VERSION ""

NS_ :

BS_:
BU_: ME SC01 BMS01 BMS PT

BO_ 1664 SC01_DebugFastMpex: 8 SC01
 SG_ selfTestFaultCntrCtrl_SC01 m11 : 23|8@0+ (1,0) [0|0] ""  PT
 SG_ cmbASICFault_SC01 m11 : 15|8@0+ (1,0) [0|0] ""  PT
 SG_ DIGIO_PYRO_LSD_EN_SC01 m2 : 12|1@0+ (1,0) [0|0] ""  PT
 SG_ mainUcExtIsoResistance_SC01 m10 : 55|16@0+ (1,0) [0|0] "KOhm"  PT
 SG_ BMS_C38_AR2MsgFault_SC01 m10 : 47|2@0+ (1,0) [0|0] ""  PT
 SG_ stateCoolant_SC01 m10 : 45|1@0+ (1,0) [0|0] ""  PT
 SG_ stateThermalEvent_SC01 m10 : 44|1@0+ (1,0) [0|0] ""  PT
 SG_ stateCANTx_SC01 m10 : 43|1@0+ (1,0) [0|0] ""  PT
 SG_ CANTxFaultTriggerFailed_SC01 m10 : 42|1@0+ (1,0) [0|0] ""  PT
 SG_ CANTxBMS1ST3MsgFault_SC01 m10 : 10|1@0+ (1,0) [0|0] ""  PT
 SG_ CANTxBMSDispReqMsgFault_SC01 m10 : 9|1@0+ (1,0) [0|0] ""  PT
 SG_ CANTxHVBatMsgFault_SC01 m10 : 8|1@0+ (1,0) [0|0] ""  PT
 SG_ mainUcCntrCtrlReq_SC01 m10 : 41|2@0+ (1,0) [0|0] ""  PT
 SG_ mainUcCntrWeldState_SC01 m10 : 39|4@0+ (1,0) [0|0] ""  PT
 SG_ safetyUcCntrState_SC01 m10 : 33|2@0+ (1,0) [0|0] ""  PT
 SG_ mainUcCntrState_SC01 m10 : 35|2@0+ (1,0) [0|0] ""  PT
 SG_ safetyCANMsg4Fault_SC01 m10 : 31|4@0+ (1,0) [0|0] ""  PT
 SG_ safetyCANMsg3Fault_SC01 m10 : 27|4@0+ (1,0) [0|0] ""  PT
 SG_ safetyCANMsg2Fault_SC01 m10 : 23|4@0+ (1,0) [0|0] ""  PT
 SG_ safetyCANMsg1Fault_SC01 m10 : 19|4@0+ (1,0) [0|0] ""  PT
 SG_ cmbBalancingDesired_SC01 m10 : 15|1@0+ (1,0) [0|0] ""  PT
 SG_ DIGIO_GPIO1_ON_SC01 m2 : 10|1@0+ (1,0) [0|0] ""  PT
 SG_ DIGIO_ZDW_LSD_EN_SC01 m2 : 11|1@0+ (1,0) [0|0] ""  PT
 SG_ currentShortCircuit_SC01 m2 : 9|1@0+ (1,0) [0|0] ""  PT
 SG_ contactorCntrSelfTest_SC01 m10 : 14|4@0+ (1,0) [0|15] ""  PT
 SG_ maxBrickVoltage_SC01 m11 : 39|16@0+ (0.0001,0) [0|6.5] "V"  PT
 SG_ minBrickVoltage_SC01 m11 : 55|16@0+ (0.0001,0) [0|6.5] "V"  PT
 SG_ cmbLastUpdateTime_SC01 m0 : 55|8@0+ (2,0) [0|500] "ms"  PT
 SG_ weldCheckState_SC01 m2 : 15|3@0+ (1,0) [0|0] ""  PT
 SG_ debugFastMpex_SC01 M : 7|8@0+ (1,0) [0|0] ""  PT
 SG_ SPIRxTxTimeAllPckts_SC01 m0 : 63|8@0+ (2,0) [0|500] "ms"  PT
 SG_ sleepRqASW_SC01 m2 : 8|1@0+ (1,0) [0|0] ""  PT
 SG_ prechgCtr1OnReqASW_SC01 m1 : 27|1@0+ (1,0) [0|0] ""  PT
 SG_ negCtr1OnReqASW_SC01 m1 : 25|1@0+ (1,0) [0|0] ""  PT
 SG_ posCtr1OnReqASW_SC01 m1 : 26|1@0+ (1,0) [0|0] ""  PT
 SG_ key_SC01 m1 : 24|1@0+ (1,0) [0|0] ""  PT
 SG_ stateContactorControl_SC01 m0 : 41|1@0+ (1,0) [0|0] ""  PT
 SG_ DIGIO_MULTIPLEX_m101_S3_SC01 m0 : 40|1@0+ (1,0) [0|0] ""  PT
 SG_ analogCntrPwrPlus_SC01 m1 : 15|8@0+ (0.2,0) [0|50] "V"  PT
 SG_ weldedState_SC01 m11 : 25|2@0+ (1,0) [0|3] ""  PT
 SG_ stateVoltage_SC01 m0 : 43|1@0+ (1,0) [0|0] ""  PT
 SG_ stateTemperature_SC01 m0 : 44|1@0+ (1,0) [0|0] ""  PT
 SG_ stateSelfTest_SC01 m0 : 45|1@0+ (1,0) [0|0] ""  PT
 SG_ stateHVIL_SC01 m0 : 46|1@0+ (1,0) [0|0] ""  PT
 SG_ stateCurrent_SC01 m0 : 47|1@0+ (1,0) [0|0] ""  PT
 SG_ stateCrash2_SC01 m0 : 36|1@0+ (1,0) [0|0] ""  PT
 SG_ stateCrash1_SC01 m0 : 37|1@0+ (1,0) [0|0] ""  PT
 SG_ stateContactors_SC01 m0 : 38|1@0+ (1,0) [0|0] ""  PT
 SG_ stateCANRx_SC01 m0 : 39|1@0+ (1,0) [0|0] ""  PT
 SG_ itemState_SC01 m0 : 35|4@0+ (1,0) [0|0] ""  PT
 SG_ DIGIO_SAFETY_GPIO0_SC01 m0 : 8|1@0+ (1,0) [0|0] ""  PT
 SG_ DIGIO_SC_LED501_CONTROL_SC01 m0 : 9|1@0+ (1,0) [0|0] ""  PT
 SG_ DIGIO_LNK_ISO_TST_SW_SC01 m0 : 10|1@0+ (1,0) [0|0] ""  PT
 SG_ DIGIO_SC_LED500_CONTROL_SC01 m0 : 11|1@0+ (1,0) [0|0] ""  PT
 SG_ DIGIO_POS_CNTR1_ON_SC01 m0 : 12|1@0+ (1,0) [0|0] ""  PT
 SG_ DIGIO_NEG_CNTR3_ON_SC01 m0 : 13|1@0+ (1,0) [0|0] ""  PT
 SG_ DIGIO_PRECHG_REL2_ON_SC01 m0 : 14|1@0+ (1,0) [0|0] ""  PT
 SG_ DIGIO_NEG_ISO_TEST_SW_SC01 m0 : 15|1@0+ (1,0) [0|0] ""  PT
 SG_ DIGIO_PRECHG_REL1_ON_SC01 m0 : 16|1@0+ (1,0) [0|0] ""  PT
 SG_ DIGIO_POS_ISO_TEST_SC01 m0 : 17|1@0+ (1,0) [0|0] ""  PT
 SG_ DIGIO_HVIL_PWM_SC01 m0 : 18|1@0+ (1,0) [0|0] ""  PT
 SG_ DIGIO_CNTR_HISIDE_ON_SC_SC01 m0 : 19|1@0+ (1,0) [0|0] ""  PT
 SG_ DIGIO_CRASH_DETECT_SC01 m0 : 20|1@0+ (1,0) [0|0] ""  PT
 SG_ DIGIO_NEG_CNTR2_ON_SC01 m0 : 21|1@0+ (1,0) [0|0] ""  PT
 SG_ DIGIO_NEG_CNTR1_ON_SC01 m0 : 22|1@0+ (1,0) [0|0] ""  PT
 SG_ DIGIO_POS_CNTR3_ON_SC01 m0 : 23|1@0+ (1,0) [0|0] ""  PT
 SG_ DIGIO_POS_CNTR2_ON_SC01 m0 : 24|1@0+ (1,0) [0|0] ""  PT
 SG_ DIGIO_MULTIPLEX_m101_S2_SC01 m0 : 25|1@0+ (1,0) [0|0] ""  PT
 SG_ DIGIO_MULTIPLEX_8TO1_S1_SC01 m0 : 26|1@0+ (1,0) [0|0] ""  PT
 SG_ DIGIO_CNTR_CLOSE_OK_CHCKD_SC01 m0 : 27|1@0+ (1,0) [0|0] ""  PT
 SG_ DIGIO_MULTIPLEX_8TO1_S2_SC01 m0 : 28|1@0+ (1,0) [0|0] ""  PT
 SG_ DIGIO_CNTR_CLOSE_OK_SC01 m0 : 29|1@0+ (1,0) [0|0] ""  PT
 SG_ DIGIO_MULTIPLEX_m101_S1_SC01 m0 : 30|1@0+ (1,0) [0|0] ""  PT
 SG_ DIGIO_CNTR_HISIDE_ON_CHCKD_SC01 m0 : 31|1@0+ (1,0) [0|0] ""  PT
 SG_ posPack_SC01 m2 : 23|16@0+ (0.04,-1250) [-1250|1250] "V"  PT
 SG_ posLink_SC01 m2 : 55|16@0+ (0.04,-1250) [-1250|1371.4] "V"  PT
 SG_ negPack_SC01 m2 : 39|16@0+ (0.04,-1250) [-1250|1250] "V"  PT
 SG_ negLink_SC01 m1 : 39|16@0+ (0.04,-1250) [-1250|1371.4] "V"  PT
 SG_ hallCurrent_SC01 m1 : 23|12@0+ (0.6,-1200) [-1200|1257] "A"  PT
 SG_ analogCntrPwrPlusISense_SC01 m1 : 63|8@0+ (0.05,0) [0|12.5] "A"  PT
 SG_ analogCntrPwrPlusSwitched_SC01 m1 : 55|8@0+ (0.2,0) [0|50] "V"  PT
 SG_ BIT_ANALOG_REF_FAIL_SC01 m3 : 8|1@0+ (1,0) [0|0] ""  PT
 SG_ BIT_ANALOG_ADCDRIVER_FAIL_SC01 m3 : 9|1@0+ (1,0) [0|0] ""  PT
 SG_ BIT_ANALOG_MUX910_HW_SC01 m3 : 10|1@0+ (1,0) [0|0] ""  PT
 SG_ BIT_ANALOG_MUX960_HW_SC01 m3 : 11|1@0+ (1,0) [0|0] ""  PT
 SG_ BIT_ANALOG_MUX301_HW_SC01 m3 : 12|1@0+ (1,0) [0|0] ""  PT
 SG_ BIT_ANALOG_MUX440_HW_SC01 m3 : 13|1@0+ (1,0) [0|0] ""  PT
 SG_ BIT_ANALOG_5VA_FAIL_SC01 m3 : 14|1@0+ (1,0) [0|0] ""  PT
 SG_ BIT_ANALOG_HV_SIGN_SC01 m3 : 15|1@0+ (1,0) [0|0] ""  PT
 SG_ BIT_CAN_ISENSE01_MIA_SC01 m3 : 24|1@0+ (1,0) [0|0] ""  PT
 SG_ BIT_CAN_ISENSE02_MIA_SC01 m3 : 25|1@0+ (1,0) [0|0] ""  PT
 SG_ BIT_CAN_ISENSE03_MIA_SC01 m3 : 26|1@0+ (1,0) [0|0] ""  PT
 SG_ BIT_CAN_ISENSE04_MIA_SC01 m3 : 27|1@0+ (1,0) [0|0] ""  PT
 SG_ BIT_CAN_ISENSE05_MIA_SC01 m3 : 28|1@0+ (1,0) [0|0] ""  PT
 SG_ BIT_CAN_PT_MIA_SC01 m3 : 29|1@0+ (1,0) [0|0] ""  PT
 SG_ BIT_CAN_PT_CRC_SC01 m3 : 30|1@0+ (1,0) [0|0] ""  PT
 SG_ BIT_CAN_PT_ALIVE_SC01 m3 : 31|1@0+ (1,0) [0|0] ""  PT
 SG_ BIT_CAN_SAFETYLIN_MIA_SC01 m3 : 32|1@0+ (1,0) [0|0] ""  PT
 SG_ BIT_CAN_SAFETYLIN_SHUTDOWN_SC01 m3 : 33|1@0+ (1,0) [0|0] ""  PT
 SG_ BIT_CMB_GPIO_SHORT_SC01 m3 : 40|1@0+ (1,0) [0|0] ""  PT
 SG_ BIT_CMB_C2S_LEAK_SC01 m3 : 41|1@0+ (1,0) [0|0] ""  PT
 SG_ BIT_CMB_SENSE_LINE_SC01 m3 : 42|1@0+ (1,0) [0|0] ""  PT
 SG_ BIT_CMB_SUMOFCELL_CHECK_SC01 m3 : 43|1@0+ (1,0) [0|0] ""  PT
 SG_ BIT_CMB_DRIVER_TIMING_SC01 m3 : 44|1@0+ (1,0) [0|0] ""  PT
 SG_ BIT_CMB_CLEAR_SC01 m3 : 45|1@0+ (1,0) [0|0] ""  PT
 SG_ BIT_CMB_SELFTEST_SC01 m3 : 46|1@0+ (1,0) [0|0] ""  PT
 SG_ BIT_CMB_GPIO_OPEN_SC01 m3 : 47|1@0+ (1,0) [0|0] ""  PT
 SG_ BIT_CMB_CELLV_RANGE_ERR_SC01 m3 : 48|1@0+ (1,0) [0|0] ""  PT
 SG_ BIT_CMB_ADOL_CHECK_SC01 m3 : 49|1@0+ (1,0) [0|0] ""  PT
 SG_ BIT_CMB_BALANCING_STUCK_SC01 m3 : 50|1@0+ (1,0) [0|0] ""  PT
 SG_ BIT_CMB_SUPPLY_SC01 m3 : 51|1@0+ (1,0) [0|0] ""  PT
 SG_ BIT_CMB_DEFECT_SC01 m3 : 52|1@0+ (1,0) [0|0] ""  PT
 SG_ BIT_CMB_PEC_ERROR_SC01 m3 : 53|1@0+ (1,0) [0|0] ""  PT
 SG_ BIT_CMB_GPIO_ERROR_SC01 m3 : 54|1@0+ (1,0) [0|0] ""  PT
 SG_ BIT_CMB_DIGTLREDNCY_LF_SC01 m3 : 55|1@0+ (1,0) [0|0] ""  PT
 SG_ BIT_CCTRL_SELFTEST_SC01 m4 : 8|1@0+ (1,0) [0|0] ""  PT
 SG_ BIT_CCTRL_DRIVER_FAULT_SC01 m4 : 9|1@0+ (1,0) [0|0] ""  PT
 SG_ BIT_CCTRL_HISIDE_STCLSD_SC01 m4 : 10|1@0+ (1,0) [0|0] ""  PT
 SG_ BIT_CCTRL_LOSIDE_STCLSD_SC01 m4 : 11|1@0+ (1,0) [0|0] ""  PT
 SG_ BIT_CCTRL_HISIDE_STUCK_OPEN_SC01 m4 : 12|1@0+ (1,0) [0|0] ""  PT
 SG_ BIT_CCTRL_HVOLTAGE_COND_SC01 m4 : 13|1@0+ (1,0) [0|0] ""  PT
 SG_ BIT_CCTRL_POS1_OPENCIRC_SC01 m4 : 14|1@0+ (1,0) [0|0] ""  PT
 SG_ BIT_CCTRL_NEG1_OPENCIRC_SC01 m4 : 15|1@0+ (1,0) [0|0] ""  PT
 SG_ BIT_CCTRL_PRECHG1_OPENCIRC_SC01 m4 : 16|1@0+ (1,0) [0|0] ""  PT
 SG_ BIT_CCTRL_POS2_OPENCIRC_SC01 m4 : 17|1@0+ (1,0) [0|0] ""  PT
 SG_ BIT_CCTRL_NEG2_OPENCIRC_SC01 m4 : 18|1@0+ (1,0) [0|0] ""  PT
 SG_ BIT_CCTRL_LOSDE_STOPEN_SC01 m4 : 19|1@0+ (1,0) [0|0] ""  PT
 SG_ BIT_CCTRL_POS3_OPENCIRC_SC01 m4 : 20|1@0+ (1,0) [0|0] ""  PT
 SG_ BIT_CCTRL_PRECHG2_OPENCIRC_SC01 m4 : 21|1@0+ (1,0) [0|0] ""  PT
 SG_ BIT_CCTRL_ITEM_OFF_OPEN_SC01 m4 : 22|1@0+ (1,0) [0|0] ""  PT
 SG_ BIT_CCTRL_UNEXPECTED_OPEN_SC01 m4 : 23|1@0+ (1,0) [0|0] ""  PT
 SG_ BIT_CNTR_ISOLATION_SC01 m4 : 24|1@0+ (1,0) [0|0] ""  PT
 SG_ BIT_CNTR_ISO_AND_POT_WELD_SC01 m4 : 25|1@0+ (1,0) [0|0] ""  PT
 SG_ BIT_CNTR_POS1_WELDED_SC01 m4 : 26|1@0+ (1,0) [0|0] ""  PT
 SG_ BIT_CNTR_NEG1_WELDED_SC01 m4 : 27|1@0+ (1,0) [0|0] ""  PT
 SG_ BIT_CNTR_POS2_WELDED_SC01 m4 : 28|1@0+ (1,0) [0|0] ""  PT
 SG_ BIT_CNTR_NEG2_WELDED_SC01 m4 : 29|1@0+ (1,0) [0|0] ""  PT
 SG_ BIT_CNTR_POS3_WELDED_SC01 m4 : 30|1@0+ (1,0) [0|0] ""  PT
 SG_ BIT_CNTR_NEG3_WELDED_SC01 m4 : 31|1@0+ (1,0) [0|0] ""  PT
 SG_ BIT_CNTR_P_ANDOR_N_WELD_SC01 m4 : 32|1@0+ (1,0) [0|0] ""  PT
 SG_ BIT_CNTR_HIGH_CY_SC01 m4 : 33|1@0+ (1,0) [0|0] ""  PT
 SG_ BIT_CNTR_WELDCHECK_TIMEOUT_SC01 m4 : 34|1@0+ (1,0) [0|0] ""  PT
 SG_ BIT_CURRENT_PLAUSIBILITY_SC01 m4 : 40|1@0+ (1,0) [0|0] ""  PT
 SG_ BIT_CURRENT_OVERCHARGE_SC01 m4 : 41|1@0+ (1,0) [0|0] ""  PT
 SG_ BIT_CURRENT_OVERDISCHARGE_SC01 m4 : 42|1@0+ (1,0) [0|0] ""  PT
 SG_ BIT_CURRENT_ISENSE1_INVALID_SC01 m4 : 43|1@0+ (1,0) [0|0] ""  PT
 SG_ BIT_CURRENT_ISENSE2_INVALID_SC01 m4 : 44|1@0+ (1,0) [0|0] ""  PT
 SG_ BIT_CURRENT_ISENSE3_INVALID_SC01 m4 : 45|1@0+ (1,0) [0|0] ""  PT
 SG_ BIT_CURRENT_ISENSE4_INVALID_SC01 m4 : 46|1@0+ (1,0) [0|0] ""  PT
 SG_ BIT_CURRENT_ISENSE5_INVALID_SC01 m4 : 47|1@0+ (1,0) [0|0] ""  PT
 SG_ BIT_CURRENT_HALL_INVALID_SC01 m4 : 48|1@0+ (1,0) [0|0] ""  PT
 SG_ BIT_CURRENT_OFFSET_FAULT_SC01 m4 : 49|1@0+ (1,0) [0|0] ""  PT
 SG_ BIT_FLUXGATE1_CURRENT_FAULT_SC01 m5 : 8|1@0+ (1,0) [0|0] ""  PT
 SG_ BIT_FLUXGATE_12V_LOW_SC01 m5 : 18|1@0+ (1,0) [0|0] ""  PT
 SG_ BIT_HALL_INVALID_SC01 m5 : 24|1@0+ (1,0) [0|0] ""  PT
 SG_ BIT_HALL_PWR_FAIL_LO_SC01 m5 : 25|1@0+ (1,0) [0|0] ""  PT
 SG_ BIT_HALL_SENSELO_SC01 m5 : 26|1@0+ (1,0) [0|0] ""  PT
 SG_ BIT_HALL_SENSEHI_SC01 m5 : 27|1@0+ (1,0) [0|0] ""  PT
 SG_ BIT_HVIL_HW_FAULT_SC01 m5 : 40|1@0+ (1,0) [0|0] ""  PT
 SG_ BIT_HVIL_OPEN_CIRCUIT_SC01 m5 : 41|1@0+ (1,0) [0|0] ""  PT
 SG_ BIT_HVIL_SHORT_SUPPLY_SC01 m5 : 42|1@0+ (1,0) [0|0] ""  PT
 SG_ BIT_HVIL_SHORT_CHASSIS_SC01 m5 : 43|1@0+ (1,0) [0|0] ""  PT
 SG_ BIT_HVIL_RESISTANCE_HIGH_SC01 m5 : 44|1@0+ (1,0) [0|0] ""  PT
 SG_ BIT_HVIL_SHORT_CIRCUIT_SC01 m5 : 45|1@0+ (1,0) [0|0] ""  PT
 SG_ BIT_ISASHUNT1_CURRENT_FAULT_SC01 m7 : 24|1@0+ (1,0) [0|0] ""  PT
 SG_ BIT_ISASHUNT2_CURRENT_FAULT_SC01 m7 : 25|1@0+ (1,0) [0|0] ""  PT
 SG_ BIT_ISASHUNT3_CURRENT_FAULT_SC01 m7 : 26|1@0+ (1,0) [0|0] ""  PT
 SG_ BIT_ISASHUNT4_CURRENT_FAULT_SC01 m7 : 27|1@0+ (1,0) [0|0] ""  PT
 SG_ BIT_ISASHUNT5_CURRENT_FAULT_SC01 m7 : 28|1@0+ (1,0) [0|0] ""  PT
 SG_ BIT_ISASHUNT1_CHARGE_FAULT_SC01 m7 : 29|1@0+ (1,0) [0|0] ""  PT
 SG_ BIT_ISASHUNT2_CHARGE_FAULT_SC01 m7 : 30|1@0+ (1,0) [0|0] ""  PT
 SG_ BIT_ISASHUNT3_CHARGE_FAULT_SC01 m7 : 31|1@0+ (1,0) [0|0] ""  PT
 SG_ BIT_ISASHUNT4_CHARGE_FAULT_SC01 m7 : 32|1@0+ (1,0) [0|0] ""  PT
 SG_ BIT_ISASHUNT5_CHARGE_FAULT_SC01 m7 : 33|1@0+ (1,0) [0|0] ""  PT
 SG_ BIT_ISASHUNT_SUPPLY_LOW_SC01 m7 : 34|1@0+ (1,0) [0|0] ""  PT
 SG_ BIT_LINK_POS_HW_FAIL_SC01 m7 : 40|1@0+ (1,0) [0|0] ""  PT
 SG_ BIT_LINK_NEG_HW_FAIL_SC01 m7 : 41|1@0+ (1,0) [0|0] ""  PT
 SG_ BIT_PUMP_LIN_FAILURE_SC01 m8 : 8|1@0+ (1,0) [0|0] ""  PT
 SG_ BIT_PUMP_OVERTEMPERATURE_SC01 m8 : 9|1@0+ (1,0) [0|0] ""  PT
 SG_ BIT_PUMP_SPEED_HIGH_SC01 m8 : 10|1@0+ (1,0) [0|0] ""  PT
 SG_ BIT_PUMP_SPEED_LOW_SC01 m8 : 11|1@0+ (1,0) [0|0] ""  PT
 SG_ BIT_PUMP_DRY_RUN_SC01 m8 : 12|1@0+ (1,0) [0|0] ""  PT
 SG_ BIT_SBC_VCORE_OOR_SC01 m6 : 8|1@0+ (1,0) [0|0] ""  PT
 SG_ BIT_SBC_SELFTEST_SC01 m6 : 9|1@0+ (1,0) [0|0] ""  PT
 SG_ BIT_SBC_INIT_SC01 m6 : 10|1@0+ (1,0) [0|0] ""  PT
 SG_ BIT_SBC_WATCHDOG_SC01 m6 : 11|1@0+ (1,0) [0|0] ""  PT
 SG_ BIT_SBC_FECBITFLIP_SC01 m6 : 12|1@0+ (1,0) [0|0] ""  PT
 SG_ BIT_SBC_VREUV_SC01 m6 : 13|1@0+ (1,0) [0|0] ""  PT
 SG_ BIT_SBC_FAILSAFE_SC01 m6 : 14|1@0+ (1,0) [0|0] ""  PT
 SG_ BIT_SBC_VAUX_OOR_SC01 m6 : 15|1@0+ (1,0) [0|0] ""  PT
 SG_ BIT_SBC_VCCA_OOR_SC01 m6 : 16|1@0+ (1,0) [0|0] ""  PT
 SG_ BIT_SBC_FCRBM_OOR_SC01 m6 : 17|1@0+ (1,0) [0|0] ""  PT
 SG_ BIT_SBC_FLT_ERR_CNTR_SC01 m6 : 18|1@0+ (1,0) [0|0] ""  PT
 SG_ BIT_SBC_FS0B_FAIL_SC01 m6 : 19|1@0+ (1,0) [0|0] ""  PT
 SG_ BIT_SBC_SPI_ERRORS_SC01 m6 : 20|1@0+ (1,0) [0|0] ""  PT
 SG_ BIT_SBC_SPI_TX_FAIL_SC01 m6 : 21|1@0+ (1,0) [0|0] ""  PT
 SG_ BIT_SBC_NERROR_ACTIVE_SC01 m6 : 22|1@0+ (1,0) [0|0] ""  PT
 SG_ BIT_SELFTEST_RAM_SC01 m6 : 24|1@0+ (1,0) [0|0] ""  PT
 SG_ BIT_SELFTEST_FLASH_SC01 m6 : 25|1@0+ (1,0) [0|0] ""  PT
 SG_ BIT_SELFTEST_CLOCK_SC01 m6 : 26|1@0+ (1,0) [0|0] ""  PT
 SG_ BIT_SELFTEST_WATCHDOG_SC01 m6 : 27|1@0+ (1,0) [0|0] ""  PT
 SG_ BIT_SELFTEST_STACK_SC01 m6 : 28|1@0+ (1,0) [0|0] ""  PT
 SG_ BIT_SELFTEST_L2L3_SC01 m6 : 29|1@0+ (1,0) [0|0] ""  PT
 SG_ BIT_SELFTEST_EFUSE_SC01 m6 : 30|1@0+ (1,0) [0|0] ""  PT
 SG_ BIT_SELFTEST_EXCEPTION_SC01 m6 : 31|1@0+ (1,0) [0|0] ""  PT
 SG_ BIT_SELFTEST_5VD_FAIL_SC01 m6 : 32|1@0+ (1,0) [0|0] ""  PT
 SG_ BIT_SELFTEST_VIM_SC01 m6 : 33|1@0+ (1,0) [0|0] ""  PT
 SG_ BIT_SELFTEST_TASKTIME_SC01 m6 : 34|1@0+ (1,0) [0|0] ""  PT
 SG_ BIT_SELFTEST_RTI_SC01 m6 : 35|1@0+ (1,0) [0|0] ""  PT
 SG_ BIT_SELFTEST_ESM_SC01 m6 : 36|1@0+ (1,0) [0|0] ""  PT
 SG_ BIT_SELFTEST_IOM_SC01 m6 : 37|1@0+ (1,0) [0|0] ""  PT
 SG_ BIT_SELFTEST_SBC_SC01 m6 : 38|1@0+ (1,0) [0|0] ""  PT
 SG_ BIT_SELFTEST_STARTUP_SC01 m6 : 39|1@0+ (1,0) [0|0] ""  PT
 SG_ BIT_TEMP_MODULEOVERTEMP_SC01 m6 : 40|1@0+ (1,0) [0|0] ""  PT
 SG_ BIT_TEMP_MODULETEMP_INVALID_SC01 m6 : 41|1@0+ (1,0) [0|0] ""  PT
 SG_ BIT_TEMP_NTC_OPENWIRE_SC01 m6 : 42|1@0+ (1,0) [0|0] ""  PT
 SG_ BIT_TEMP_NTC_SHORT_SC01 m6 : 43|1@0+ (1,0) [0|0] ""  PT
 SG_ BIT_TEMP_PLAUSIBILITY_SC01 m6 : 44|1@0+ (1,0) [0|0] ""  PT
 SG_ BIT_VOLTAGE_BRICKV_INVALID_SC01 m7 : 8|1@0+ (1,0) [0|0] ""  PT
 SG_ BIT_VOLTAGE_BRICKUV_SC01 m7 : 9|1@0+ (1,0) [0|0] ""  PT
 SG_ BIT_VOLTAGE_BRICKOV_SC01 m7 : 10|1@0+ (1,0) [0|0] ""  PT
 SG_ BIT_VOLTAGE_BRICKDEEPDSCHG_SC01 m7 : 11|1@0+ (1,0) [0|0] ""  PT
 SG_ BIT_VOLTAGE_PACKV_INVALID_SC01 m7 : 12|1@0+ (1,0) [0|0] ""  PT
 SG_ BIT_VOLTAGE_PLAUSIBILITY_SC01 m7 : 13|1@0+ (1,0) [0|0] ""  PT
 SG_ BIT_VOLTAGE_CMB_PLAUSI_SC01 m7 : 14|1@0+ (1,0) [0|0] ""  PT
 SG_ BIT_VOLTAGE_SENSE_OPENWIRE_SC01 m7 : 15|1@0+ (1,0) [0|0] ""  PT
 SG_ BIT_VOLTAGE_BRICKV_FROZEN_SC01 m7 : 16|1@0+ (1,0) [0|0] ""  PT
 SG_ BIT_PUMP_BLOCK_SC01 m8 : 13|1@0+ (1,0) [0|0] ""  PT
 SG_ BIT_PUMP_SUPPLY_SC01 m8 : 14|1@0+ (1,0) [0|0] ""  PT
 SG_ BIT_PUMP_OVERCURRENT_SC01 m8 : 15|1@0+ (1,0) [0|0] ""  PT
 SG_ BIT_PUMP_ELECTRIC_SC01 m8 : 16|1@0+ (1,0) [0|0] ""  PT
 SG_ BIT_PUMP_RS_SC01 m8 : 17|1@0+ (1,0) [0|0] ""  PT
 SG_ BIT_HALL_PWR_FAIL_HI_SC01 m5 : 28|1@0+ (1,0) [0|0] ""  PT
 SG_ BIT_VOLTAGE_OUT_OF_RANGE_SC01 m7 : 17|1@0+ (1,0) [0|0] ""  PT
 SG_ BIT_ISO_OFF_TIME_SHORT_SC01 m8 : 24|1@0+ (1,0) [0|0] ""  PT
 SG_ BIT_ISO_ON_TIME_SHORT_SC01 m8 : 25|1@0+ (1,0) [0|0] ""  PT
 SG_ BIT_ISO_INTERNAL_INACTIVE_SC01 m8 : 26|1@0+ (1,0) [0|0] ""  PT
 SG_ BIT_ISO_SW_STATE_INVALID_SC01 m8 : 27|1@0+ (1,0) [0|0] ""  PT
 SG_ BIT_ISO_PACKV_SNA_SWOFF_SC01 m8 : 28|1@0+ (1,0) [0|0] ""  PT
 SG_ BIT_ISO_PACKV_SNA_SWON_SC01 m8 : 29|1@0+ (1,0) [0|0] ""  PT
 SG_ BIT_ISO_EXTERNAL_INACTIVE_SC01 m8 : 30|1@0+ (1,0) [0|0] ""  PT
 SG_ BIT_CANTX_CNTR_STAT_FAULT_SC01 m8 : 40|1@0+ (1,0) [0|0] ""  PT
 SG_ BIT_CANTX_CNTR_WELD_FAULT_SC01 m8 : 41|1@0+ (1,0) [0|0] ""  PT
 SG_ BIT_CANTX_THERMAL_FAULT_SC01 m8 : 42|1@0+ (1,0) [0|0] ""  PT
 SG_ BIT_CANTX_ISOLATION_FAULT_SC01 m8 : 43|1@0+ (1,0) [0|0] ""  PT
 SG_ BIT_CANTX_HVIL_FAULT_SC01 m8 : 44|1@0+ (1,0) [0|0] ""  PT
 SG_ BIT_VOLTAGE_STATELATCHED_SC01 m7 : 18|1@0+ (1,0) [0|0] ""  PT
 SG_ BIT_CANTX_ISOLATION_PREFLT_SC01 m8 : 45|1@0+ (1,0) [0|0] ""  PT
 SG_ BIT_CANTX_FLTRIGGER_FAILED_SC01 m8 : 46|1@0+ (1,0) [0|0] ""  PT
 SG_ BIT_ISO_TEST_SWITCH_FAULT_SC01 m8 : 31|1@0+ (1,0) [0|0] ""  PT
 SG_ BIT_THERMAL_ADC_FAULT_SC01 m9 : 8|1@0+ (1,0) [0|0] ""  PT
 SG_ BIT_THERMAL_PRESSURE_VHI_SC01 m9 : 9|1@0+ (1,0) [0|0] ""  PT
 SG_ BIT_THERMAL_PRESSURE_VLO_SC01 m9 : 10|1@0+ (1,0) [0|0] ""  PT
 SG_ BIT_THERMAL_PRIMARY_EVT_SC01 m9 : 11|1@0+ (1,0) [0|0] ""  PT
 SG_ BIT_THERMAL_SECONRY_EVT_SC01 m9 : 12|1@0+ (1,0) [0|0] ""  PT
 SG_ BIT_THERMAL_PRESSURE_INV_SC01 m9 : 13|1@0+ (1,0) [0|0] ""  PT
 SG_ BIT_THERMAL_EVTLATCHED_SC01 m9 : 14|1@0+ (1,0) [0|0] ""  PT
 SG_ BIT_COOLANT_CANMIA_SC01 m9 : 24|1@0+ (1,0) [0|0] ""  PT
 SG_ BIT_COOLANT_SENSRFAIL_SC01 m9 : 25|1@0+ (1,0) [0|0] ""  PT
 SG_ BIT_COOLANT_WATERDETCD_SC01 m9 : 26|1@0+ (1,0) [0|0] ""  PT
 SG_ BIT_COOLANT_LATCHED_SC01 m9 : 27|1@0+ (1,0) [0|0] ""  PT
 SG_ BIT_ANALOG_PULLUP_DSBLD_SC01 m3 : 17|1@0+ (1,0) [0|0] ""  PT
 SG_ BIT_ANALOG_PULLUP_DSBLRQ_SC01 m3 : 16|1@0+ (1,0) [0|0] ""  PT
 SG_ BIT_SBC_REG_ERROR_SC01 m6 : 23|1@0+ (1,0) [0|0] ""  PT
 SG_ BIT_CURRENT_LATCHED_SC01 m4 : 50|1@0+ (1,0) [0|0] ""  PT
 SG_ BIT_TEMP_LATCHED_SC01 m6 : 45|1@0+ (1,0) [0|0] ""  PT
 SG_ BIT_ISO_PLAUSI_SWOFF_SC01 m8 : 32|1@0+ (1,0) [0|0] ""  PT
 SG_ BIT_ISO_PLAUSI_SWON_SC01 m8 : 33|1@0+ (1,0) [0|0] ""  PT
 SG_ BIT_ISO_RELAXED_INACTIVE_SC01 m8 : 34|1@0+ (1,0) [0|0] ""  PT
 SG_ BIT_THERMAL_PRESSURE_MIA_SC01 m9 : 15|1@0+ (1,0) [0|0] ""  PT
 SG_ BIT_LINK_PACK_MISMATCH_SC01 m7 : 42|1@0+ (1,0) [0|0] ""  PT
 SG_ BIT_CAN_PT_EMERGENCY_SC01 m3 : 34|1@0+ (1,0) [0|0] ""  PT
 SG_ BIT_THERMAL_PRES_SUPPLY_OOR_SC01 m9 : 16|1@0+ (1,0) [0|0] ""  PT
 SG_ BIT_CAN_SM_DISABLE_SC01 m3 : 35|1@0+ (1,0) [0|0] ""  PT
 SG_ BIT_THERMAL_PRESSURE_FLT_SC01 m9 : 17|1@0+ (1,0) [0|0] ""  PT
 SG_ BIT_CURRENT_SENSOR_FAULT_SC01 m9 : 40|1@0+ (1,0) [0|0] ""  PT
 SG_ BIT_CURRENT_SENSOR_CHARGE_FAULT_SC01 m9 : 45|1@0+ (1,0) [0|0] ""  PT
 SG_ BIT_CURRENT_SENSOR_SUP_LOW_SC01 m9 : 50|1@0+ (1,0) [0|0] ""  PT
 SG_ BIT_THERMAL_H2SENSE_FAULT_SC01 m9 : 18|1@0+ (1,0) [0|0] ""  PT
 SG_ BIT_VOLTAGE_BRICKCOUNT_INVALID_SC01 m7 : 19|1@0+ (1,0) [0|0] ""  PT

BO_ 1920 BMS01_DebugOnboard: 7 BMS01
 SG_ cmbCoolantTemp08_BMS01 m8 : 55|8@0+ (1,-40) [-40|200] "C"  PT
 SG_ cmbCoolantTemp07_BMS01 m7 : 55|8@0+ (1,-40) [-40|200] "C"  PT
 SG_ cmbCoolantTemp06_BMS01 m6 : 55|8@0+ (1,-40) [-40|200] "C"  PT
 SG_ cmbCoolantTemp05_BMS01 m5 : 55|8@0+ (1,-40) [-40|200] "C"  PT
 SG_ cmbCoolantTemp04_BMS01 m4 : 55|8@0+ (1,-40) [-40|200] "C"  PT
 SG_ cmbCoolantTemp03_BMS01 m3 : 55|8@0+ (1,-40) [-40|200] "C"  PT
 SG_ cmbCoolantTemp02_BMS01 m2 : 55|8@0+ (1,-40) [-40|200] "C"  PT
 SG_ cmbCoolantTemp01_BMS01 m1 : 55|8@0+ (1,-40) [-40|200] "C"  PT
 SG_ cmbOnboardPressure32_BMS01 m32 : 39|16@0+ (1,0) [0|600] "kPa"  PT
 SG_ cmbOnboardPressure31_BMS01 m31 : 39|16@0+ (1,0) [0|600] "kPa"  PT
 SG_ cmbOnboardPressure30_BMS01 m30 : 39|16@0+ (1,0) [0|600] "kPa"  PT
 SG_ cmbOnboardPressure29_BMS01 m29 : 39|16@0+ (1,0) [0|600] "kPa"  PT
 SG_ cmbOnboardPressure28_BMS01 m28 : 39|16@0+ (1,0) [0|600] "kPa"  PT
 SG_ cmbOnboardPressure27_BMS01 m27 : 39|16@0+ (1,0) [0|600] "kPa"  PT
 SG_ cmbOnboardPressure26_BMS01 m26 : 39|16@0+ (1,0) [0|600] "kPa"  PT
 SG_ cmbOnboardPressure25_BMS01 m25 : 39|16@0+ (1,0) [0|600] "kPa"  PT
 SG_ cmbOnboardPressure24_BMS01 m24 : 39|16@0+ (1,0) [0|600] "kPa"  PT
 SG_ cmbOnboardPressure23_BMS01 m23 : 39|16@0+ (1,0) [0|600] "kPa"  PT
 SG_ cmbOnboardPressure22_BMS01 m22 : 39|16@0+ (1,0) [0|600] "kPa"  PT
 SG_ cmbOnboardPressure21_BMS01 m21 : 39|16@0+ (1,0) [0|600] "kPa"  PT
 SG_ cmbOnboardPressure20_BMS01 m20 : 39|16@0+ (1,0) [0|600] "kPa"  PT
 SG_ cmbOnboardPressure19_BMS01 m19 : 39|16@0+ (1,0) [0|600] "kPa"  PT
 SG_ cmbOnboardPressure18_BMS01 m18 : 39|16@0+ (1,0) [0|600] "kPa"  PT
 SG_ cmbOnboardPressure17_BMS01 m17 : 39|16@0+ (1,0) [0|600] "kPa"  PT
 SG_ cmbOnboardPressure16_BMS01 m16 : 39|16@0+ (1,0) [0|600] "kPa"  PT
 SG_ cmbOnboardPressure15_BMS01 m15 : 39|16@0+ (1,0) [0|600] "kPa"  PT
 SG_ cmbOnboardPressure14_BMS01 m14 : 39|16@0+ (1,0) [0|600] "kPa"  PT
 SG_ cmbOnboardPressure13_BMS01 m13 : 39|16@0+ (1,0) [0|600] "kPa"  PT
 SG_ cmbOnboardPressure12_BMS01 m12 : 39|16@0+ (1,0) [0|600] "kPa"  PT
 SG_ cmbOnboardPressure11_BMS01 m11 : 39|16@0+ (1,0) [0|600] "kPa"  PT
 SG_ cmbOnboardPressure10_BMS01 m10 : 39|16@0+ (1,0) [0|600] "kPa"  PT
 SG_ cmbOnboardPressure09_BMS01 m9 : 39|16@0+ (1,0) [0|600] "kPa"  PT
 SG_ cmbOnboardPressure08_BMS01 m8 : 39|16@0+ (1,0) [0|600] "kPa"  PT
 SG_ cmbOnboardPressure07_BMS01 m7 : 39|16@0+ (1,0) [0|600] "kPa"  PT
 SG_ cmbOnboardPressure06_BMS01 m6 : 39|16@0+ (1,0) [0|600] "kPa"  PT
 SG_ cmbOnboardPressure05_BMS01 m5 : 39|16@0+ (1,0) [0|600] "kPa"  PT
 SG_ cmbOnboardPressure04_BMS01 m4 : 39|16@0+ (1,0) [0|600] "kPa"  PT
 SG_ cmbOnboardPressure03_BMS01 m3 : 39|16@0+ (1,0) [0|600] "kPa"  PT
 SG_ cmbOnboardPressure02_BMS01 m2 : 39|16@0+ (1,0) [0|600] "kPa"  PT
 SG_ cmbOnboardPressure01_BMS01 m1 : 39|16@0+ (1,0) [0|600] "kPa"  PT
 SG_ onboardMultiplexor_BMS01 M : 7|8@0+ (1,0) [0|0] ""  PT
 SG_ minCmbOnboardTemperature_BMS01 m0 : 31|8@0+ (1,-40) [-40|200] "C"  PT
 SG_ minCmbOnboardHumidity_BMS01 m0 : 47|8@0+ (0.5,0) [0|120] "PCT"  PT
 SG_ maxCmbOnboardTemperature_BMS01 m0 : 39|8@0+ (1,-40) [-40|200] "C"  PT
 SG_ maxCmbOnboardHumidity_BMS01 m0 : 55|8@0+ (0.5,0) [0|120] "PCT"  PT
 SG_ bmsOnboardTemperature_BMS01 m0 : 15|8@0+ (1,-40) [-40|200] "C"  PT
 SG_ bmsOnboardHumidity_BMS01 m0 : 23|8@0+ (0.5,0) [0|120] "PCT"  PT
 SG_ cmbOnboardTemperature01_BMS01 m1 : 15|8@0+ (1,-40) [-40|200] "C"  PT
 SG_ cmbOnboardHumidity01_BMS01 m1 : 23|8@0+ (0.5,0) [0|120] "PCT"  PT
 SG_ moduleHeaterCurrent01_BMS01 m1 : 31|8@0+ (0.05,0) [0|10] "A"  PT
 SG_ cmbOnboardTemperature02_BMS01 m2 : 15|8@0+ (1,-40) [-40|200] "C"  PT
 SG_ cmbOnboardHumidity02_BMS01 m2 : 23|8@0+ (0.5,0) [0|120] "PCT"  PT
 SG_ moduleHeaterCurrent02_BMS01 m2 : 31|8@0+ (0.05,0) [0|10] "A"  PT
 SG_ cmbOnboardTemperature03_BMS01 m3 : 15|8@0+ (1,-40) [-40|200] "C"  PT
 SG_ cmbOnboardHumidity03_BMS01 m3 : 23|8@0+ (0.5,0) [0|120] "PCT"  PT
 SG_ moduleHeaterCurrent03_BMS01 m3 : 31|8@0+ (0.05,0) [0|10] "A"  PT
 SG_ cmbOnboardTemperature04_BMS01 m4 : 15|8@0+ (1,-40) [-40|200] "C"  PT
 SG_ cmbOnboardHumidity04_BMS01 m4 : 23|8@0+ (0.5,0) [0|120] "PCT"  PT
 SG_ moduleHeaterCurrent04_BMS01 m4 : 31|8@0+ (0.05,0) [0|10] "A"  PT
 SG_ cmbOnboardTemperature05_BMS01 m5 : 15|8@0+ (1,-40) [-40|200] "C"  PT
 SG_ cmbOnboardHumidity05_BMS01 m5 : 23|8@0+ (0.5,0) [0|120] "PCT"  PT
 SG_ moduleHeaterCurrent05_BMS01 m5 : 31|8@0+ (0.05,0) [0|10] "A"  PT
 SG_ cmbOnboardTemperature06_BMS01 m6 : 15|8@0+ (1,-40) [-40|200] "C"  PT
 SG_ cmbOnboardHumidity06_BMS01 m6 : 23|8@0+ (0.5,0) [0|120] "PCT"  PT
 SG_ moduleHeaterCurrent06_BMS01 m6 : 31|8@0+ (0.05,0) [0|10] "A"  PT
 SG_ cmbOnboardTemperature07_BMS01 m7 : 15|8@0+ (1,-40) [-40|200] "C"  PT
 SG_ cmbOnboardHumidity07_BMS01 m7 : 23|8@0+ (0.5,0) [0|120] "PCT"  PT
 SG_ moduleHeaterCurrent07_BMS01 m7 : 31|8@0+ (0.05,0) [0|10] "A"  PT
 SG_ cmbOnboardTemperature08_BMS01 m8 : 15|8@0+ (1,-40) [-40|200] "C"  PT
 SG_ cmbOnboardHumidity08_BMS01 m8 : 23|8@0+ (0.5,0) [0|120] "PCT"  PT
 SG_ moduleHeaterCurrent08_BMS01 m8 : 31|8@0+ (0.05,0) [0|10] "A"  PT
 SG_ cmbOnboardTemperature09_BMS01 m9 : 15|8@0+ (1,-40) [-40|200] "C"  PT
 SG_ cmbOnboardHumidity09_BMS01 m9 : 23|8@0+ (0.5,0) [0|120] "PCT"  PT
 SG_ moduleHeaterCurrent09_BMS01 m9 : 31|8@0+ (0.05,0) [0|10] "A"  PT
 SG_ cmbOnboardTemperature10_BMS01 m10 : 15|8@0+ (1,-40) [-40|200] "C"  PT
 SG_ cmbOnboardHumidity10_BMS01 m10 : 23|8@0+ (0.5,0) [0|120] "PCT"  PT
 SG_ moduleHeaterCurrent10_BMS01 m10 : 31|8@0+ (0.05,0) [0|10] "A"  PT
 SG_ cmbOnboardTemperature11_BMS01 m11 : 15|8@0+ (1,-40) [-40|200] "C"  PT
 SG_ cmbOnboardHumidity11_BMS01 m11 : 23|8@0+ (0.5,0) [0|120] "PCT"  PT
 SG_ moduleHeaterCurrent11_BMS01 m11 : 31|8@0+ (0.05,0) [0|10] "A"  PT
 SG_ cmbOnboardTemperature12_BMS01 m12 : 15|8@0+ (1,-40) [-40|200] "C"  PT
 SG_ cmbOnboardHumidity12_BMS01 m12 : 23|8@0+ (0.5,0) [0|120] "PCT"  PT
 SG_ moduleHeaterCurrent12_BMS01 m12 : 31|8@0+ (0.05,0) [0|10] "A"  PT
 SG_ cmbOnboardTemperature13_BMS01 m13 : 15|8@0+ (1,-40) [-40|200] "C"  PT
 SG_ cmbOnboardHumidity13_BMS01 m13 : 23|8@0+ (0.5,0) [0|120] "PCT"  PT
 SG_ moduleHeaterCurrent13_BMS01 m13 : 31|8@0+ (0.05,0) [0|10] "A"  PT
 SG_ cmbOnboardTemperature14_BMS01 m14 : 15|8@0+ (1,-40) [-40|200] "C"  PT
 SG_ cmbOnboardHumidity14_BMS01 m14 : 23|8@0+ (0.5,0) [0|120] "PCT"  PT
 SG_ moduleHeaterCurrent14_BMS01 m14 : 31|8@0+ (0.05,0) [0|10] "A"  PT
 SG_ cmbOnboardTemperature15_BMS01 m15 : 15|8@0+ (1,-40) [-40|200] "C"  PT
 SG_ cmbOnboardHumidity15_BMS01 m15 : 23|8@0+ (0.5,0) [0|120] "PCT"  PT
 SG_ moduleHeaterCurrent15_BMS01 m15 : 31|8@0+ (0.05,0) [0|10] "A"  PT
 SG_ cmbOnboardTemperature16_BMS01 m16 : 15|8@0+ (1,-40) [-40|200] "C"  PT
 SG_ cmbOnboardHumidity16_BMS01 m16 : 23|8@0+ (0.5,0) [0|120] "PCT"  PT
 SG_ moduleHeaterCurrent16_BMS01 m16 : 31|8@0+ (0.05,0) [0|10] "A"  PT
 SG_ cmbOnboardTemperature17_BMS01 m17 : 15|8@0+ (1,-40) [-40|200] "C"  PT
 SG_ cmbOnboardHumidity17_BMS01 m17 : 23|8@0+ (0.5,0) [0|120] "PCT"  PT
 SG_ moduleHeaterCurrent17_BMS01 m17 : 31|8@0+ (0.05,0) [0|10] "A"  PT
 SG_ cmbOnboardTemperature18_BMS01 m18 : 15|8@0+ (1,-40) [-40|200] "C"  PT
 SG_ cmbOnboardHumidity18_BMS01 m18 : 23|8@0+ (0.5,0) [0|120] "PCT"  PT
 SG_ moduleHeaterCurrent18_BMS01 m18 : 31|8@0+ (0.05,0) [0|10] "A"  PT
 SG_ cmbOnboardTemperature19_BMS01 m19 : 15|8@0+ (1,-40) [-40|200] "C"  PT
 SG_ cmbOnboardHumidity19_BMS01 m19 : 23|8@0+ (0.5,0) [0|120] "PCT"  PT
 SG_ moduleHeaterCurrent19_BMS01 m19 : 31|8@0+ (0.05,0) [0|10] "A"  PT
 SG_ cmbOnboardTemperature20_BMS01 m20 : 15|8@0+ (1,-40) [-40|200] "C"  PT
 SG_ cmbOnboardHumidity20_BMS01 m20 : 23|8@0+ (0.5,0) [0|120] "PCT"  PT
 SG_ moduleHeaterCurrent20_BMS01 m20 : 31|8@0+ (0.05,0) [0|10] "A"  PT
 SG_ cmbOnboardTemperature21_BMS01 m21 : 15|8@0+ (1,-40) [-40|200] "C"  PT
 SG_ cmbOnboardHumidity21_BMS01 m21 : 23|8@0+ (0.5,0) [0|120] "PCT"  PT
 SG_ moduleHeaterCurrent21_BMS01 m21 : 31|8@0+ (0.05,0) [0|10] "A"  PT
 SG_ cmbOnboardTemperature22_BMS01 m22 : 15|8@0+ (1,-40) [-40|200] "C"  PT
 SG_ cmbOnboardHumidity22_BMS01 m22 : 23|8@0+ (0.5,0) [0|120] "PCT"  PT
 SG_ moduleHeaterCurrent22_BMS01 m22 : 31|8@0+ (0.05,0) [0|10] "A"  PT
 SG_ cmbOnboardTemperature23_BMS01 m23 : 15|8@0+ (1,-40) [-40|200] "C"  PT
 SG_ cmbOnboardHumidity23_BMS01 m23 : 23|8@0+ (0.5,0) [0|120] "PCT"  PT
 SG_ moduleHeaterCurrent23_BMS01 m23 : 31|8@0+ (0.05,0) [0|10] "A"  PT
 SG_ cmbOnboardTemperature24_BMS01 m24 : 15|8@0+ (1,-40) [-40|200] "C"  PT
 SG_ cmbOnboardHumidity24_BMS01 m24 : 23|8@0+ (0.5,0) [0|120] "PCT"  PT
 SG_ moduleHeaterCurrent24_BMS01 m24 : 31|8@0+ (0.05,0) [0|10] "A"  PT
 SG_ cmbOnboardTemperature25_BMS01 m25 : 15|8@0+ (1,-40) [-40|200] "C"  PT
 SG_ cmbOnboardHumidity25_BMS01 m25 : 23|8@0+ (0.5,0) [0|120] "PCT"  PT
 SG_ moduleHeaterCurrent25_BMS01 m25 : 31|8@0+ (0.05,0) [0|10] "A"  PT
 SG_ cmbOnboardTemperature26_BMS01 m26 : 15|8@0+ (1,-40) [-40|200] "C"  PT
 SG_ cmbOnboardHumidity26_BMS01 m26 : 23|8@0+ (0.5,0) [0|120] "PCT"  PT
 SG_ moduleHeaterCurrent26_BMS01 m26 : 31|8@0+ (0.05,0) [0|10] "A"  PT
 SG_ cmbOnboardTemperature27_BMS01 m27 : 15|8@0+ (1,-40) [-40|200] "C"  PT
 SG_ cmbOnboardHumidity27_BMS01 m27 : 23|8@0+ (0.5,0) [0|120] "PCT"  PT
 SG_ moduleHeaterCurrent27_BMS01 m27 : 31|8@0+ (0.05,0) [0|10] "A"  PT
 SG_ cmbOnboardTemperature28_BMS01 m28 : 15|8@0+ (1,-40) [-40|200] "C"  PT
 SG_ cmbOnboardHumidity28_BMS01 m28 : 23|8@0+ (0.5,0) [0|120] "PCT"  PT
 SG_ moduleHeaterCurrent28_BMS01 m28 : 31|8@0+ (0.05,0) [0|10] "A"  PT
 SG_ cmbOnboardTemperature29_BMS01 m29 : 15|8@0+ (1,-40) [-40|200] "C"  PT
 SG_ cmbOnboardHumidity29_BMS01 m29 : 23|8@0+ (0.5,0) [0|120] "PCT"  PT
 SG_ moduleHeaterCurrent29_BMS01 m29 : 31|8@0+ (0.05,0) [0|10] "A"  PT
 SG_ cmbOnboardTemperature30_BMS01 m30 : 15|8@0+ (1,-40) [-40|200] "C"  PT
 SG_ cmbOnboardHumidity30_BMS01 m30 : 23|8@0+ (0.5,0) [0|120] "PCT"  PT
 SG_ moduleHeaterCurrent30_BMS01 m30 : 31|8@0+ (0.05,0) [0|10] "A"  PT
 SG_ cmbOnboardTemperature31_BMS01 m31 : 15|8@0+ (1,-40) [-40|200] "C"  PT
 SG_ cmbOnboardHumidity31_BMS01 m31 : 23|8@0+ (0.5,0) [0|120] "PCT"  PT
 SG_ moduleHeaterCurrent31_BMS01 m31 : 31|8@0+ (0.05,0) [0|10] "A"  PT
 SG_ cmbOnboardTemperature32_BMS01 m32 : 15|8@0+ (1,-40) [-40|200] "C"  PT
 SG_ cmbOnboardHumidity32_BMS01 m32 : 23|8@0+ (0.5,0) [0|120] "PCT"  PT
 SG_ moduleHeaterCurrent32_BMS01 m32 : 31|8@0+ (0.05,0) [0|10] "A"  PT

BO_ 1984 BMS01_DebugCMB: 8 BMS01
 SG_ cmbMultiplexor_BMS01 M : 7|8@0+ (1,0) [0|0] ""  PT
 SG_ moduleTemperature01_BMS01 m1 : 15|8@0+ (1,-40) [-40|200] "C"  PT
 SG_ brickVoltage001_BMS01 m1 : 23|16@0+ (0.0001,0) [0|6.5] "V"  PT
 SG_ brickVoltage002_BMS01 m1 : 39|16@0+ (0.0001,0) [0|6.5] "V"  PT
 SG_ brickVoltage003_BMS01 m1 : 55|16@0+ (0.0001,0) [0|6.5] "V"  PT
 SG_ moduleTemperature02_BMS01 m2 : 15|8@0+ (1,-40) [-40|200] "C"  PT
 SG_ brickVoltage004_BMS01 m2 : 23|16@0+ (0.0001,0) [0|6.5] "V"  PT
 SG_ brickVoltage005_BMS01 m2 : 39|16@0+ (0.0001,0) [0|6.5] "V"  PT
 SG_ brickVoltage006_BMS01 m2 : 55|16@0+ (0.0001,0) [0|6.5] "V"  PT
 SG_ moduleTemperature03_BMS01 m3 : 15|8@0+ (1,-40) [-40|200] "C"  PT
 SG_ brickVoltage007_BMS01 m3 : 23|16@0+ (0.0001,0) [0|6.5] "V"  PT
 SG_ brickVoltage008_BMS01 m3 : 39|16@0+ (0.0001,0) [0|6.5] "V"  PT
 SG_ brickVoltage009_BMS01 m3 : 55|16@0+ (0.0001,0) [0|6.5] "V"  PT
 SG_ moduleTemperature04_BMS01 m4 : 15|8@0+ (1,-40) [-40|200] "C"  PT
 SG_ brickVoltage010_BMS01 m4 : 23|16@0+ (0.0001,0) [0|6.5] "V"  PT
 SG_ brickVoltage011_BMS01 m4 : 39|16@0+ (0.0001,0) [0|6.5] "V"  PT
 SG_ brickVoltage012_BMS01 m4 : 55|16@0+ (0.0001,0) [0|6.5] "V"  PT
 SG_ moduleTemperature05_BMS01 m5 : 15|8@0+ (1,-40) [-40|200] "C"  PT
 SG_ brickVoltage013_BMS01 m5 : 23|16@0+ (0.0001,0) [0|6.5] "V"  PT
 SG_ brickVoltage014_BMS01 m5 : 39|16@0+ (0.0001,0) [0|6.5] "V"  PT
 SG_ brickVoltage015_BMS01 m5 : 55|16@0+ (0.0001,0) [0|6.5] "V"  PT
 SG_ moduleTemperature06_BMS01 m6 : 15|8@0+ (1,-40) [-40|200] "C"  PT
 SG_ brickVoltage016_BMS01 m6 : 23|16@0+ (0.0001,0) [0|6.5] "V"  PT
 SG_ brickVoltage017_BMS01 m6 : 39|16@0+ (0.0001,0) [0|6.5] "V"  PT
 SG_ brickVoltage018_BMS01 m6 : 55|16@0+ (0.0001,0) [0|6.5] "V"  PT
 SG_ moduleTemperature07_BMS01 m7 : 15|8@0+ (1,-40) [-40|200] "C"  PT
 SG_ brickVoltage019_BMS01 m7 : 23|16@0+ (0.0001,0) [0|6.5] "V"  PT
 SG_ brickVoltage020_BMS01 m7 : 39|16@0+ (0.0001,0) [0|6.5] "V"  PT
 SG_ brickVoltage021_BMS01 m7 : 55|16@0+ (0.0001,0) [0|6.5] "V"  PT
 SG_ moduleTemperature08_BMS01 m8 : 15|8@0+ (1,-40) [-40|200] "C"  PT
 SG_ brickVoltage022_BMS01 m8 : 23|16@0+ (0.0001,0) [0|6.5] "V"  PT
 SG_ brickVoltage023_BMS01 m8 : 39|16@0+ (0.0001,0) [0|6.5] "V"  PT
 SG_ brickVoltage024_BMS01 m8 : 55|16@0+ (0.0001,0) [0|6.5] "V"  PT
 SG_ moduleTemperature09_BMS01 m9 : 15|8@0+ (1,-40) [-40|200] "C"  PT
 SG_ brickVoltage025_BMS01 m9 : 23|16@0+ (0.0001,0) [0|6.5] "V"  PT
 SG_ brickVoltage026_BMS01 m9 : 39|16@0+ (0.0001,0) [0|6.5] "V"  PT
 SG_ brickVoltage027_BMS01 m9 : 55|16@0+ (0.0001,0) [0|6.5] "V"  PT
 SG_ moduleTemperature10_BMS01 m10 : 15|8@0+ (1,-40) [-40|200] "C"  PT
 SG_ brickVoltage028_BMS01 m10 : 23|16@0+ (0.0001,0) [0|6.5] "V"  PT
 SG_ brickVoltage029_BMS01 m10 : 39|16@0+ (0.0001,0) [0|6.5] "V"  PT
 SG_ brickVoltage030_BMS01 m10 : 55|16@0+ (0.0001,0) [0|6.5] "V"  PT
 SG_ moduleTemperature11_BMS01 m11 : 15|8@0+ (1,-40) [-40|200] "C"  PT
 SG_ brickVoltage031_BMS01 m11 : 23|16@0+ (0.0001,0) [0|6.5] "V"  PT
 SG_ brickVoltage032_BMS01 m11 : 39|16@0+ (0.0001,0) [0|6.5] "V"  PT
 SG_ brickVoltage033_BMS01 m11 : 55|16@0+ (0.0001,0) [0|6.5] "V"  PT
 SG_ moduleTemperature12_BMS01 m12 : 15|8@0+ (1,-40) [-40|200] "C"  PT
 SG_ brickVoltage034_BMS01 m12 : 23|16@0+ (0.0001,0) [0|6.5] "V"  PT
 SG_ brickVoltage035_BMS01 m12 : 39|16@0+ (0.0001,0) [0|6.5] "V"  PT
 SG_ brickVoltage036_BMS01 m12 : 55|16@0+ (0.0001,0) [0|6.5] "V"  PT
 SG_ moduleTemperature13_BMS01 m13 : 15|8@0+ (1,-40) [-40|200] "C"  PT
 SG_ brickVoltage037_BMS01 m13 : 23|16@0+ (0.0001,0) [0|6.5] "V"  PT
 SG_ brickVoltage038_BMS01 m13 : 39|16@0+ (0.0001,0) [0|6.5] "V"  PT
 SG_ brickVoltage039_BMS01 m13 : 55|16@0+ (0.0001,0) [0|6.5] "V"  PT
 SG_ moduleTemperature14_BMS01 m14 : 15|8@0+ (1,-40) [-40|200] "C"  PT
 SG_ brickVoltage040_BMS01 m14 : 23|16@0+ (0.0001,0) [0|6.5] "V"  PT
 SG_ brickVoltage041_BMS01 m14 : 39|16@0+ (0.0001,0) [0|6.5] "V"  PT
 SG_ brickVoltage042_BMS01 m14 : 55|16@0+ (0.0001,0) [0|6.5] "V"  PT
 SG_ moduleTemperature15_BMS01 m15 : 15|8@0+ (1,-40) [-40|200] "C"  PT
 SG_ brickVoltage043_BMS01 m15 : 23|16@0+ (0.0001,0) [0|6.5] "V"  PT
 SG_ brickVoltage044_BMS01 m15 : 39|16@0+ (0.0001,0) [0|6.5] "V"  PT
 SG_ brickVoltage045_BMS01 m15 : 55|16@0+ (0.0001,0) [0|6.5] "V"  PT
 SG_ moduleTemperature16_BMS01 m16 : 15|8@0+ (1,-40) [-40|200] "C"  PT
 SG_ brickVoltage046_BMS01 m16 : 23|16@0+ (0.0001,0) [0|6.5] "V"  PT
 SG_ brickVoltage047_BMS01 m16 : 39|16@0+ (0.0001,0) [0|6.5] "V"  PT
 SG_ brickVoltage048_BMS01 m16 : 55|16@0+ (0.0001,0) [0|6.5] "V"  PT
 SG_ moduleTemperature17_BMS01 m17 : 15|8@0+ (1,-40) [-40|200] "C"  PT
 SG_ brickVoltage049_BMS01 m17 : 23|16@0+ (0.0001,0) [0|6.5] "V"  PT
 SG_ brickVoltage050_BMS01 m17 : 39|16@0+ (0.0001,0) [0|6.5] "V"  PT
 SG_ brickVoltage051_BMS01 m17 : 55|16@0+ (0.0001,0) [0|6.5] "V"  PT
 SG_ moduleTemperature18_BMS01 m18 : 15|8@0+ (1,-40) [-40|200] "C"  PT
 SG_ brickVoltage052_BMS01 m18 : 23|16@0+ (0.0001,0) [0|6.5] "V"  PT
 SG_ brickVoltage053_BMS01 m18 : 39|16@0+ (0.0001,0) [0|6.5] "V"  PT
 SG_ brickVoltage054_BMS01 m18 : 55|16@0+ (0.0001,0) [0|6.5] "V"  PT
 SG_ moduleTemperature19_BMS01 m19 : 15|8@0+ (1,-40) [-40|200] "C"  PT
 SG_ brickVoltage055_BMS01 m19 : 23|16@0+ (0.0001,0) [0|6.5] "V"  PT
 SG_ brickVoltage056_BMS01 m19 : 39|16@0+ (0.0001,0) [0|6.5] "V"  PT
 SG_ brickVoltage057_BMS01 m19 : 55|16@0+ (0.0001,0) [0|6.5] "V"  PT
 SG_ moduleTemperature20_BMS01 m20 : 15|8@0+ (1,-40) [-40|200] "C"  PT
 SG_ brickVoltage058_BMS01 m20 : 23|16@0+ (0.0001,0) [0|6.5] "V"  PT
 SG_ brickVoltage059_BMS01 m20 : 39|16@0+ (0.0001,0) [0|6.5] "V"  PT
 SG_ brickVoltage060_BMS01 m20 : 55|16@0+ (0.0001,0) [0|6.5] "V"  PT
 SG_ moduleTemperature21_BMS01 m21 : 15|8@0+ (1,-40) [-40|200] "C"  PT
 SG_ brickVoltage061_BMS01 m21 : 23|16@0+ (0.0001,0) [0|6.5] "V"  PT
 SG_ brickVoltage062_BMS01 m21 : 39|16@0+ (0.0001,0) [0|6.5] "V"  PT
 SG_ brickVoltage063_BMS01 m21 : 55|16@0+ (0.0001,0) [0|6.5] "V"  PT
 SG_ moduleTemperature22_BMS01 m22 : 15|8@0+ (1,-40) [-40|200] "C"  PT
 SG_ brickVoltage064_BMS01 m22 : 23|16@0+ (0.0001,0) [0|6.5] "V"  PT
 SG_ brickVoltage065_BMS01 m22 : 39|16@0+ (0.0001,0) [0|6.5] "V"  PT
 SG_ brickVoltage066_BMS01 m22 : 55|16@0+ (0.0001,0) [0|6.5] "V"  PT
 SG_ moduleTemperature23_BMS01 m23 : 15|8@0+ (1,-40) [-40|200] "C"  PT
 SG_ brickVoltage067_BMS01 m23 : 23|16@0+ (0.0001,0) [0|6.5] "V"  PT
 SG_ brickVoltage068_BMS01 m23 : 39|16@0+ (0.0001,0) [0|6.5] "V"  PT
 SG_ brickVoltage069_BMS01 m23 : 55|16@0+ (0.0001,0) [0|6.5] "V"  PT
 SG_ moduleTemperature24_BMS01 m24 : 15|8@0+ (1,-40) [-40|200] "C"  PT
 SG_ brickVoltage070_BMS01 m24 : 23|16@0+ (0.0001,0) [0|6.5] "V"  PT
 SG_ brickVoltage071_BMS01 m24 : 39|16@0+ (0.0001,0) [0|6.5] "V"  PT
 SG_ brickVoltage072_BMS01 m24 : 55|16@0+ (0.0001,0) [0|6.5] "V"  PT
 SG_ moduleTemperature25_BMS01 m25 : 15|8@0+ (1,-40) [-40|200] "C"  PT
 SG_ brickVoltage073_BMS01 m25 : 23|16@0+ (0.0001,0) [0|6.5] "V"  PT
 SG_ brickVoltage074_BMS01 m25 : 39|16@0+ (0.0001,0) [0|6.5] "V"  PT
 SG_ brickVoltage075_BMS01 m25 : 55|16@0+ (0.0001,0) [0|6.5] "V"  PT
 SG_ moduleTemperature26_BMS01 m26 : 15|8@0+ (1,-40) [-40|200] "C"  PT
 SG_ brickVoltage076_BMS01 m26 : 23|16@0+ (0.0001,0) [0|6.5] "V"  PT
 SG_ brickVoltage077_BMS01 m26 : 39|16@0+ (0.0001,0) [0|6.5] "V"  PT
 SG_ brickVoltage078_BMS01 m26 : 55|16@0+ (0.0001,0) [0|6.5] "V"  PT
 SG_ moduleTemperature27_BMS01 m27 : 15|8@0+ (1,-40) [-40|200] "C"  PT
 SG_ brickVoltage079_BMS01 m27 : 23|16@0+ (0.0001,0) [0|6.5] "V"  PT
 SG_ brickVoltage080_BMS01 m27 : 39|16@0+ (0.0001,0) [0|6.5] "V"  PT
 SG_ brickVoltage081_BMS01 m27 : 55|16@0+ (0.0001,0) [0|6.5] "V"  PT
 SG_ moduleTemperature28_BMS01 m28 : 15|8@0+ (1,-40) [-40|200] "C"  PT
 SG_ brickVoltage082_BMS01 m28 : 23|16@0+ (0.0001,0) [0|6.5] "V"  PT
 SG_ brickVoltage083_BMS01 m28 : 39|16@0+ (0.0001,0) [0|6.5] "V"  PT
 SG_ brickVoltage084_BMS01 m28 : 55|16@0+ (0.0001,0) [0|6.5] "V"  PT
 SG_ moduleTemperature29_BMS01 m29 : 15|8@0+ (1,-40) [-40|200] "C"  PT
 SG_ brickVoltage085_BMS01 m29 : 23|16@0+ (0.0001,0) [0|6.5] "V"  PT
 SG_ brickVoltage086_BMS01 m29 : 39|16@0+ (0.0001,0) [0|6.5] "V"  PT
 SG_ brickVoltage087_BMS01 m29 : 55|16@0+ (0.0001,0) [0|6.5] "V"  PT
 SG_ moduleTemperature30_BMS01 m30 : 15|8@0+ (1,-40) [-40|200] "C"  PT
 SG_ brickVoltage088_BMS01 m30 : 23|16@0+ (0.0001,0) [0|6.5] "V"  PT
 SG_ brickVoltage089_BMS01 m30 : 39|16@0+ (0.0001,0) [0|6.5] "V"  PT
 SG_ brickVoltage090_BMS01 m30 : 55|16@0+ (0.0001,0) [0|6.5] "V"  PT
 SG_ moduleTemperature31_BMS01 m31 : 15|8@0+ (1,-40) [-40|200] "C"  PT
 SG_ brickVoltage091_BMS01 m31 : 23|16@0+ (0.0001,0) [0|6.5] "V"  PT
 SG_ brickVoltage092_BMS01 m31 : 39|16@0+ (0.0001,0) [0|6.5] "V"  PT
 SG_ brickVoltage093_BMS01 m31 : 55|16@0+ (0.0001,0) [0|6.5] "V"  PT
 SG_ moduleTemperature32_BMS01 m32 : 15|8@0+ (1,-40) [-40|200] "C"  PT
 SG_ brickVoltage094_BMS01 m32 : 23|16@0+ (0.0001,0) [0|6.5] "V"  PT
 SG_ brickVoltage095_BMS01 m32 : 39|16@0+ (0.0001,0) [0|6.5] "V"  PT
 SG_ brickVoltage096_BMS01 m32 : 55|16@0+ (0.0001,0) [0|6.5] "V"  PT
 SG_ brickVoltage097_BMS01 m33 : 23|16@0+ (0.0001,0) [0|6.5] "V"  PT
 SG_ brickVoltage098_BMS01 m33 : 39|16@0+ (0.0001,0) [0|6.5] "V"  PT
 SG_ brickVoltage099_BMS01 m33 : 55|16@0+ (0.0001,0) [0|6.5] "V"  PT
 SG_ brickVoltage100_BMS01 m34 : 23|16@0+ (0.0001,0) [0|6.5] "V"  PT
 SG_ brickVoltage101_BMS01 m34 : 39|16@0+ (0.0001,0) [0|6.5] "V"  PT
 SG_ brickVoltage102_BMS01 m34 : 55|16@0+ (0.0001,0) [0|6.5] "V"  PT
 SG_ brickVoltage103_BMS01 m35 : 23|16@0+ (0.0001,0) [0|6.5] "V"  PT
 SG_ brickVoltage104_BMS01 m35 : 39|16@0+ (0.0001,0) [0|6.5] "V"  PT
 SG_ brickVoltage105_BMS01 m35 : 55|16@0+ (0.0001,0) [0|6.5] "V"  PT
 SG_ brickVoltage106_BMS01 m36 : 23|16@0+ (0.0001,0) [0|6.5] "V"  PT
 SG_ brickVoltage107_BMS01 m36 : 39|16@0+ (0.0001,0) [0|6.5] "V"  PT
 SG_ brickVoltage108_BMS01 m36 : 55|16@0+ (0.0001,0) [0|6.5] "V"  PT
 SG_ brickVoltage109_BMS01 m37 : 23|16@0+ (0.0001,0) [0|6.5] "V"  PT
 SG_ brickVoltage110_BMS01 m37 : 39|16@0+ (0.0001,0) [0|6.5] "V"  PT
 SG_ brickVoltage111_BMS01 m37 : 55|16@0+ (0.0001,0) [0|6.5] "V"  PT
 SG_ brickVoltage112_BMS01 m38 : 23|16@0+ (0.0001,0) [0|6.5] "V"  PT
 SG_ brickVoltage113_BMS01 m38 : 39|16@0+ (0.0001,0) [0|6.5] "V"  PT
 SG_ brickVoltage114_BMS01 m38 : 55|16@0+ (0.0001,0) [0|6.5] "V"  PT
 SG_ brickVoltage115_BMS01 m39 : 23|16@0+ (0.0001,0) [0|6.5] "V"  PT
 SG_ brickVoltage116_BMS01 m39 : 39|16@0+ (0.0001,0) [0|6.5] "V"  PT
 SG_ brickVoltage117_BMS01 m39 : 55|16@0+ (0.0001,0) [0|6.5] "V"  PT
 SG_ brickVoltage118_BMS01 m40 : 23|16@0+ (0.0001,0) [0|6.5] "V"  PT
 SG_ brickVoltage119_BMS01 m40 : 39|16@0+ (0.0001,0) [0|6.5] "V"  PT
 SG_ brickVoltage120_BMS01 m40 : 55|16@0+ (0.0001,0) [0|6.5] "V"  PT
 SG_ brickVoltage121_BMS01 m41 : 23|16@0+ (0.0001,0) [0|6.5] "V"  PT
 SG_ brickVoltage122_BMS01 m41 : 39|16@0+ (0.0001,0) [0|6.5] "V"  PT
 SG_ brickVoltage123_BMS01 m41 : 55|16@0+ (0.0001,0) [0|6.5] "V"  PT
 SG_ brickVoltage124_BMS01 m42 : 23|16@0+ (0.0001,0) [0|6.5] "V"  PT
 SG_ brickVoltage125_BMS01 m42 : 39|16@0+ (0.0001,0) [0|6.5] "V"  PT
 SG_ brickVoltage126_BMS01 m42 : 55|16@0+ (0.0001,0) [0|6.5] "V"  PT
 SG_ brickVoltage127_BMS01 m43 : 23|16@0+ (0.0001,0) [0|6.5] "V"  PT
 SG_ brickVoltage128_BMS01 m43 : 39|16@0+ (0.0001,0) [0|6.5] "V"  PT
 SG_ brickVoltage129_BMS01 m43 : 55|16@0+ (0.0001,0) [0|6.5] "V"  PT
 SG_ brickVoltage130_BMS01 m44 : 23|16@0+ (0.0001,0) [0|6.5] "V"  PT
 SG_ brickVoltage131_BMS01 m44 : 39|16@0+ (0.0001,0) [0|6.5] "V"  PT
 SG_ brickVoltage132_BMS01 m44 : 55|16@0+ (0.0001,0) [0|6.5] "V"  PT
 SG_ brickVoltage133_BMS01 m45 : 23|16@0+ (0.0001,0) [0|6.5] "V"  PT
 SG_ brickVoltage134_BMS01 m45 : 39|16@0+ (0.0001,0) [0|6.5] "V"  PT
 SG_ brickVoltage135_BMS01 m45 : 55|16@0+ (0.0001,0) [0|6.5] "V"  PT
 SG_ brickVoltage136_BMS01 m46 : 23|16@0+ (0.0001,0) [0|6.5] "V"  PT
 SG_ brickVoltage137_BMS01 m46 : 39|16@0+ (0.0001,0) [0|6.5] "V"  PT
 SG_ brickVoltage138_BMS01 m46 : 55|16@0+ (0.0001,0) [0|6.5] "V"  PT
 SG_ brickVoltage139_BMS01 m47 : 23|16@0+ (0.0001,0) [0|6.5] "V"  PT
 SG_ brickVoltage140_BMS01 m47 : 39|16@0+ (0.0001,0) [0|6.5] "V"  PT
 SG_ brickVoltage141_BMS01 m47 : 55|16@0+ (0.0001,0) [0|6.5] "V"  PT
 SG_ brickVoltage142_BMS01 m48 : 23|16@0+ (0.0001,0) [0|6.5] "V"  PT
 SG_ brickVoltage143_BMS01 m48 : 39|16@0+ (0.0001,0) [0|6.5] "V"  PT
 SG_ brickVoltage144_BMS01 m48 : 55|16@0+ (0.0001,0) [0|6.5] "V"  PT
 SG_ brickVoltage145_BMS01 m49 : 23|16@0+ (0.0001,0) [0|6.5] "V"  PT
 SG_ brickVoltage146_BMS01 m49 : 39|16@0+ (0.0001,0) [0|6.5] "V"  PT
 SG_ brickVoltage147_BMS01 m49 : 55|16@0+ (0.0001,0) [0|6.5] "V"  PT
 SG_ brickVoltage148_BMS01 m50 : 23|16@0+ (0.0001,0) [0|6.5] "V"  PT
 SG_ brickVoltage149_BMS01 m50 : 39|16@0+ (0.0001,0) [0|6.5] "V"  PT
 SG_ brickVoltage150_BMS01 m50 : 55|16@0+ (0.0001,0) [0|6.5] "V"  PT
 SG_ brickVoltage151_BMS01 m51 : 23|16@0+ (0.0001,0) [0|6.5] "V"  PT
 SG_ brickVoltage152_BMS01 m51 : 39|16@0+ (0.0001,0) [0|6.5] "V"  PT
 SG_ brickVoltage153_BMS01 m51 : 55|16@0+ (0.0001,0) [0|6.5] "V"  PT
 SG_ brickVoltage154_BMS01 m52 : 23|16@0+ (0.0001,0) [0|6.5] "V"  PT
 SG_ brickVoltage155_BMS01 m52 : 39|16@0+ (0.0001,0) [0|6.5] "V"  PT
 SG_ brickVoltage156_BMS01 m52 : 55|16@0+ (0.0001,0) [0|6.5] "V"  PT
 SG_ brickVoltage157_BMS01 m53 : 23|16@0+ (0.0001,0) [0|6.5] "V"  PT
 SG_ brickVoltage158_BMS01 m53 : 39|16@0+ (0.0001,0) [0|6.5] "V"  PT
 SG_ brickVoltage159_BMS01 m53 : 55|16@0+ (0.0001,0) [0|6.5] "V"  PT
 SG_ brickVoltage160_BMS01 m54 : 23|16@0+ (0.0001,0) [0|6.5] "V"  PT
 SG_ brickVoltage161_BMS01 m54 : 39|16@0+ (0.0001,0) [0|6.5] "V"  PT
 SG_ brickVoltage162_BMS01 m54 : 55|16@0+ (0.0001,0) [0|6.5] "V"  PT
 SG_ brickVoltage163_BMS01 m55 : 23|16@0+ (0.0001,0) [0|6.5] "V"  PT
 SG_ brickVoltage164_BMS01 m55 : 39|16@0+ (0.0001,0) [0|6.5] "V"  PT
 SG_ brickVoltage165_BMS01 m55 : 55|16@0+ (0.0001,0) [0|6.5] "V"  PT
 SG_ brickVoltage166_BMS01 m56 : 23|16@0+ (0.0001,0) [0|6.5] "V"  PT
 SG_ brickVoltage167_BMS01 m56 : 39|16@0+ (0.0001,0) [0|6.5] "V"  PT
 SG_ brickVoltage168_BMS01 m56 : 55|16@0+ (0.0001,0) [0|6.5] "V"  PT
 SG_ brickVoltage169_BMS01 m57 : 23|16@0+ (0.0001,0) [0|6.5] "V"  PT
 SG_ brickVoltage170_BMS01 m57 : 39|16@0+ (0.0001,0) [0|6.5] "V"  PT
 SG_ brickVoltage171_BMS01 m57 : 55|16@0+ (0.0001,0) [0|6.5] "V"  PT
 SG_ brickVoltage172_BMS01 m58 : 23|16@0+ (0.0001,0) [0|6.5] "V"  PT
 SG_ brickVoltage173_BMS01 m58 : 39|16@0+ (0.0001,0) [0|6.5] "V"  PT
 SG_ brickVoltage174_BMS01 m58 : 55|16@0+ (0.0001,0) [0|6.5] "V"  PT
 SG_ brickVoltage175_BMS01 m59 : 23|16@0+ (0.0001,0) [0|6.5] "V"  PT
 SG_ brickVoltage176_BMS01 m59 : 39|16@0+ (0.0001,0) [0|6.5] "V"  PT
 SG_ brickVoltage177_BMS01 m59 : 55|16@0+ (0.0001,0) [0|6.5] "V"  PT
 SG_ brickVoltage178_BMS01 m60 : 23|16@0+ (0.0001,0) [0|6.5] "V"  PT
 SG_ brickVoltage179_BMS01 m60 : 39|16@0+ (0.0001,0) [0|6.5] "V"  PT
 SG_ brickVoltage180_BMS01 m60 : 55|16@0+ (0.0001,0) [0|6.5] "V"  PT
 SG_ brickVoltage181_BMS01 m61 : 23|16@0+ (0.0001,0) [0|6.5] "V"  PT
 SG_ brickVoltage182_BMS01 m61 : 39|16@0+ (0.0001,0) [0|6.5] "V"  PT
 SG_ brickVoltage183_BMS01 m61 : 55|16@0+ (0.0001,0) [0|6.5] "V"  PT
 SG_ brickVoltage184_BMS01 m62 : 23|16@0+ (0.0001,0) [0|6.5] "V"  PT
 SG_ brickVoltage185_BMS01 m62 : 39|16@0+ (0.0001,0) [0|6.5] "V"  PT
 SG_ brickVoltage186_BMS01 m62 : 55|16@0+ (0.0001,0) [0|6.5] "V"  PT
 SG_ brickVoltage187_BMS01 m63 : 23|16@0+ (0.0001,0) [0|6.5] "V"  PT
 SG_ brickVoltage188_BMS01 m63 : 39|16@0+ (0.0001,0) [0|6.5] "V"  PT
 SG_ brickVoltage189_BMS01 m63 : 55|16@0+ (0.0001,0) [0|6.5] "V"  PT
 SG_ brickVoltage190_BMS01 m64 : 23|16@0+ (0.0001,0) [0|6.5] "V"  PT
 SG_ brickVoltage191_BMS01 m64 : 39|16@0+ (0.0001,0) [0|6.5] "V"  PT
 SG_ brickVoltage192_BMS01 m64 : 55|16@0+ (0.0001,0) [0|6.5] "V"  PT
 SG_ brickVoltage193_BMS01 m65 : 23|16@0+ (0.0001,0) [0|6.5] "V"  PT
 SG_ brickVoltage194_BMS01 m65 : 39|16@0+ (0.0001,0) [0|6.5] "V"  PT
 SG_ brickVoltage195_BMS01 m65 : 55|16@0+ (0.0001,0) [0|6.5] "V"  PT
 SG_ brickVoltage196_BMS01 m66 : 23|16@0+ (0.0001,0) [0|6.5] "V"  PT
 SG_ brickVoltage197_BMS01 m66 : 39|16@0+ (0.0001,0) [0|6.5] "V"  PT
 SG_ brickVoltage198_BMS01 m66 : 55|16@0+ (0.0001,0) [0|6.5] "V"  PT
 SG_ brickVoltage199_BMS01 m67 : 23|16@0+ (0.0001,0) [0|6.5] "V"  PT
 SG_ brickVoltage200_BMS01 m67 : 39|16@0+ (0.0001,0) [0|6.5] "V"  PT
 SG_ brickVoltage201_BMS01 m67 : 55|16@0+ (0.0001,0) [0|6.5] "V"  PT
 SG_ brickVoltage202_BMS01 m68 : 23|16@0+ (0.0001,0) [0|6.5] "V"  PT
 SG_ brickVoltage203_BMS01 m68 : 39|16@0+ (0.0001,0) [0|6.5] "V"  PT
 SG_ brickVoltage204_BMS01 m68 : 55|16@0+ (0.0001,0) [0|6.5] "V"  PT
 SG_ brickVoltage205_BMS01 m69 : 23|16@0+ (0.0001,0) [0|6.5] "V"  PT
 SG_ brickVoltage206_BMS01 m69 : 39|16@0+ (0.0001,0) [0|6.5] "V"  PT
 SG_ brickVoltage207_BMS01 m69 : 55|16@0+ (0.0001,0) [0|6.5] "V"  PT
 SG_ brickVoltage208_BMS01 m70 : 23|16@0+ (0.0001,0) [0|6.5] "V"  PT
 SG_ brickVoltage209_BMS01 m70 : 39|16@0+ (0.0001,0) [0|6.5] "V"  PT
 SG_ brickVoltage210_BMS01 m70 : 55|16@0+ (0.0001,0) [0|6.5] "V"  PT
 SG_ brickVoltage211_BMS01 m71 : 23|16@0+ (0.0001,0) [0|6.5] "V"  PT
 SG_ brickVoltage212_BMS01 m71 : 39|16@0+ (0.0001,0) [0|6.5] "V"  PT
 SG_ brickVoltage213_BMS01 m71 : 55|16@0+ (0.0001,0) [0|6.5] "V"  PT
 SG_ brickVoltage214_BMS01 m72 : 23|16@0+ (0.0001,0) [0|6.5] "V"  PT
 SG_ brickVoltage215_BMS01 m72 : 39|16@0+ (0.0001,0) [0|6.5] "V"  PT
 SG_ brickVoltage216_BMS01 m72 : 55|16@0+ (0.0001,0) [0|6.5] "V"  PT
 SG_ brickVoltage217_BMS01 m73 : 23|16@0+ (0.0001,0) [0|6.5] "V"  PT
 SG_ brickVoltage218_BMS01 m73 : 39|16@0+ (0.0001,0) [0|6.5] "V"  PT
 SG_ brickVoltage219_BMS01 m73 : 55|16@0+ (0.0001,0) [0|6.5] "V"  PT
 SG_ brickVoltage220_BMS01 m74 : 23|16@0+ (0.0001,0) [0|6.5] "V"  PT
 SG_ brickVoltage221_BMS01 m74 : 39|16@0+ (0.0001,0) [0|6.5] "V"  PT
 SG_ brickVoltage222_BMS01 m74 : 55|16@0+ (0.0001,0) [0|6.5] "V"  PT
 SG_ brickVoltage223_BMS01 m75 : 23|16@0+ (0.0001,0) [0|6.5] "V"  PT
 SG_ brickVoltage224_BMS01 m75 : 39|16@0+ (0.0001,0) [0|6.5] "V"  PT
 SG_ brickVoltage225_BMS01 m75 : 55|16@0+ (0.0001,0) [0|6.5] "V"  PT
 SG_ brickVoltage226_BMS01 m76 : 23|16@0+ (0.0001,0) [0|6.5] "V"  PT
 SG_ brickVoltage227_BMS01 m76 : 39|16@0+ (0.0001,0) [0|6.5] "V"  PT
 SG_ brickVoltage228_BMS01 m76 : 55|16@0+ (0.0001,0) [0|6.5] "V"  PT
 SG_ brickVoltage229_BMS01 m77 : 23|16@0+ (0.0001,0) [0|6.5] "V"  PT
 SG_ brickVoltage230_BMS01 m77 : 39|16@0+ (0.0001,0) [0|6.5] "V"  PT
 SG_ brickVoltage231_BMS01 m77 : 55|16@0+ (0.0001,0) [0|6.5] "V"  PT
 SG_ brickVoltage232_BMS01 m78 : 23|16@0+ (0.0001,0) [0|6.5] "V"  PT
 SG_ brickVoltage233_BMS01 m78 : 39|16@0+ (0.0001,0) [0|6.5] "V"  PT
 SG_ brickVoltage234_BMS01 m78 : 55|16@0+ (0.0001,0) [0|6.5] "V"  PT
 SG_ brickVoltage235_BMS01 m79 : 23|16@0+ (0.0001,0) [0|6.5] "V"  PT
 SG_ brickVoltage236_BMS01 m79 : 39|16@0+ (0.0001,0) [0|6.5] "V"  PT
 SG_ brickVoltage237_BMS01 m79 : 55|16@0+ (0.0001,0) [0|6.5] "V"  PT
 SG_ brickVoltage238_BMS01 m80 : 23|16@0+ (0.0001,0) [0|6.5] "V"  PT
 SG_ brickVoltage239_BMS01 m80 : 39|16@0+ (0.0001,0) [0|6.5] "V"  PT
 SG_ brickVoltage240_BMS01 m80 : 55|16@0+ (0.0001,0) [0|6.5] "V"  PT
 SG_ brickVoltage241_BMS01 m81 : 23|16@0+ (0.0001,0) [0|6.5] "V"  PT
 SG_ brickVoltage242_BMS01 m81 : 39|16@0+ (0.0001,0) [0|6.5] "V"  PT
 SG_ brickVoltage243_BMS01 m81 : 55|16@0+ (0.0001,0) [0|6.5] "V"  PT
 SG_ brickVoltage244_BMS01 m82 : 23|16@0+ (0.0001,0) [0|6.5] "V"  PT
 SG_ brickVoltage245_BMS01 m82 : 39|16@0+ (0.0001,0) [0|6.5] "V"  PT
 SG_ brickVoltage246_BMS01 m82 : 55|16@0+ (0.0001,0) [0|6.5] "V"  PT
 SG_ brickVoltage247_BMS01 m83 : 23|16@0+ (0.0001,0) [0|6.5] "V"  PT
 SG_ brickVoltage248_BMS01 m83 : 39|16@0+ (0.0001,0) [0|6.5] "V"  PT
 SG_ brickVoltage249_BMS01 m83 : 55|16@0+ (0.0001,0) [0|6.5] "V"  PT
 SG_ brickVoltage250_BMS01 m84 : 23|16@0+ (0.0001,0) [0|6.5] "V"  PT
 SG_ brickVoltage251_BMS01 m84 : 39|16@0+ (0.0001,0) [0|6.5] "V"  PT
 SG_ brickVoltage252_BMS01 m84 : 55|16@0+ (0.0001,0) [0|6.5] "V"  PT
 SG_ brickVoltage253_BMS01 m85 : 23|16@0+ (0.0001,0) [0|6.5] "V"  PT
 SG_ brickVoltage254_BMS01 m85 : 39|16@0+ (0.0001,0) [0|6.5] "V"  PT
 SG_ brickVoltage255_BMS01 m85 : 55|16@0+ (0.0001,0) [0|6.5] "V"  PT
 SG_ brickVoltage256_BMS01 m86 : 23|16@0+ (0.0001,0) [0|6.5] "V"  PT
 SG_ brickVoltage257_BMS01 m86 : 39|16@0+ (0.0001,0) [0|6.5] "V"  PT
 SG_ brickVoltage258_BMS01 m86 : 55|16@0+ (0.0001,0) [0|6.5] "V"  PT
 SG_ brickVoltage259_BMS01 m87 : 23|16@0+ (0.0001,0) [0|6.5] "V"  PT
 SG_ brickVoltage260_BMS01 m87 : 39|16@0+ (0.0001,0) [0|6.5] "V"  PT
 SG_ brickVoltage261_BMS01 m87 : 55|16@0+ (0.0001,0) [0|6.5] "V"  PT
 SG_ brickVoltage262_BMS01 m88 : 23|16@0+ (0.0001,0) [0|6.5] "V"  PT
 SG_ brickVoltage263_BMS01 m88 : 39|16@0+ (0.0001,0) [0|6.5] "V"  PT
 SG_ brickVoltage264_BMS01 m88 : 55|16@0+ (0.0001,0) [0|6.5] "V"  PT
 SG_ brickVoltage265_BMS01 m89 : 23|16@0+ (0.0001,0) [0|6.5] "V"  PT
 SG_ brickVoltage266_BMS01 m89 : 39|16@0+ (0.0001,0) [0|6.5] "V"  PT
 SG_ brickVoltage267_BMS01 m89 : 55|16@0+ (0.0001,0) [0|6.5] "V"  PT
 SG_ brickVoltage268_BMS01 m90 : 23|16@0+ (0.0001,0) [0|6.5] "V"  PT
 SG_ brickVoltage269_BMS01 m90 : 39|16@0+ (0.0001,0) [0|6.5] "V"  PT
 SG_ brickVoltage270_BMS01 m90 : 55|16@0+ (0.0001,0) [0|6.5] "V"  PT
 SG_ brickVoltage271_BMS01 m91 : 23|16@0+ (0.0001,0) [0|6.5] "V"  PT
 SG_ brickVoltage272_BMS01 m91 : 39|16@0+ (0.0001,0) [0|6.5] "V"  PT
 SG_ brickVoltage273_BMS01 m91 : 55|16@0+ (0.0001,0) [0|6.5] "V"  PT
 SG_ brickVoltage274_BMS01 m92 : 23|16@0+ (0.0001,0) [0|6.5] "V"  PT
 SG_ brickVoltage275_BMS01 m92 : 39|16@0+ (0.0001,0) [0|6.5] "V"  PT
 SG_ brickVoltage276_BMS01 m92 : 55|16@0+ (0.0001,0) [0|6.5] "V"  PT
 SG_ brickVoltage277_BMS01 m93 : 23|16@0+ (0.0001,0) [0|6.5] "V"  PT
 SG_ brickVoltage278_BMS01 m93 : 39|16@0+ (0.0001,0) [0|6.5] "V"  PT
 SG_ brickVoltage279_BMS01 m93 : 55|16@0+ (0.0001,0) [0|6.5] "V"  PT
 SG_ brickVoltage280_BMS01 m94 : 23|16@0+ (0.0001,0) [0|6.5] "V"  PT
 SG_ brickVoltage281_BMS01 m94 : 39|16@0+ (0.0001,0) [0|6.5] "V"  PT
 SG_ brickVoltage282_BMS01 m94 : 55|16@0+ (0.0001,0) [0|6.5] "V"  PT
 SG_ brickVoltage283_BMS01 m95 : 23|16@0+ (0.0001,0) [0|6.5] "V"  PT
 SG_ brickVoltage284_BMS01 m95 : 39|16@0+ (0.0001,0) [0|6.5] "V"  PT
 SG_ brickVoltage285_BMS01 m95 : 55|16@0+ (0.0001,0) [0|6.5] "V"  PT
 SG_ brickVoltage286_BMS01 m96 : 23|16@0+ (0.0001,0) [0|6.5] "V"  PT
 SG_ brickVoltage287_BMS01 m96 : 39|16@0+ (0.0001,0) [0|6.5] "V"  PT
 SG_ brickVoltage288_BMS01 m96 : 55|16@0+ (0.0001,0) [0|6.5] "V"  PT
 SG_ brickVoltage289_BMS01 m97 : 23|16@0+ (0.0001,0) [0|6.5] "V"  PT
 SG_ brickVoltage290_BMS01 m97 : 39|16@0+ (0.0001,0) [0|6.5] "V"  PT
 SG_ brickVoltage291_BMS01 m97 : 55|16@0+ (0.0001,0) [0|6.5] "V"  PT
 SG_ brickVoltage292_BMS01 m98 : 23|16@0+ (0.0001,0) [0|6.5] "V"  PT
 SG_ brickVoltage293_BMS01 m98 : 39|16@0+ (0.0001,0) [0|6.5] "V"  PT
 SG_ brickVoltage294_BMS01 m98 : 55|16@0+ (0.0001,0) [0|6.5] "V"  PT
 SG_ brickVoltage295_BMS01 m99 : 23|16@0+ (0.0001,0) [0|6.5] "V"  PT
 SG_ brickVoltage296_BMS01 m99 : 39|16@0+ (0.0001,0) [0|6.5] "V"  PT
 SG_ brickVoltage297_BMS01 m99 : 55|16@0+ (0.0001,0) [0|6.5] "V"  PT
 SG_ brickVoltage298_BMS01 m100 : 23|16@0+ (0.0001,0) [0|6.5] "V"  PT
 SG_ brickVoltage299_BMS01 m100 : 39|16@0+ (0.0001,0) [0|6.5] "V"  PT
 SG_ brickVoltage300_BMS01 m100 : 55|16@0+ (0.0001,0) [0|6.5] "V"  PT
 SG_ moduleTemperature33_BMS01 m33 : 15|8@0+ (1,-40) [-40|200] "C"  PT
 SG_ moduleTemperature34_BMS01 m34 : 15|8@0+ (1,-40) [-40|200] "C"  PT
 SG_ moduleTemperature35_BMS01 m35 : 15|8@0+ (1,-40) [-40|200] "C"  PT
 SG_ moduleTemperature36_BMS01 m36 : 15|8@0+ (1,-40) [-40|200] "C"  PT
 SG_ moduleTemperature37_BMS01 m37 : 15|8@0+ (1,-40) [-40|200] "C"  PT
 SG_ moduleTemperature38_BMS01 m38 : 15|8@0+ (1,-40) [-40|200] "C"  PT
 SG_ moduleTemperature39_BMS01 m39 : 15|8@0+ (1,-40) [-40|200] "C"  PT
 SG_ moduleTemperature40_BMS01 m40 : 15|8@0+ (1,-40) [-40|200] "C"  PT
 SG_ moduleTemperature41_BMS01 m41 : 15|8@0+ (1,-40) [-40|200] "C"  PT
 SG_ moduleTemperature42_BMS01 m42 : 15|8@0+ (1,-40) [-40|200] "C"  PT
 SG_ moduleTemperature43_BMS01 m43 : 15|8@0+ (1,-40) [-40|200] "C"  PT
 SG_ moduleTemperature44_BMS01 m44 : 15|8@0+ (1,-40) [-40|200] "C"  PT
 SG_ moduleTemperature45_BMS01 m45 : 15|8@0+ (1,-40) [-40|200] "C"  PT
 SG_ moduleTemperature46_BMS01 m46 : 15|8@0+ (1,-40) [-40|200] "C"  PT
 SG_ moduleTemperature47_BMS01 m47 : 15|8@0+ (1,-40) [-40|200] "C"  PT
 SG_ moduleTemperature48_BMS01 m48 : 15|8@0+ (1,-40) [-40|200] "C"  PT
 SG_ moduleTemperature49_BMS01 m49 : 15|8@0+ (1,-40) [-40|200] "C"  PT
 SG_ moduleTemperature50_BMS01 m50 : 15|8@0+ (1,-40) [-40|200] "C"  PT
 SG_ moduleTemperature51_BMS01 m51 : 15|8@0+ (1,-40) [-40|200] "C"  PT
 SG_ moduleTemperature52_BMS01 m52 : 15|8@0+ (1,-40) [-40|200] "C"  PT
 SG_ moduleTemperature53_BMS01 m53 : 15|8@0+ (1,-40) [-40|200] "C"  PT
 SG_ moduleTemperature54_BMS01 m54 : 15|8@0+ (1,-40) [-40|200] "C"  PT
 SG_ moduleTemperature55_BMS01 m55 : 15|8@0+ (1,-40) [-40|200] "C"  PT
 SG_ moduleTemperature56_BMS01 m56 : 15|8@0+ (1,-40) [-40|200] "C"  PT
 SG_ moduleTemperature57_BMS01 m57 : 15|8@0+ (1,-40) [-40|200] "C"  PT
 SG_ moduleTemperature58_BMS01 m58 : 15|8@0+ (1,-40) [-40|200] "C"  PT
 SG_ moduleTemperature59_BMS01 m59 : 15|8@0+ (1,-40) [-40|200] "C"  PT
 SG_ moduleTemperature60_BMS01 m60 : 15|8@0+ (1,-40) [-40|200] "C"  PT
 SG_ moduleTemperature61_BMS01 m61 : 15|8@0+ (1,-40) [-40|200] "C"  PT
 SG_ moduleTemperature62_BMS01 m62 : 15|8@0+ (1,-40) [-40|200] "C"  PT
 SG_ moduleTemperature63_BMS01 m63 : 15|8@0+ (1,-40) [-40|200] "C"  PT
 SG_ moduleTemperature64_BMS01 m64 : 15|8@0+ (1,-40) [-40|200] "C"  PT
 SG_ moduleTemperature65_BMS01 m65 : 15|8@0+ (1,-40) [-40|200] "C"  PT
 SG_ moduleTemperature66_BMS01 m66 : 15|8@0+ (1,-40) [-40|200] "C"  PT
 SG_ moduleTemperature67_BMS01 m67 : 15|8@0+ (1,-40) [-40|200] "C"  PT
 SG_ moduleTemperature68_BMS01 m68 : 15|8@0+ (1,-40) [-40|200] "C"  PT
 SG_ moduleTemperature69_BMS01 m69 : 15|8@0+ (1,-40) [-40|200] "C"  PT
 SG_ moduleTemperature70_BMS01 m70 : 15|8@0+ (1,-40) [-40|200] "C"  PT
 SG_ moduleTemperature71_BMS01 m71 : 15|8@0+ (1,-40) [-40|200] "C"  PT
 SG_ moduleTemperature72_BMS01 m72 : 15|8@0+ (1,-40) [-40|200] "C"  PT
 SG_ moduleTemperature73_BMS01 m73 : 15|8@0+ (1,-40) [-40|200] "C"  PT
 SG_ moduleTemperature74_BMS01 m74 : 15|8@0+ (1,-40) [-40|200] "C"  PT
 SG_ moduleTemperature75_BMS01 m75 : 15|8@0+ (1,-40) [-40|200] "C"  PT
 SG_ moduleTemperature76_BMS01 m76 : 15|8@0+ (1,-40) [-40|200] "C"  PT
 SG_ moduleTemperature77_BMS01 m77 : 15|8@0+ (1,-40) [-40|200] "C"  PT
 SG_ moduleTemperature78_BMS01 m78 : 15|8@0+ (1,-40) [-40|200] "C"  PT
 SG_ moduleTemperature79_BMS01 m79 : 15|8@0+ (1,-40) [-40|200] "C"  PT
 SG_ moduleTemperature80_BMS01 m80 : 15|8@0+ (1,-40) [-40|200] "C"  PT
 SG_ moduleTemperature81_BMS01 m81 : 15|8@0+ (1,-40) [-40|200] "C"  PT
 SG_ moduleTemperature82_BMS01 m82 : 15|8@0+ (1,-40) [-40|200] "C"  PT
 SG_ moduleTemperature83_BMS01 m83 : 15|8@0+ (1,-40) [-40|200] "C"  PT
 SG_ moduleTemperature84_BMS01 m84 : 15|8@0+ (1,-40) [-40|200] "C"  PT
 SG_ moduleTemperature85_BMS01 m85 : 15|8@0+ (1,-40) [-40|200] "C"  PT
 SG_ moduleTemperature86_BMS01 m86 : 15|8@0+ (1,-40) [-40|200] "C"  PT
 SG_ moduleTemperature87_BMS01 m87 : 15|8@0+ (1,-40) [-40|200] "C"  PT
 SG_ moduleTemperature88_BMS01 m88 : 15|8@0+ (1,-40) [-40|200] "C"  PT
 SG_ moduleTemperature89_BMS01 m89 : 15|8@0+ (1,-40) [-40|200] "C"  PT
 SG_ moduleTemperature90_BMS01 m90 : 15|8@0+ (1,-40) [-40|200] "C"  PT
 SG_ moduleTemperature91_BMS01 m91 : 15|8@0+ (1,-40) [-40|200] "C"  PT
 SG_ moduleTemperature92_BMS01 m92 : 15|8@0+ (1,-40) [-40|200] "C"  PT
 SG_ moduleTemperature93_BMS01 m93 : 15|8@0+ (1,-40) [-40|200] "C"  PT
 SG_ moduleTemperature94_BMS01 m94 : 15|8@0+ (1,-40) [-40|200] "C"  PT
 SG_ moduleTemperature95_BMS01 m95 : 15|8@0+ (1,-40) [-40|200] "C"  PT
 SG_ moduleTemperature96_BMS01 m96 : 15|8@0+ (1,-40) [-40|200] "C"  PT
 SG_ moduleTemperature97_BMS01 m97 : 15|8@0+ (1,-40) [-40|200] "C"  PT
 SG_ moduleTemperature98_BMS01 m98 : 15|8@0+ (1,-40) [-40|200] "C"  PT
 SG_ moduleTemperature99_BMS01 m99 : 15|8@0+ (1,-40) [-40|200] "C"  PT
 SG_ moduleTemperature100_BMS01 m100 : 15|8@0+ (1,-40) [-40|200] "C"  PT
 SG_ moduleTemperature101_BMS01 m101 : 15|8@0+ (1,-40) [-40|200] "C"  PT
 SG_ moduleTemperature102_BMS01 m102 : 15|8@0+ (1,-40) [-40|200] "C"  PT
 SG_ moduleTemperature103_BMS01 m103 : 15|8@0+ (1,-40) [-40|200] "C"  PT
 SG_ moduleTemperature104_BMS01 m104 : 15|8@0+ (1,-40) [-40|200] "C"  PT
 SG_ moduleTemperature105_BMS01 m105 : 15|8@0+ (1,-40) [-40|200] "C"  PT
 SG_ moduleTemperature106_BMS01 m106 : 15|8@0+ (1,-40) [-40|200] "C"  PT
 SG_ moduleTemperature107_BMS01 m107 : 15|8@0+ (1,-40) [-40|200] "C"  PT
 SG_ moduleTemperature108_BMS01 m108 : 15|8@0+ (1,-40) [-40|200] "C"  PT
 SG_ moduleTemperature109_BMS01 m109 : 15|8@0+ (1,-40) [-40|200] "C"  PT
 SG_ moduleTemperature110_BMS01 m110 : 15|8@0+ (1,-40) [-40|200] "C"  PT
 SG_ moduleTemperature111_BMS01 m111 : 15|8@0+ (1,-40) [-40|200] "C"  PT
 SG_ moduleTemperature112_BMS01 m112 : 15|8@0+ (1,-40) [-40|200] "C"  PT
 SG_ moduleTemperature113_BMS01 m113 : 15|8@0+ (1,-40) [-40|200] "C"  PT
 SG_ moduleTemperature114_BMS01 m114 : 15|8@0+ (1,-40) [-40|200] "C"  PT
 SG_ moduleTemperature115_BMS01 m115 : 15|8@0+ (1,-40) [-40|200] "C"  PT
 SG_ moduleTemperature116_BMS01 m116 : 15|8@0+ (1,-40) [-40|200] "C"  PT
 SG_ moduleTemperature117_BMS01 m117 : 15|8@0+ (1,-40) [-40|200] "C"  PT
 SG_ moduleTemperature118_BMS01 m118 : 15|8@0+ (1,-40) [-40|200] "C"  PT
 SG_ moduleTemperature119_BMS01 m119 : 15|8@0+ (1,-40) [-40|200] "C"  PT
 SG_ moduleTemperature120_BMS01 m120 : 15|8@0+ (1,-40) [-40|200] "C"  PT
 SG_ moduleTemperature121_BMS01 m121 : 15|8@0+ (1,-40) [-40|200] "C"  PT
 SG_ moduleTemperature122_BMS01 m122 : 15|8@0+ (1,-40) [-40|200] "C"  PT
 SG_ moduleTemperature123_BMS01 m123 : 15|8@0+ (1,-40) [-40|200] "C"  PT
 SG_ moduleTemperature124_BMS01 m124 : 15|8@0+ (1,-40) [-40|200] "C"  PT
 SG_ moduleTemperature125_BMS01 m125 : 15|8@0+ (1,-40) [-40|200] "C"  PT
 SG_ moduleTemperature126_BMS01 m126 : 15|8@0+ (1,-40) [-40|200] "C"  PT
 SG_ moduleTemperature127_BMS01 m127 : 15|8@0+ (1,-40) [-40|200] "C"  PT
 SG_ moduleTemperature128_BMS01 m128 : 15|8@0+ (1,-40) [-40|200] "C"  PT
 SG_ moduleTemperature129_BMS01 m129 : 15|8@0+ (1,-40) [-40|200] "C"  PT
 SG_ moduleTemperature130_BMS01 m130 : 15|8@0+ (1,-40) [-40|200] "C"  PT
 SG_ moduleTemperature131_BMS01 m131 : 15|8@0+ (1,-40) [-40|200] "C"  PT
 SG_ moduleTemperature132_BMS01 m132 : 15|8@0+ (1,-40) [-40|200] "C"  PT
 SG_ moduleTemperature133_BMS01 m133 : 15|8@0+ (1,-40) [-40|200] "C"  PT
 SG_ moduleTemperature134_BMS01 m134 : 15|8@0+ (1,-40) [-40|200] "C"  PT
 SG_ moduleTemperature135_BMS01 m135 : 15|8@0+ (1,-40) [-40|200] "C"  PT
 SG_ moduleTemperature136_BMS01 m136 : 15|8@0+ (1,-40) [-40|200] "C"  PT
 SG_ moduleTemperature137_BMS01 m137 : 15|8@0+ (1,-40) [-40|200] "C"  PT
 SG_ moduleTemperature138_BMS01 m138 : 15|8@0+ (1,-40) [-40|200] "C"  PT
 SG_ moduleTemperature139_BMS01 m139 : 15|8@0+ (1,-40) [-40|200] "C"  PT
 SG_ moduleTemperature140_BMS01 m140 : 15|8@0+ (1,-40) [-40|200] "C"  PT
 SG_ moduleTemperature141_BMS01 m141 : 15|8@0+ (1,-40) [-40|200] "C"  PT
 SG_ moduleTemperature142_BMS01 m142 : 15|8@0+ (1,-40) [-40|200] "C"  PT
 SG_ moduleTemperature143_BMS01 m143 : 15|8@0+ (1,-40) [-40|200] "C"  PT
 SG_ moduleTemperature144_BMS01 m144 : 15|8@0+ (1,-40) [-40|200] "C"  PT
 SG_ moduleTemperature145_BMS01 m145 : 15|8@0+ (1,-40) [-40|200] "C"  PT
 SG_ moduleTemperature146_BMS01 m146 : 15|8@0+ (1,-40) [-40|200] "C"  PT
 SG_ moduleTemperature147_BMS01 m147 : 15|8@0+ (1,-40) [-40|200] "C"  PT
 SG_ moduleTemperature148_BMS01 m148 : 15|8@0+ (1,-40) [-40|200] "C"  PT
 SG_ moduleTemperature149_BMS01 m149 : 15|8@0+ (1,-40) [-40|200] "C"  PT
 SG_ moduleTemperature150_BMS01 m150 : 15|8@0+ (1,-40) [-40|200] "C"  PT
 SG_ moduleTemperature151_BMS01 m151 : 15|8@0+ (1,-40) [-40|200] "C"  PT
 SG_ moduleTemperature152_BMS01 m152 : 15|8@0+ (1,-40) [-40|200] "C"  PT
 SG_ moduleTemperature153_BMS01 m153 : 15|8@0+ (1,-40) [-40|200] "C"  PT
 SG_ moduleTemperature154_BMS01 m154 : 15|8@0+ (1,-40) [-40|200] "C"  PT
 SG_ moduleTemperature155_BMS01 m155 : 15|8@0+ (1,-40) [-40|200] "C"  PT
 SG_ moduleTemperature156_BMS01 m156 : 15|8@0+ (1,-40) [-40|200] "C"  PT
 SG_ moduleTemperature157_BMS01 m157 : 15|8@0+ (1,-40) [-40|200] "C"  PT
 SG_ moduleTemperature158_BMS01 m158 : 15|8@0+ (1,-40) [-40|200] "C"  PT
 SG_ moduleTemperature159_BMS01 m159 : 15|8@0+ (1,-40) [-40|200] "C"  PT
 SG_ moduleTemperature160_BMS01 m160 : 15|8@0+ (1,-40) [-40|200] "C"  PT
 SG_ moduleTemperature161_BMS01 m161 : 15|8@0+ (1,-40) [-40|200] "C"  PT
 SG_ moduleTemperature162_BMS01 m162 : 15|8@0+ (1,-40) [-40|200] "C"  PT
 SG_ moduleTemperature163_BMS01 m163 : 15|8@0+ (1,-40) [-40|200] "C"  PT
 SG_ moduleTemperature164_BMS01 m164 : 15|8@0+ (1,-40) [-40|200] "C"  PT
 SG_ moduleTemperature165_BMS01 m165 : 15|8@0+ (1,-40) [-40|200] "C"  PT
 SG_ moduleTemperature166_BMS01 m166 : 15|8@0+ (1,-40) [-40|200] "C"  PT
 SG_ moduleTemperature167_BMS01 m167 : 15|8@0+ (1,-40) [-40|200] "C"  PT
 SG_ moduleTemperature168_BMS01 m168 : 15|8@0+ (1,-40) [-40|200] "C"  PT
 SG_ moduleTemperature169_BMS01 m169 : 15|8@0+ (1,-40) [-40|200] "C"  PT
 SG_ moduleTemperature170_BMS01 m170 : 15|8@0+ (1,-40) [-40|200] "C"  PT
 SG_ moduleTemperature171_BMS01 m171 : 15|8@0+ (1,-40) [-40|200] "C"  PT
 SG_ moduleTemperature172_BMS01 m172 : 15|8@0+ (1,-40) [-40|200] "C"  PT
 SG_ moduleTemperature173_BMS01 m173 : 15|8@0+ (1,-40) [-40|200] "C"  PT
 SG_ moduleTemperature174_BMS01 m174 : 15|8@0+ (1,-40) [-40|200] "C"  PT
 SG_ moduleTemperature175_BMS01 m175 : 15|8@0+ (1,-40) [-40|200] "C"  PT
 SG_ moduleTemperature176_BMS01 m176 : 15|8@0+ (1,-40) [-40|200] "C"  PT
 SG_ moduleTemperature177_BMS01 m177 : 15|8@0+ (1,-40) [-40|200] "C"  PT
 SG_ moduleTemperature178_BMS01 m178 : 15|8@0+ (1,-40) [-40|200] "C"  PT
 SG_ moduleTemperature179_BMS01 m179 : 15|8@0+ (1,-40) [-40|200] "C"  PT
 SG_ moduleTemperature180_BMS01 m180 : 15|8@0+ (1,-40) [-40|200] "C"  PT
 SG_ moduleTemperature181_BMS01 m181 : 15|8@0+ (1,-40) [-40|200] "C"  PT
 SG_ moduleTemperature182_BMS01 m182 : 15|8@0+ (1,-40) [-40|200] "C"  PT
 SG_ moduleTemperature183_BMS01 m183 : 15|8@0+ (1,-40) [-40|200] "C"  PT
 SG_ moduleTemperature184_BMS01 m184 : 15|8@0+ (1,-40) [-40|200] "C"  PT
 SG_ moduleTemperature185_BMS01 m185 : 15|8@0+ (1,-40) [-40|200] "C"  PT
 SG_ moduleTemperature186_BMS01 m186 : 15|8@0+ (1,-40) [-40|200] "C"  PT
 SG_ moduleTemperature187_BMS01 m187 : 15|8@0+ (1,-40) [-40|200] "C"  PT
 SG_ moduleTemperature188_BMS01 m188 : 15|8@0+ (1,-40) [-40|200] "C"  PT
 SG_ moduleTemperature189_BMS01 m189 : 15|8@0+ (1,-40) [-40|200] "C"  PT
 SG_ moduleTemperature190_BMS01 m190 : 15|8@0+ (1,-40) [-40|200] "C"  PT
 SG_ moduleTemperature191_BMS01 m191 : 15|8@0+ (1,-40) [-40|200] "C"  PT
 SG_ moduleTemperature192_BMS01 m192 : 15|8@0+ (1,-40) [-40|200] "C"  PT

BO_ 897 BMS02_DebugEventMap10: 8 BMS02
 SG_ DEM319_HV_DISABLE_DURING_S_BMS02 : 55|2@0+ (1,0) [0|3] ""  PT
 SG_ DEM318_HV_ENABLE_IMPLAUSIB_BMS02 : 53|2@0+ (1,0) [0|3] ""  PT
 SG_ DEM317_STRING_SUSPECT_OPEN_BMS02 : 51|2@0+ (1,0) [0|3] ""  PT
 SG_ DEM316_UNEXPCTD_BMS_ON_CAN_BMS02 : 49|2@0+ (1,0) [0|3] ""  PT
 SG_ DEM315_HV_WITHSTAND_TESTS__BMS02 : 63|2@0+ (1,0) [0|3] ""  PT
 SG_ DEM314_OBC_PILOT_ERROR_BMS02 : 61|2@0+ (1,0) [0|3] ""  PT
 SG_ DEM313_OBC_PILOT_HIGH_BMS02 : 59|2@0+ (1,0) [0|3] ""  PT
 SG_ DEM312_OBC_PROXIMITY_ERROR_BMS02 : 57|2@0+ (1,0) [0|3] ""  PT
 SG_ DEM311_CTRS_END_OF_LIFE_WA_BMS02 : 39|2@0+ (1,0) [0|3] ""  PT
 SG_ DEM310_BMSMIA_STRNGMSTR_AL_BMS02 : 37|2@0+ (1,0) [0|3] ""  PT
 SG_ DEM309_VOLTAGE_BRICKOV_WAR_BMS02 : 35|2@0+ (1,0) [0|3] ""  PT
 SG_ DEM308_PRESSURE_FLT_BMS02 : 33|2@0+ (1,0) [0|3] ""  PT
 SG_ DEM307_PRESSURE_MIA_BMS02 : 47|2@0+ (1,0) [0|3] ""  PT
 SG_ DEM306_SW_VERSION_MISMATCH_BMS02 : 45|2@0+ (1,0) [0|3] ""  PT
 SG_ DEM305_MODULET_OVERTEMP_WA_BMS02 : 43|2@0+ (1,0) [0|3] ""  PT
 SG_ DEM304_PCHG_OPENCIRCUIT_IN_BMS02 : 41|2@0+ (1,0) [0|3] ""  PT
 SG_ DEM303_MODULET_UNDERTEMP_W_BMS02 : 23|2@0+ (1,0) [0|3] ""  PT
 SG_ DEM302_MODULET_UT_BMS02 : 21|2@0+ (1,0) [0|3] ""  PT
 SG_ DEM301_FUSI_LOCK_BMS02 : 19|2@0+ (1,0) [0|3] ""  PT
 SG_ DEM300_DEBUG_SM_DISABLED_BMS02 : 17|2@0+ (1,0) [0|3] ""  PT
 SG_ DEM299_5V_SENSOR_SUPPLY_OU_BMS02 : 31|2@0+ (1,0) [0|3] ""  PT
 SG_ DEM298_IMPL_DRIVE_REQUEST_BMS02 : 29|2@0+ (1,0) [0|0] ""  PT
 SG_ DEM297_PCHG2_OPENCIRCUIT_BMS02 : 27|2@0+ (1,0) [0|0] ""  PT
 SG_ DEM296_CTRSAUX_IMPLAUSIBLE_BMS02 : 25|2@0+ (1,0) [0|0] ""  PT
 SG_ DEM295_CTRSAUX_LINKV_UNSAF_BMS02 : 7|2@0+ (1,0) [0|0] ""  PT
 SG_ DEM294_CANRX_PT_EMERGENCY_BMS02 : 5|2@0+ (1,0) [0|0] ""  PT
 SG_ DEM293_SBC_LDT_IMPLAUSIBLE_BMS02 : 3|2@0+ (1,0) [0|0] ""  PT
 SG_ DEM292_NUM_EXPECTED_STRING_BMS02 : 1|2@0+ (1,0) [0|0] ""  PT
 SG_ DEM291_NUM_EXPECTED_STRING_BMS02 : 15|2@0+ (1,0) [0|0] ""  PT
 SG_ DEM290_CMB_ONBOARD_DEFECT_BMS02 : 13|2@0+ (1,0) [0|0] ""  PT
 SG_ DEM289_TEMP_STATE_LATCHED_BMS02 : 11|2@0+ (1,0) [0|0] ""  PT
 SG_ DEM288_CURR_STATE_LATCHED_BMS02 : 9|2@0+ (1,0) [0|0] ""  PT

BO_ 961 BMS02_DebugSlowMpex2: 8 BMS02
 SG_ balancingInDriveTimer_BMS02 m18 : 15|16@0+ (1,0) [0|65535] "s"  PT
 SG_ SOCRestPolarization_BMS02 m11 : 63|8@0+ (0.002,0) [0|0.51] "V"  PT
 SG_ CoolantSensorState_BMS02 m1 : 51|2@0+ (1,0) [0|1] ""  PT
 SG_ temperatureModelOffset_BMS02 m7 : 15|8@0+ (0.1,0) [0|25.5] "C"  PT
 SG_ SOHCMinBrickHighEst_BMS02 m4 : 15|8@0+ (0.3,50) [50|126.5] "PCT"  PT
 SG_ SOHCMaxBrickHighEst_BMS02 m6 : 15|8@0+ (0.3,50) [50|126.5] "PCT"  PT
 SG_ regenCurrOpLkyBktThrs1_BMS02 m17 : 63|8@0+ (0.5,0) [0|127.5] "PCT"  PT
 SG_ dischargeCurrOpLkyBktThrs1_BMS02 m10 : 15|8@0+ (0.5,0) [0|127.5] "PCT"  PT
 SG_ regenCurrentOpLoadValue_BMS02 m16 : 15|8@0+ (0.5,0) [0|127.5] "PCT"  PT
 SG_ dischargeCurrOpLoadValue_BMS02 m15 : 15|8@0+ (0.5,0) [0|127.5] "PCT"  PT
 SG_ minBrickVoltageLimit_BMS02 m16 : 55|16@0+ (0.0001,0) [0|6.5535] "V"  PT
 SG_ SOHSuitableOCVRecal_BMS02 m1 : 49|1@0+ (1,0) [0|1] ""  PT
 SG_ currentModule3Integral_BMS02 m17 : 47|16@0+ (100,-3200000) [-3200000|3353500] "As"  PT
 SG_ currentModule2Integral_BMS02 m17 : 31|16@0+ (100,-3200000) [-3200000|3353500] "As"  PT
 SG_ currentModule1Integral_BMS02 m17 : 15|16@0+ (100,-3200000) [-3200000|3353500] "As"  PT
 SG_ currentModuleMin_BMS02 m16 : 23|16@0+ (0.1,-3200) [-3200|3200] "A"  PT
 SG_ currentModuleMax_BMS02 m16 : 39|16@0+ (0.1,-3200) [-3200|3200] "A"  PT
 SG_ maxBrickVoltageSync_BMS02 m9 : 39|16@0+ (0.0001,0) [0|6.5] "V"  PT
 SG_ minBrickVoltageSync_BMS02 m9 : 55|16@0+ (0.0001,0) [0|6.5] "V"  PT
 SG_ SOHCMinBrickLowEst_BMS02 m8 : 15|8@0+ (0.3,50) [50|126.5] "PCT"  PT
 SG_ SOHCMaxBrickLowEst_BMS02 m9 : 15|8@0+ (0.3,50) [50|126.5] "PCT"  PT
 SG_ gradLimSOC_BMS02 m10 : 39|16@0+ (0.002,0) [0|131.07] "PCT"  PT
 SG_ SOCRecalSlowOp_BMS02 m14 : 55|16@0+ (0.0001,-2) [-2|4.5535] "V"  PT
 SG_ SOHCMinIndex_BMS02 m12 : 39|16@0+ (1,0) [0|65535] ""  PT
 SG_ SOHCMaxIndex_BMS02 m12 : 55|16@0+ (1,0) [0|65535] ""  PT
 SG_ SOHRMinRegen_BMS02 m11 : 39|8@0+ (1,50) [50|305] "PCT"  PT
 SG_ SOHRMinDchg_BMS02 m11 : 15|8@0+ (1,50) [50|305] "PCT"  PT
 SG_ SOHRMeanRegen_BMS02 m11 : 47|8@0+ (1,50) [50|305] "PCT"  PT
 SG_ SOHRMeanDchg_BMS02 m11 : 23|8@0+ (1,50) [50|305] "PCT"  PT
 SG_ SOHRMaxRegen_BMS02 m11 : 55|8@0+ (1,50) [50|305] "PCT"  PT
 SG_ SOHRMaxDchg_BMS02 m11 : 31|8@0+ (1,50) [50|305] "PCT"  PT
 SG_ SOHCMin_BMS02 m12 : 15|8@0+ (0.3,50) [50|126.5] "PCT"  PT
 SG_ SOHCMean_BMS02 m12 : 23|8@0+ (0.3,50) [50|126.5] "PCT"  PT
 SG_ SOHCMax_BMS02 m12 : 31|8@0+ (0.3,50) [50|126.5] "PCT"  PT
 SG_ ppRegenCurrLimitPredShort_BMS02 m6 : 23|8@0+ (2,0) [0|510] "A"  PT
 SG_ ppRegenCurrLimitPredLong_BMS02 m6 : 31|8@0+ (2,0) [0|510] "A"  PT
 SG_ ppDchgCurrLimitPredShort_BMS02 m13 : 55|8@0+ (2,-510) [-510|0] "A"  PT
 SG_ ppDchgCurrLimitPredLong_BMS02 m13 : 63|8@0+ (2,-510) [-510|0] "A"  PT
 SG_ ppInconsistentPol_BMS02 m1 : 48|1@0+ (1,0) [0|0] ""  PT
 SG_ ppPolarizationV_BMS02 m3 : 55|16@0+ (0.0001,-3) [-3|3.5535] "V"  PT
 SG_ SOCRecalMinOCVEst_BMS02 m13 : 39|16@0+ (0.0001,0) [0|6.5535] "V"  PT
 SG_ SOCRecalMaxOCVEst_BMS02 m14 : 39|16@0+ (0.0001,0) [0|6.5535] "V"  PT
 SG_ SOCRecalMinSOCUpp_BMS02 m13 : 31|8@0+ (0.5,0) [0|127.5] "PCT"  PT
 SG_ SOCRecalMinSOCLow_BMS02 m13 : 15|8@0+ (0.5,0) [0|127.5] "PCT"  PT
 SG_ SOCRecalMinSOC_BMS02 m13 : 23|8@0+ (0.5,0) [0|127.5] "PCT"  PT
 SG_ SOCRecalMaxSOCUpp_BMS02 m14 : 31|8@0+ (0.5,0) [0|127.5] "PCT"  PT
 SG_ SOCRecalMaxSOCLow_BMS02 m14 : 15|8@0+ (0.5,0) [0|127.5] "PCT"  PT
 SG_ SOCRecalMaxSOC_BMS02 m14 : 23|8@0+ (0.5,0) [0|127.5] "PCT"  PT
 SG_ ppNewtonRootInRangeRegen_BMS02 m5 : 12|1@0+ (1,0) [0|0] ""  PT
 SG_ ppNewtonRootInRangeDchg_BMS02 m5 : 8|1@0+ (1,0) [0|0] ""  PT
 SG_ ppNewtonStepsRegen_BMS02 m5 : 15|3@0+ (1,0) [0|1] ""  PT
 SG_ ppNewtonStepsDchg_BMS02 m5 : 11|3@0+ (1,0) [0|1] ""  PT
 SG_ ppNewtonRegenVRes_BMS02 m5 : 31|8@0+ (0.001,-0.1) [-0.1|0.155] "V"  PT
 SG_ ppNewtonDchgVRes_BMS02 m5 : 23|8@0+ (0.001,-0.1) [-0.1|0.155] "V"  PT
 SG_ ppMinModelAlphaTarget_BMS02 m3 : 15|8@0+ (0.02,0) [0|5.1] ""  PT
 SG_ ppMaxModelAlphaTarget_BMS02 m1 : 63|8@0+ (0.02,0) [0|5.1] ""  PT
 SG_ ppLearningTauRegen_BMS02 m2 : 55|16@0+ (0.2,0) [0|0] "s"  PT
 SG_ ppLearningCriterionDyn_BMS02 m2 : 15|8@0+ (0.005,0) [0|0] ""  PT
 SG_ ppLearningCriterionAbs_BMS02 m1 : 15|8@0+ (0.005,0) [0|0] ""  PT
 SG_ ppLearningCriterionJoin_BMS02 m0 : 15|8@0+ (0.005,0) [0|0] ""  PT
 SG_ ppMaxModelMeasV_BMS02 m7 : 23|16@0+ (0.0001,0) [0|6.5535] "V"  PT
 SG_ currentRedundant_BMS02 m15 : 23|16@0+ (0.1,-3200) [-3200|3200] "A"  PT
 SG_ currentModule3_BMS02 m10 : 55|16@0+ (0.1,-3200) [-3200|3200] "A"  PT
 SG_ currentModule2_BMS02 m10 : 23|16@0+ (0.1,-3200) [-3200|3200] "A"  PT
 SG_ currentModule1_BMS02 m9 : 23|16@0+ (0.1,-3200) [-3200|3200] "A"  PT
 SG_ ppMeanRegenIntRes_BMS02 m6 : 55|16@0+ (0.01,0) [0|655.35] "mOhm"  PT
 SG_ ppMeanDchgIntRes_BMS02 m6 : 39|16@0+ (0.01,0) [0|655.35] "mOhm"  PT
 SG_ ppMinModelVoltageIndex_BMS02 m5 : 39|16@0+ (1,0) [0|65535] ""  PT
 SG_ ppMinModelLowpassV_BMS02 m4 : 55|16@0+ (0.0001,0) [0|0] "V"  PT
 SG_ ppMaxModelVoltageIndex_BMS02 m5 : 55|16@0+ (1,0) [0|65535] ""  PT
 SG_ ppMaxModelLowpassV_BMS02 m7 : 55|16@0+ (0.0001,0) [0|0] "V"  PT
 SG_ ppLearningTauDischarge_BMS02 m0 : 55|16@0+ (0.2,0) [0|0] "s"  PT
 SG_ ppMaxRegenAlpha_BMS02 m15 : 39|16@0+ (0.0001,0) [0|6.5535] ""  PT
 SG_ ppMaxModelledV_BMS02 m7 : 39|16@0+ (0.0001,0) [0|6.5535] "V"  PT
 SG_ ppMinDchgAlpha_BMS02 m15 : 55|16@0+ (0.0001,0) [0|6.5535] ""  PT
 SG_ ppMinModelledV_BMS02 m4 : 39|16@0+ (0.0001,0) [0|6.5535] "V"  PT
 SG_ ppMinModelMeasV_BMS02 m4 : 23|16@0+ (0.0001,0) [0|6.5535] "V"  PT
 SG_ debugSlowMpex2_BMS02 M : 7|8@0+ (1,0) [0|0] ""  PT
 SG_ ppRegenCurrPredShort_BMS02 m2 : 23|16@0+ (0.02,0) [0|1310.7] "A"  PT
 SG_ ppDischgCurrPredLong_BMS02 m0 : 39|16@0+ (0.05,-3200) [-3200|0] "A"  PT
 SG_ ppDischgCurrPredShort_BMS02 m0 : 23|16@0+ (0.05,-3200) [-3200|0] "A"  PT
 SG_ ppRegenCurrPredLong_BMS02 m2 : 39|16@0+ (0.02,0) [0|1310.7] "A"  PT
 SG_ ppRegenVPredShort_BMS02 m3 : 23|16@0+ (0.02,0) [0|1310.7] "V"  PT
 SG_ ppDischgVPredShort_BMS02 m1 : 23|16@0+ (0.02,0) [0|1310.7] "V"  PT
 SG_ ppRegenVPredLong_BMS02 m3 : 39|16@0+ (0.02,0) [0|1310.7] "V"  PT
 SG_ ppDischgVPredLong_BMS02 m1 : 39|16@0+ (0.02,0) [0|1310.7] "V"  PT
 SG_ SOHDeltaSOCCoulomb_BMS02 m8 : 23|16@0+ (0.005,-150) [-150|177.675] "PCT"  PT
 SG_ SOHAbsDeltaSOCCoulomb_BMS02 m8 : 39|16@0+ (0.05,0) [0|3276.75] "PCT"  PT
 SG_ SOHLastOCVRecalMinSOC_BMS02 m8 : 55|8@0+ (0.393,0) [0|100.215] "PCT"  PT
 SG_ SOHbalancingTimeMinSOH_BMS02 m8 : 63|8@0+ (1,0) [0|255] "Min"  PT

BO_ 1793 BMS02_DebugFastMpex2: 8 BMS02
 SG_ chargerDCOutV_BMS02 m1 : 55|16@0+ (0.04,-1250) [-1250|1250] "V"  PT
 SG_ DIGIO_CHARGERCC_BMS02 m1 : 10|1@0+ (1,0) [0|0] ""  PT
 SG_ chargerProximity_BMS02 m1 : 23|8@0+ (0.02,0) [0|12] "V"  PT
 SG_ chargerPilot_BMS02 m1 : 31|8@0+ (0.05,0) [0|12.75] "V"  PT
 SG_ chargerCurrAvail_BMS02 m1 : 39|8@0+ (0.5,0) [0|127.5] "A"  PT
 SG_ chargerCtrOn_BMS02 m1 : 8|1@0+ (1,0) [0|0] ""  PT
 SG_ chargerOn_BMS02 m1 : 9|1@0+ (1,0) [0|0] ""  PT
 SG_ debugFastMpex2_BMS02 M : 7|8@0+ (1,0) [0|0] ""  PT
 SG_ posPackDbg_BMS02 m0 : 39|16@0+ (0.04,-1250) [-1250|1250] "V"  PT
 SG_ negPackDbg_BMS02 m0 : 55|16@0+ (0.04,-1250) [-1250|1250] "V"  PT
 SG_ packVoltageHVMeas_BMS02 m0 : 23|16@0+ (0.04,-1250) [-1250|1250] "V"  PT

BO_ 1857 BMS02_DebugSlowMpex1: 8 BMS02
 SG_ SOHRecentChange_BMS02 m43 : 15|8@0+ (0.1,-15) [-15|10.5] ""  PT
 SG_ SOHConvergenceIndicator_BMS02 m43 : 31|8@0+ (1,0) [0|255] ""  PT
 SG_ SOHConvergenceCounter_BMS02 m43 : 39|8@0+ (0.024,3) [0|6] ""  PT
 SG_ SOHMinFiltered_BMS02 m43 : 23|8@0+ (0.3,50) [50|126.5] "PCT"  PT
 SG_ prechargeCyMatchWaitTime_BMS02 m43 : 47|16@0+ (1,0) [0|65535] "ms"  PT
 SG_ medianModuleTempGrp2_BMS02 m13 : 63|8@0+ (1,-40) [-40|200] "C"  PT
 SG_ medianModuleTempGrp1_BMS02 m13 : 55|8@0+ (1,-40) [-40|200] "C"  PT
 SG_ coolantWarningtAlert_BMS02 m12 : 49|2@0+ (1,0) [0|3] ""  PT
 SG_ coolantFaultAlert_BMS02 m12 : 51|2@0+ (1,0) [0|3] ""  PT
 SG_ hvilShutdownStrategy_BMS02 m42 : 63|8@0+ (1,0) [0|255] ""  PT
 SG_ J1939_nmState m12 : 55|4@0+ (1,0) [0|0] ""  PT
 SG_ PrechargeXCapMin_BMS02 m42 : 47|16@0+ (0.01,0) [0|1] "mF"  PT
 SG_ LimpHomeTimeOut_BMS02 m42 : 15|32@0+ (1,0) [0|4294967295] "ms"  PT
 SG_ hvWithstandTests_BMS02 m40 : 15|8@0+ (1,0) [0|255] ""  PT
 SG_ aux3prechargeState_BMS02 m41 : 19|4@0+ (1,0) [0|0] ""  PT
 SG_ aux2prechargeState_BMS02 m41 : 31|4@0+ (1,0) [0|0] ""  PT
 SG_ aux1prechargeState_BMS02 m41 : 27|4@0+ (1,0) [0|0] ""  PT
 SG_ auxLinkVoltage_BMS02 m40 : 23|16@0+ (0.02,0) [0|1310.7] "V"  PT
 SG_ invalidModuleVoltageFlags_BMS02 m41 : 39|32@0+ (1,0) [0|0] ""  PT
 SG_ invalidModuleTempFlags_BMS02 m40 : 39|32@0+ (1,0) [0|0] ""  PT
 SG_ pumpSpeedExpected_BMS02 m30 : 15|8@0+ (0.4,0) [0|102] "%"  PT
 SG_ rangeRequestIgnoreVehicle m28 : 55|4@0+ (1,0) [0|65535] ""  PT
 SG_ rangeRequestEepromValue m28 : 63|4@0+ (1,0) [0|65535] ""  PT
 SG_ pressure2_BMS02 m35 : 31|8@0+ (0.4,0) [0|19] "psi"  PT
 SG_ calibration_version_BMS02 m37 : 63|8@0+ (1,0) [0|0] ""  PT
 SG_ currentLowTimer_BMS02 m39 : 55|16@0+ (1,0) [0|65535] "s"  PT
 SG_ auxCntrrOpenUnderLoadCntr_BMS02 m39 : 39|16@0+ (1,0) [0|0] ""  PT
 SG_ rabbitContactorState_BMS02 m34 : 31|8@0+ (1,0) [0|255] ""  PT
 SG_ analogIsenseSupplyCurr_BMS02 m37 : 55|8@0+ (0.04,0) [0|10] "A"  PT
 SG_ pumpSpeedReqCoolPrfmc_BMS02 m29 : 15|8@0+ (1,0) [0|0] "PCT"  PT
 SG_ microsarOs_IdleTask_OsCr0_BMS02 m39 : 23|8@0+ (1,0) [0|100] "PCT"  PT
 SG_ microsarOs_BswTask_BMS02 m39 : 15|8@0+ (1,0) [0|100] "PCT"  PT
 SG_ microsarOs_InitTask_BMS02 m39 : 31|8@0+ (1,0) [0|100] "PCT"  PT
 SG_ microsarOs_ApplTask_1Hz_BMS02 m38 : 63|8@0+ (1,0) [0|100] "PCT"  PT
 SG_ microsarOs_ApplTask_10Hz_BMS02 m38 : 55|8@0+ (1,0) [0|100] "PCT"  PT
 SG_ microsarOs_ApplTask_100Hz_BMS02 m38 : 47|8@0+ (1,0) [0|100] "PCT"  PT
 SG_ microsarOs_ApplLowTask_BMS02 m38 : 39|8@0+ (1,0) [0|100] "PCT"  PT
 SG_ microsarOs_ApplLateInit_BMS02 m38 : 31|8@0+ (1,0) [0|100] "PCT"  PT
 SG_ microsarOs_ApplHighTask_BMS02 m38 : 23|8@0+ (1,0) [0|100] "PCT"  PT
 SG_ microsarOs_ApplEarlyInit_BMS02 m38 : 15|8@0+ (1,0) [0|100] "PCT"  PT
 SG_ pumpRecoveryAttempts_BMS02 m31 : 15|8@0+ (1,0) [0|0] ""  PT
 SG_ appTaskBSWMaxDuration_BMS02 m37 : 47|8@0+ (0.5,0) [0|100] "PCT"  PT
 SG_ appTaskApplHighMaxDuration_BMS02 m37 : 15|16@0+ (0.5,0) [0|100] "PCT"  PT
 SG_ appTask1HzMaxDuration_BMS02 m36 : 63|8@0+ (0.5,0) [0|100] "PCT"  PT
 SG_ appTask100HzMaxDuration_BMS02 m36 : 47|8@0+ (0.5,0) [0|100] "PCT"  PT
 SG_ appTask10HzMaxDuration_BMS02 m36 : 55|8@0+ (0.5,0) [0|100] "PCT"  PT
 SG_ appTask100HzDuration_BMS02 m36 : 15|8@0+ (0.5,0) [0|100] "PCT"  PT
 SG_ appTask10HzDuration_BMS02 m36 : 23|8@0+ (0.5,0) [0|100] "PCT"  PT
 SG_ appTask1HzDuration_BMS02 m36 : 31|8@0+ (0.5,0) [0|100] "PCT"  PT
 SG_ appTaskBSWDuration_BMS02 m36 : 39|8@0+ (0.5,0) [0|100] "PCT"  PT
 SG_ appTaskApplHighDuration_BMS02 m37 : 31|16@0+ (0.5,0) [0|100] "PCT"  PT
 SG_ iumprMaxRatioDTCId_BMS02 m35 : 15|8@0+ (1,0) [0|0] ""  PT
 SG_ iumprMaxRatio_BMS02 m35 : 23|8@0+ (1,0) [0|0] ""  PT
 SG_ iumprMinRatioDTCId_BMS02 m33 : 63|8@0+ (1,0) [0|0] ""  PT
 SG_ iumprMinRatio_BMS02 m33 : 55|8@0+ (1,0) [0|0] ""  PT
 SG_ eepromWriteCyclesMax_BMS02 m11 : 55|16@0+ (64,0) [0|0] ""  PT
 SG_ eepromWriteCyclesUds_BMS02 m10 : 55|8@0+ (1,0) [0|0] ""  PT
 SG_ eepromWriteCyclesStat_BMS02 m10 : 63|8@0+ (1,0) [0|0] ""  PT
 SG_ eepromWriteCyclesSoh_BMS02 m11 : 47|8@0+ (1,0) [0|0] ""  PT
 SG_ fluidLvlCount_BMS02 m34 : 15|8@0+ (1,0) [0|255] ""  PT
 SG_ fluidLvlSensr2_BMS02 m34 : 19|2@0+ (1,0) [0|0] ""  PT
 SG_ fluidLvlSensr1_BMS02 m34 : 17|2@0+ (1,0) [0|0] ""  PT
 SG_ pumpSpeedReqVhcleSpeed_BMS02 m2 : 15|8@0+ (1,0) [0|0] "PCT"  PT
 SG_ appTaskBSWCpuUsage_BMS02 m18 : 15|8@0+ (0.5,0) [0|100] "PCT"  PT
 SG_ appTask200HzCpuUsage_BMS02 m17 : 15|8@0+ (0.5,0) [0|100] "PCT"  PT
 SG_ SWVersionBL_BMS02 m34 : 39|32@0+ (1,0) [0|4294967295] ""  PT
 SG_ SWVersionApp_BMS02 m35 : 39|32@0+ (1,0) [0|4294967295] ""  PT
 SG_ hvSNACounter_BMS02 m31 : 23|16@0+ (1,0) [0|0] ""  PT
 SG_ pyroState_BMS02 m28 : 59|4@0+ (1,0) [0|0] ""  PT
 SG_ ecuSerialNrChar15_BMS02 m33 : 47|8@0+ (1,0) [0|0] ""  PT
 SG_ ecuSerialNrChar14_BMS02 m33 : 39|8@0+ (1,0) [0|0] ""  PT
 SG_ ecuSerialNrChar13_BMS02 m33 : 31|8@0+ (1,0) [0|0] ""  PT
 SG_ ecuSerialNrChar12_BMS02 m33 : 23|8@0+ (1,0) [0|0] ""  PT
 SG_ ecuSerialNrChar11_BMS02 m32 : 63|8@0+ (1,0) [0|0] ""  PT
 SG_ ecuSerialNrChar10_BMS02 m32 : 55|8@0+ (1,0) [0|0] ""  PT
 SG_ ecuSerialNrChar09_BMS02 m32 : 47|8@0+ (1,0) [0|0] ""  PT
 SG_ ecuSerialNrChar08_BMS02 m32 : 39|8@0+ (1,0) [0|0] ""  PT
 SG_ ecuSerialNrChar07_BMS02 m32 : 31|8@0+ (1,0) [0|0] ""  PT
 SG_ ecuSerialNrChar06_BMS02 m32 : 23|8@0+ (1,0) [0|0] ""  PT
 SG_ ecuSerialNrChar05_BMS02 m32 : 15|8@0+ (1,0) [0|0] ""  PT
 SG_ analogGPIO1Current_BMS02 m22 : 39|8@0+ (0.015,0) [0|3.825] "A"  PT
 SG_ analogGPIO1Volt_BMS02 m22 : 55|8@0+ (0.1,0) [0|25] "V"  PT
 SG_ analogGPIO2Current_BMS02 m22 : 47|8@0+ (0.015,0) [0|3.825] "A"  PT
 SG_ analogGPIO2Volt_BMS02 m22 : 63|8@0+ (0.1,0) [0|25] "V"  PT
 SG_ pumpSpeedReqLoadValue_BMS02 m22 : 15|8@0+ (1,0) [0|0] "PCT"  PT
 SG_ ssaRTYear_BMS02 m31 : 55|16@0+ (1,0) [0|0] "yyyy"  PT
 SG_ ssaRTMonth_BMS02 m31 : 47|8@0+ (1,0) [0|0] "mm"  PT
 SG_ ssaRTDay_BMS02 m31 : 39|8@0+ (1,0) [0|0] "dd"  PT
 SG_ ssaTimeMRealTimeOffset_BMS02 m30 : 23|48@0+ (1,0) [0|0] ""  PT
 SG_ ssaTimeMTickCount_BMS02 m29 : 23|48@0+ (1,0) [0|0] ""  PT
 SG_ appTask50HzStackUsage_BMS02 m24 : 15|8@0+ (0.5,0) [0|100] "PCT"  PT
 SG_ OBDMILRequested_BMS02 m28 : 49|2@0+ (1,0) [0|3] ""  PT
 SG_ OBDConfirmedDTCsCount_BMS02 m28 : 15|8@0+ (1,0) [0|255] ""  PT
 SG_ OBDFirstConfirmedDTC_BMS02 m28 : 31|8@0+ (1,0) [0|255] ""  PT
 SG_ OBDFirstConfDTCWarmCyc_BMS02 m28 : 47|6@0+ (1,0) [0|63] ""  PT
 SG_ OBDPermanentDTCCount_BMS02 m28 : 23|8@0+ (1,0) [0|255] ""  PT
 SG_ OBDFirstPermanentDTC_BMS02 m28 : 39|8@0+ (1,0) [0|255] ""  PT
 SG_ OBDFirstPermDTCDriveCyc_BMS02 m28 : 41|2@0+ (1,0) [0|3] ""  PT
 SG_ nmStartupReason_BMS02 m16 : 15|4@0+ (1,0) [0|0] ""  PT
 SG_ SOCdynamicRecal_BMS02 m10 : 19|1@0+ (1,0) [0|1] ""  PT
 SG_ SOCuserSOCInit_BMS02 m10 : 18|1@0+ (1,0) [0|1] ""  PT
 SG_ contactorType_BMS02 m25 : 11|4@0+ (1,0) [0|0] ""  PT
 SG_ activeIsoTestDuration_BMS02 m13 : 15|8@0+ (200,0) [0|51000] "ms"  PT
 SG_ balancingState_BMS02 m16 : 11|4@0+ (1,0) [0|0] ""  PT
 SG_ storCondSysNwOk_BMS02 m27 : 25|1@0+ (1,0) [0|0] ""  PT
 SG_ storCondSysPwrOk_BMS02 m27 : 26|1@0+ (1,0) [0|0] ""  PT
 SG_ storCondECUOk_BMS02 m27 : 24|1@0+ (1,0) [0|0] ""  PT
 SG_ chronoStackWrCnt_BMS02 m27 : 39|32@0+ (1,0) [0|0] ""  PT
 SG_ wakeReason_BMS02 m10 : 15|4@0+ (1,0) [0|0] ""  PT
 SG_ cntrUnderLoadOpenCntr7_BMS02 m26 : 63|8@0+ (1,0) [0|0] ""  PT
 SG_ cntrUnderLoadOpenCntr6_BMS02 m26 : 55|8@0+ (1,0) [0|0] ""  PT
 SG_ cntrUnderLoadOpenCntr5_BMS02 m26 : 47|8@0+ (1,0) [0|0] ""  PT
 SG_ cntrUnderLoadOpenCntr4_BMS02 m26 : 39|8@0+ (1,0) [0|0] ""  PT
 SG_ cntrUnderLoadOpenCntr3_BMS02 m26 : 31|8@0+ (1,0) [0|0] ""  PT
 SG_ cntrUnderLoadOpenCntr2_BMS02 m26 : 23|8@0+ (1,0) [0|0] ""  PT
 SG_ cntrUnderLoadOpenCntr1_BMS02 m26 : 15|8@0+ (1,0) [0|0] ""  PT
 SG_ coolantOutletTemperature_BMS02 m27 : 23|8@0+ (1,-40) [-40|215] "C"  PT
 SG_ coolantInletTemperature_BMS02 m27 : 15|8@0+ (1,-40) [-40|215] "C"  PT
 SG_ prchgResHeatModel_BMS02 m3 : 55|16@0+ (0.1,0) [0|0] "Ws"  PT
 SG_ variantCodingCount_BMS02 m7 : 15|8@0+ (1,0) [0|0] ""  PT
 SG_ SWVersionCusApp_BMS02 m7 : 39|32@0+ (1,0) [0|0] ""  PT
 SG_ contactorOpenRequest_BMS02 m25 : 15|4@0+ (1,0) [0|0] ""  PT
 SG_ maxBrickVoltageChargeLimit_BMS02 m25 : 23|16@0+ (0.0001,0) [0|6.5] "V"  PT
 SG_ desiccantTimer_BMS02 m25 : 39|32@0+ (1,0) [0|0] "s"  PT
 SG_ batSwitchOpenReason_BMS02 m4 : 55|16@0+ (1,0) [0|0] ""  PT
 SG_ balancingTime_BMS02 m24 : 55|16@0+ (1,0) [0|65535] ""  PT
 SG_ bmsIsESSMaster_BMS02 m6 : 14|1@0+ (1,0) [0|0] ""  PT
 SG_ ecuSerialNrChar01_BMS02 m12 : 23|8@0+ (1,0) [0|0] ""  PT
 SG_ ecuSerialNrChar02_BMS02 m12 : 31|8@0+ (1,0) [0|0] ""  PT
 SG_ ecuSerialNrChar03_BMS02 m12 : 39|8@0+ (1,0) [0|0] ""  PT
 SG_ ecuSerialNrChar04_BMS02 m12 : 47|8@0+ (1,0) [0|0] ""  PT
 SG_ ecuSerialNrChar16_BMS02 m13 : 23|8@0+ (1,0) [0|0] ""  PT
 SG_ ecuSerialNrChar17_BMS02 m13 : 31|8@0+ (1,0) [0|0] ""  PT
 SG_ ecuSerialNrChar18_BMS02 m13 : 39|8@0+ (1,0) [0|0] ""  PT
 SG_ ecuSerialNrChar19_BMS02 m13 : 47|8@0+ (1,0) [0|0] ""  PT
 SG_ maxModuleTemperature_BMS02 m5 : 63|8@0+ (1,-40) [-40|200] "C"  PT
 SG_ meanModuleTemperature_BMS02 m8 : 15|8@0+ (1,-40) [-40|200] "C"  PT
 SG_ minModuleTemperature_BMS02 m5 : 55|8@0+ (1,-40) [-40|200] "C"  PT
 SG_ currentEventsShrt_BMS02 m6 : 15|1@0+ (1,0) [0|0] ""  PT
 SG_ nmOperationalMode_BMS02 m1 : 13|2@0+ (1,0) [0|0] ""  PT
 SG_ nmNetworkMode_BMS02 m1 : 15|2@0+ (1,0) [0|0] ""  PT
 SG_ nmNetworkState_BMS02 m1 : 11|1@0+ (1,0) [0|0] ""  PT
 SG_ ecuState_BMS02 m1 : 10|3@0+ (1,0) [0|7] ""  PT
 SG_ SPIRxTxDiag_BMS02 m10 : 11|4@0+ (2,0) [0|30] ""  PT
 SG_ minSOC_BMS02 m24 : 23|16@0+ (0.01,0) [0|100] "PCT"  PT
 SG_ maxSOC_BMS02 m24 : 39|16@0+ (0.01,0) [0|100] "PCT"  PT
 SG_ appTaskMaxCpuUsage_BMS02 m23 : 63|8@0+ (0.5,0) [0|100] "PCT"  PT
 SG_ appTaskCpuUsage_BMS02 m23 : 55|8@0+ (0.5,0) [0|100] "PCT"  PT
 SG_ appTask50HzCpuUsage_BMS02 m23 : 47|8@0+ (0.5,0) [0|100] "PCT"  PT
 SG_ appTask10HzStackUsage_BMS02 m23 : 39|8@0+ (0.5,0) [0|100] "PCT"  PT
 SG_ appTask100HzCpuUsage_BMS02 m23 : 31|8@0+ (0.5,0) [0|100] "PCT"  PT
 SG_ appTask10HzCpuUsage_BMS02 m23 : 23|8@0+ (0.5,0) [0|100] "PCT"  PT
 SG_ appTask1HzCpuUsage_BMS02 m23 : 15|8@0+ (0.5,0) [0|100] "PCT"  PT
 SG_ pumpSpeedReq_BMS02 m12 : 15|8@0+ (1,0) [0|0] "PCT"  PT
 SG_ numberOfStrings_BMS02 m4 : 15|5@0+ (1,0) [0|0] ""  PT
 SG_ hvComponentOpLimit_BMS02 m22 : 23|16@0+ (0.05,0) [0|3276.75] "A"  PT
 SG_ regenCurrPredBrickVOffset_BMS02 m5 : 15|8@0+ (0.5,0) [0|127.5] "A"  PT
 SG_ dischgCurrPredBrickVOffset_BMS02 m3 : 15|8@0+ (0.5,0) [0|127.5] "A"  PT
 SG_ PCANBusOffState_BMS02 m6 : 11|2@0+ (1,0) [0|0] ""  PT
 SG_ SCANBusOffState_BMS02 m6 : 13|2@0+ (1,0) [0|0] ""  PT
 SG_ PTCANBusOffState_BMS02 m6 : 9|2@0+ (1,0) [0|0] ""  PT
 SG_ eepromWriteCyclesSoc_BMS02 m11 : 39|8@0+ (1,0) [0|0] ""  PT
 SG_ eepromWriteCyclesDiag_BMS02 m11 : 31|8@0+ (1,0) [0|0] ""  PT
 SG_ eepromWriteCyclesChrono_BMS02 m10 : 39|8@0+ (1,0) [0|0] ""  PT
 SG_ eepromWriteCyclesCust_BMS02 m10 : 47|8@0+ (1,0) [0|0] ""  PT
 SG_ customerModelVsYear_BMS02 m14 : 23|8@0+ (1,0) [0|0] ""  PT
 SG_ customerModelVsWeek_BMS02 m14 : 31|8@0+ (1,0) [0|0] ""  PT
 SG_ customerModelVsCellType_BMS02 m14 : 15|1@0+ (1,0) [0|0] ""  PT
 SG_ customerModelVsCellGen_BMS02 m14 : 14|7@0+ (1,0) [0|0] ""  PT
 SG_ SWVersion_BMS02 m14 : 39|32@0+ (1,0) [0|4294967295] ""  PT
 SG_ balancingRequest288_to_295_BMS02 m21 : 63|8@0+ (1,0) [0|0] ""  PT
 SG_ balancingRequest296_to_303_BMS02 m21 : 55|8@0+ (1,0) [0|0] ""  PT
 SG_ balancingRequest304_to_311_BMS02 m21 : 47|8@0+ (1,0) [0|0] ""  PT
 SG_ balancingRequest312_to_319_BMS02 m21 : 39|8@0+ (1,0) [0|0] ""  PT
 SG_ balancingRequest320_to_327_BMS02 m21 : 31|8@0+ (1,0) [0|0] ""  PT
 SG_ balancingRequest328_to_335_BMS02 m21 : 23|8@0+ (1,0) [0|0] ""  PT
 SG_ balancingRequest240_to_247_BMS02 m20 : 63|8@0+ (1,0) [0|0] ""  PT
 SG_ balancingRequest248_to_255_BMS02 m20 : 55|8@0+ (1,0) [0|0] ""  PT
 SG_ balancingRequest256_to_263_BMS02 m20 : 47|8@0+ (1,0) [0|0] ""  PT
 SG_ balancingRequest264_to_271_BMS02 m20 : 39|8@0+ (1,0) [0|0] ""  PT
 SG_ balancingRequest272_to_279_BMS02 m20 : 31|8@0+ (1,0) [0|0] ""  PT
 SG_ balancingRequest280_to_287_BMS02 m20 : 23|8@0+ (1,0) [0|0] ""  PT
 SG_ balancingRequest192_to_199_BMS02 m19 : 63|8@0+ (1,0) [0|0] ""  PT
 SG_ balancingRequest200_to_207_BMS02 m19 : 55|8@0+ (1,0) [0|0] ""  PT
 SG_ balancingRequest208_to_215_BMS02 m19 : 47|8@0+ (1,0) [0|0] ""  PT
 SG_ balancingRequest216_to_223_BMS02 m19 : 39|8@0+ (1,0) [0|0] ""  PT
 SG_ balancingRequest224_to_231_BMS02 m19 : 31|8@0+ (1,0) [0|0] ""  PT
 SG_ balancingRequest232_to_239_BMS02 m19 : 23|8@0+ (1,0) [0|0] ""  PT
 SG_ balancingRequest144_to_151_BMS02 m18 : 63|8@0+ (1,0) [0|0] ""  PT
 SG_ balancingRequest152_to_159_BMS02 m18 : 55|8@0+ (1,0) [0|0] ""  PT
 SG_ balancingRequest160_to_167_BMS02 m18 : 47|8@0+ (1,0) [0|0] ""  PT
 SG_ balancingRequest168_to_175_BMS02 m18 : 39|8@0+ (1,0) [0|0] ""  PT
 SG_ balancingRequest176_to_183_BMS02 m18 : 31|8@0+ (1,0) [0|0] ""  PT
 SG_ balancingRequest184_to_191_BMS02 m18 : 23|8@0+ (1,0) [0|0] ""  PT
 SG_ balancingRequest096_to_103_BMS02 m17 : 63|8@0+ (1,0) [0|0] ""  PT
 SG_ balancingRequest104_to_111_BMS02 m17 : 55|8@0+ (1,0) [0|0] ""  PT
 SG_ balancingRequest112_to_119_BMS02 m17 : 47|8@0+ (1,0) [0|0] ""  PT
 SG_ balancingRequest120_to_127_BMS02 m17 : 39|8@0+ (1,0) [0|0] ""  PT
 SG_ balancingRequest128_to_135_BMS02 m17 : 31|8@0+ (1,0) [0|0] ""  PT
 SG_ balancingRequest136_to_143_BMS02 m17 : 23|8@0+ (1,0) [0|0] ""  PT
 SG_ balancingRequest048_to_055_BMS02 m16 : 63|8@0+ (1,0) [0|0] ""  PT
 SG_ balancingRequest056_to_063_BMS02 m16 : 55|8@0+ (1,0) [0|0] ""  PT
 SG_ balancingRequest064_to_071_BMS02 m16 : 47|8@0+ (1,0) [0|0] ""  PT
 SG_ balancingRequest072_to_079_BMS02 m16 : 39|8@0+ (1,0) [0|0] ""  PT
 SG_ balancingRequest080_to_087_BMS02 m16 : 31|8@0+ (1,0) [0|0] ""  PT
 SG_ balancingRequest088_to_095_BMS02 m16 : 23|8@0+ (1,0) [0|0] ""  PT
 SG_ balancingRequest000_to_007_BMS02 m15 : 63|8@0+ (1,0) [0|0] ""  PT
 SG_ balancingRequest008_to_015_BMS02 m15 : 55|8@0+ (1,0) [0|0] ""  PT
 SG_ balancingRequest016_to_023_BMS02 m15 : 47|8@0+ (1,0) [0|0] ""  PT
 SG_ balancingRequest024_to_031_BMS02 m15 : 39|8@0+ (1,0) [0|0] ""  PT
 SG_ balancingRequest032_to_039_BMS02 m15 : 31|8@0+ (1,0) [0|0] ""  PT
 SG_ balancingRequest040_to_047_BMS02 m15 : 23|8@0+ (1,0) [0|0] ""  PT
 SG_ balancingVoltageTarget_BMS02 m15 : 15|8@0+ (0.02,0) [0|5.1] ""  PT
 SG_ numberOfPacksPerString_BMS02 m4 : 10|3@0+ (1,0) [0|0] ""  PT
 SG_ analogAddr5_BMS02 m1 : 23|8@0+ (0.05,0) [0|12] "V"  PT
 SG_ analogAddr0_BMS02 m1 : 63|8@0+ (0.05,0) [0|12] "V"  PT
 SG_ analogAddr4_BMS02 m1 : 31|8@0+ (0.05,0) [0|12] "V"  PT
 SG_ analogAddr3_BMS02 m1 : 39|8@0+ (0.05,0) [0|12] "V"  PT
 SG_ analogAddr2_BMS02 m1 : 47|8@0+ (0.05,0) [0|12] "V"  PT
 SG_ analogAddr1_BMS02 m1 : 55|8@0+ (0.05,0) [0|12] "V"  PT
 SG_ debugSlowMpex1_BMS02 M : 7|8@0+ (1,0) [0|0] ""  PT
 SG_ analog3V3DSupply_BMS02 m9 : 15|8@0+ (0.015,0) [0|0] "V"  PT
 SG_ pressure_BMS02 m9 : 63|8@0+ (0.4,0) [0|19] "psi"  PT
 SG_ analog3P3VA_BMS02 m9 : 55|8@0+ (0.015,0) [0|3.825] "V"  PT
 SG_ analog5VA_BMS02 m9 : 31|8@0+ (0.025,0) [0|6] "V"  PT
 SG_ analog5VD_BMS02 m9 : 23|8@0+ (0.025,0) [0|6] "V"  PT
 SG_ analog5VSensorSupply_BMS02 m9 : 47|8@0+ (0.025,0) [0|6.375] "V"  PT
 SG_ analog6V5_BMS02 m9 : 39|8@0+ (0.0075,5) [5|6.9125] "V"  PT
 SG_ isolationResistanceIntern_BMS02 m8 : 55|16@0+ (2,0) [0|130000] "kOhm"  PT
 SG_ isolationResistanceExtern_BMS02 m8 : 39|16@0+ (2,0) [0|130000] "kOhm"  PT
 SG_ linkVoltage_BMS02 m8 : 23|16@0+ (0.02,0) [0|1310.7] "V"  PT
 SG_ eepromWriteCyclesBasics_BMS02 m11 : 23|8@0+ (1,0) [0|0] ""  PT
 SG_ eepromBlockIndex_BMS02 m11 : 15|8@0+ (1,0) [0|0] ""  PT
 SG_ CAN1MIATimerISR_BMS02 m7 : 23|8@0+ (1,0) [0|255] ""  PT
 SG_ CAN2MIATimerISR_BMS02 m7 : 31|8@0+ (1,0) [0|255] ""  PT
 SG_ regenCurrentOpLimit_BMS02 m5 : 39|16@0+ (0.05,0) [0|3200] "A"  PT
 SG_ regenCurrentErrorLimit_BMS02 m5 : 23|16@0+ (0.05,0) [0|3200] "A"  PT
 SG_ lifetime_BMS02 m6 : 39|32@0+ (1,0) [0|0] "s"  PT
 SG_ eepromReadTime_BMS02 m0 : 15|8@0+ (10,0) [0|2550] "ms"  PT
 SG_ chargerCurrentOpLimit_BMS02 m4 : 39|16@0+ (0.05,0) [0|3200] "A"  PT
 SG_ dischargeCurrentOpLimit_BMS02 m3 : 39|16@0+ (0.05,-3200) [-3200|0] "A"  PT
 SG_ chargerCurrentErrorLimit_BMS02 m4 : 23|16@0+ (0.05,0) [0|3200] "A"  PT
 SG_ dischargeCurrentErrorLimit_BMS02 m3 : 23|16@0+ (0.05,-3200) [-3200|0] "A"  PT
 SG_ pumpSpeedReqMaxT_BMS02 m2 : 23|8@0+ (1,0) [0|0] "PCT"  PT
 SG_ pumpSpeedReqDeltaT_BMS02 m2 : 31|8@0+ (1,0) [0|0] "PCT"  PT
 SG_ energyThroughput_BMS02 m2 : 39|32@0+ (0.001,0) [0|4294967.295] "kWh"  PT
 SG_ packVoltageCMB_BMS02 m6 : 23|16@0+ (0.02,0) [0|1200] "V"  PT
 SG_ ctrOffTimeLast_BMS02 m0 : 23|16@0+ (1,0) [0|0] "s"  PT
 SG_ ctrOffTime_BMS02 m0 : 39|16@0+ (1,0) [0|0] "s"  PT
 SG_ sleepTime_BMS02 m0 : 55|16@0+ (1,0) [0|0] "s"  PT
 SG_ SPIRxTxTimeAllPckts_BMS02 m10 : 31|8@0+ (2,0) [0|500] "ms"  PT
 SG_ isolationTestState_BMS02 m10 : 17|2@0+ (1,0) [0|0] ""  PT
 SG_ SOCvoltageInit_BMS02 m10 : 21|1@0+ (1,0) [0|1] ""  PT
 SG_ SOCocvInit_BMS02 m10 : 23|1@0+ (1,0) [0|1] ""  PT
 SG_ SOCeepromInit_BMS02 m10 : 22|1@0+ (1,0) [0|1] ""  PT
 SG_ SOCdefaultInit_BMS02 m10 : 20|1@0+ (1,0) [0|1] ""  PT

BO_ 1729 BMS02_DebugFastMpex1: 8 BMS02
 SG_ SPIRxTxHeaderMux3Status_BMS02 m1 : 23|1@0+ (1,0) [0|1] ""  PT
 SG_ SPIRxTxHeaderMux2Status_BMS02 m1 : 22|1@0+ (1,0) [0|1] ""  PT
 SG_ SPIRxTxHeaderMux1Status_BMS02 m1 : 21|1@0+ (1,0) [0|1] ""  PT
 SG_ SPIRxTxHeaderMux0Status_BMS02 m1 : 20|1@0+ (1,0) [0|1] ""  PT
 SG_ activeIsoTestPsbl_BMS02 m0 : 27|1@0+ (1,0) [0|0] ""  PT
 SG_ activeIsoState_BMS02 m3 : 15|8@0+ (1,0) [0|0] ""  PT
 SG_ activeIsoNegLink_BMS02 m3 : 39|16@0+ (0.04,-1250) [-1250|1371.4] "V"  PT
 SG_ activeIsoPosLink_BMS02 m3 : 23|16@0+ (0.04,-1250) [-1250|1371.4] "V"  PT
 SG_ activeIsoTestStateTimer_BMS02 m2 : 15|8@0+ (200,0) [0|51000] "ms"  PT
 SG_ activeIsoPosBuffer_BMS02 m2 : 23|16@0+ (0.04,-1250) [-1250|1371.4] "V"  PT
 SG_ activeIsoNegBuffer_BMS02 m2 : 39|16@0+ (0.04,-1250) [-1250|1371.4] "V"  PT
 SG_ activeIsoResRaw_BMS02 m2 : 55|16@0+ (2,0) [0|130000] "kOhm"  PT
 SG_ activeIsoResFilter_BMS02 m3 : 55|16@0+ (2,0) [0|130000] "kOhm"  PT
 SG_ contactorStateAux_BMS02 m1 : 34|3@0+ (1,0) [0|0] ""  PT
 SG_ batSwitchOpenReqEssMstr_BMS02 m0 : 35|2@0+ (1,0) [0|0] ""  PT
 SG_ packShutdownTarget_BMS02 m1 : 12|2@0+ (1,0) [0|0] ""  PT
 SG_ weldedState_BMS02 m1 : 39|2@0+ (1,0) [0|0] ""  PT
 SG_ DIGIO_GPIO2_ON_BMS02 m1 : 19|1@0+ (1,0) [0|0] ""  PT
 SG_ DIGIO_GPIO1_ON_BMS02 m1 : 18|1@0+ (1,0) [0|0] ""  PT
 SG_ DIGIO_12VCURR_SENSE_ON_BMS02 m1 : 37|1@0+ (1,0) [0|0] ""  PT
 SG_ DIGIO_PSUP_SAFETY_OK_BMS02 m1 : 17|1@0+ (1,0) [0|0] ""  PT
 SG_ contactorStateRq_BMS02 m1 : 36|2@0+ (1,0) [0|0] ""  PT
 SG_ contactorPwrOkToPrechg_BMS02 m1 : 16|1@0+ (1,0) [0|0] ""  PT
 SG_ strMstrStrPrechgState_BMS02 m1 : 58|3@0+ (1,0) [0|0] ""  PT
 SG_ packShutdwnTmrQual_BMS02 m1 : 27|1@0+ (1,0) [0|0] ""  PT
 SG_ packStateRequest_BMS02 m1 : 15|3@0+ (1,0) [0|0] ""  PT
 SG_ packState_BMS02 m1 : 31|4@0+ (1,0) [0|0] ""  PT
 SG_ SPIRxTxTimer_BMS02 m1 : 47|8@0+ (2,0) [0|500] "ms"  PT
 SG_ moduleTMinMaxMeanQual_BMS02 m1 : 26|1@0+ (1,0) [0|0] ""  PT
 SG_ currentQual_BMS02 m1 : 25|1@0+ (1,0) [0|0] ""  PT
 SG_ brickVMinMaxMeanQual_BMS02 m1 : 24|1@0+ (1,0) [0|0] ""  PT
 SG_ negCtr1OnReqASW_BMS02 m1 : 8|1@0+ (1,0) [0|0] ""  PT
 SG_ prechgCtr1OnReqASW_BMS02 m1 : 9|1@0+ (1,0) [0|0] ""  PT
 SG_ posCtr1OnReqASW_BMS02 m1 : 10|1@0+ (1,0) [0|0] ""  PT
 SG_ DIGIO_CNTR_HISIDE_ON_MC_BMS02 m0 : 38|1@0+ (1,0) [0|0] ""  PT
 SG_ DIGIO_CNTR_HISIDE_ON_CHCKD_BMS02 m0 : 37|1@0+ (1,0) [0|0] ""  PT
 SG_ DIGIO_CNTR_CLOSE_OK_CHCKD_BMS02 m0 : 36|1@0+ (1,0) [0|0] ""  PT
 SG_ debugFastMpex1_BMS02 M : 7|8@0+ (1,0) [0|0] ""  PT
 SG_ stateContactorControl_BMS02 m0 : 41|1@0+ (1,0) [0|0] ""  PT
 SG_ stateVoltage_BMS02 m0 : 43|1@0+ (1,0) [0|0] ""  PT
 SG_ stateTemperature_BMS02 m0 : 44|1@0+ (1,0) [0|0] ""  PT
 SG_ stateSelfTest_BMS02 m0 : 45|1@0+ (1,0) [0|0] ""  PT
 SG_ stateHVIL_BMS02 m0 : 46|1@0+ (1,0) [0|0] ""  PT
 SG_ stateCurrent_BMS02 m0 : 47|1@0+ (1,0) [0|0] ""  PT
 SG_ stateCrash_BMS02 m0 : 42|1@0+ (1,0) [0|0] ""  PT
 SG_ stateContactors_BMS02 m0 : 40|1@0+ (1,0) [0|0] ""  PT
 SG_ stateCANRx_BMS02 m0 : 39|1@0+ (1,0) [0|0] ""  PT
 SG_ itemState_BMS02 m0 : 33|2@0+ (1,0) [0|0] ""  PT
 SG_ negLink_BMS02 m0 : 23|8@0+ (10,-1200) [-1200|1350] "V"  PT
 SG_ posLink_BMS02 m0 : 15|8@0+ (10,-1200) [-1200|1350] "V"  PT
 SG_ negPack_BMS02 m0 : 63|8@0+ (10,-1200) [-1200|1350] "V"  PT
 SG_ posPack_BMS02 m0 : 55|8@0+ (10,-1200) [-1200|1350] "V"  PT
 SG_ prechargeState_BMS02 m0 : 31|4@0+ (1,0) [0|0] ""  PT
 SG_ contactorState_BMS02 m0 : 26|3@0+ (1,0) [0|0] ""  PT
 SG_ diagStandbyImmShutdown_BMS02 m1 : 61|1@0+ (1,0) [0|1] ""  PT
 SG_ diagAllOffRequired_BMS02 m1 : 60|1@0+ (1,0) [0|1] ""  PT
 SG_ diagDriveTransitionNotOK_BMS02 m1 : 55|1@0+ (1,0) [0|1] ""  PT
 SG_ diagDriveImmShutdown_BMS02 m1 : 54|1@0+ (1,0) [0|1] ""  PT
 SG_ diagDriveDelShutdown2_BMS02 m1 : 52|1@0+ (1,0) [0|1] ""  PT
 SG_ diagDriveDelShutdown1_BMS02 m1 : 53|1@0+ (1,0) [0|1] ""  PT
 SG_ diagUnused_BMS02 m1 : 59|1@0+ (1,0) [0|1] ""  PT
 SG_ diagChargeTransitionNotOK_BMS02 m1 : 51|1@0+ (1,0) [0|1] ""  PT
 SG_ diagChargeImmShutdown_BMS02 m1 : 50|1@0+ (1,0) [0|1] ""  PT
 SG_ diagAccDelShutdown1_BMS02 m1 : 62|1@0+ (1,0) [0|1] ""  PT
 SG_ diagChargeDelShutdown1_BMS02 m1 : 49|1@0+ (1,0) [0|1] ""  PT
 SG_ diagAccTransitionNotOK_BMS02 m1 : 48|1@0+ (1,0) [0|1] ""  PT
 SG_ diagAccImmShutdown_BMS02 m1 : 63|1@0+ (1,0) [0|1] ""  PT

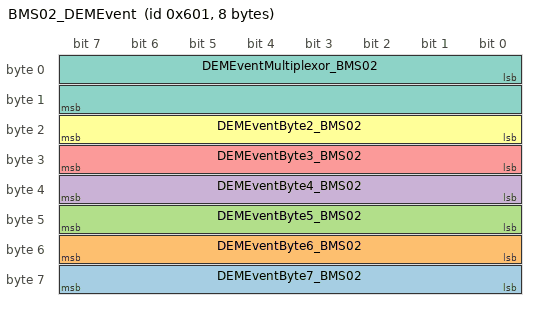
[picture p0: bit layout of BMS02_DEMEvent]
BO_ 1537 BMS02_DEMEvent: 8 BMS02
 SG_ DEMEventByte7_BMS02 : 63|8@0+ (1,0) [0|0] ""  PT
 SG_ DEMEventByte6_BMS02 : 55|8@0+ (1,0) [0|0] ""  PT
 SG_ DEMEventByte5_BMS02 : 47|8@0+ (1,0) [0|0] ""  PT
 SG_ DEMEventByte4_BMS02 : 39|8@0+ (1,0) [0|0] ""  PT
 SG_ DEMEventByte3_BMS02 : 31|8@0+ (1,0) [0|0] ""  PT
 SG_ DEMEventByte2_BMS02 : 23|8@0+ (1,0) [0|0] ""  PT
 SG_ DEMEventMultiplexor_BMS02 M : 0|16@1+ (1,0) [0|0] ""  PT

BO_ 1025 BMS02_DebugEventMap1: 8 BMS02
 SG_ DEM001_POWERUP_BMS02 : 11|2@0+ (1,0) [0|0] ""  PT
 SG_ DEM002_VOLTAGE_BRICK_OV_BMS02 : 13|2@0+ (1,0) [0|0] ""  PT
 SG_ DEM003_VOLTAGE_BRICK_UV_BMS02 : 15|2@0+ (1,0) [0|0] ""  PT
 SG_ DEM004_VOLTAGE_BRICK_SNA_BMS02 : 1|2@0+ (1,0) [0|0] ""  PT
 SG_ DEM005_VOLTAGE_BRICK_IMBAL_BMS02 : 3|2@0+ (1,0) [0|0] ""  PT
 SG_ DEM006_VOLTAGE_CAPCY_IMBAL_BMS02 : 5|2@0+ (1,0) [0|0] ""  PT
 SG_ DEM007_MODULET_HIGH_DELTA_BMS02 : 7|2@0+ (1,0) [0|0] ""  PT
 SG_ DEM008_VOLTAGE_PACK_UV_BMS02 : 25|2@0+ (1,0) [0|0] ""  PT
 SG_ DEM009_VOLTAGE_PACK_OV_BMS02 : 27|2@0+ (1,0) [0|0] ""  PT
 SG_ DEM010_VOLTAGE_PACK_PLAUSI_BMS02 : 29|2@0+ (1,0) [0|0] ""  PT
 SG_ DEM011_VOLTAGE_PCKLINK_MIS_BMS02 : 31|2@0+ (1,0) [0|0] ""  PT
 SG_ DEM012_VOLTAGE_BMS_SUPPLY_BMS02 : 17|2@0+ (1,0) [0|0] ""  PT
 SG_ DEM013_ADC_ERROR_BMS02 : 19|2@0+ (1,0) [0|0] ""  PT
 SG_ DEM014_MODULET_OT_BMS02 : 21|2@0+ (1,0) [0|0] ""  PT
 SG_ DEM015_MODULET_SNA_BMS02 : 23|2@0+ (1,0) [0|0] ""  PT
 SG_ DEM016_MODULET_LIMPHOME_BMS02 : 41|2@0+ (1,0) [0|0] ""  PT
 SG_ DEM017_COOLING_SYS_LHOME_BMS02 : 43|2@0+ (1,0) [0|0] ""  PT
 SG_ DEM018_HVIL_LIMPHOME_BMS02 : 45|2@0+ (1,0) [0|0] ""  PT
 SG_ DEM019_HVIL_ESS_INHIBIT_BMS02 : 47|2@0+ (1,0) [0|0] ""  PT
 SG_ DEM020_MODULET_CHANGE_BMS02 : 33|2@0+ (1,0) [0|0] ""  PT
 SG_ DEM021_LG_MAVD_FAULT_BMS02 : 35|2@0+ (1,0) [0|0] ""  PT
 SG_ DEM022_LG_RDV_FAULT_BMS02 : 37|2@0+ (1,0) [0|0] ""  PT
 SG_ DEM023_BMS_ONBOARDT_SNA_BMS02 : 39|2@0+ (1,0) [0|0] ""  PT
 SG_ DEM024_BMS_ONBOARDRH_OH_BMS02 : 57|2@0+ (1,0) [0|0] ""  PT
 SG_ DEM025_BMS_ONBOARDRH_SNA_BMS02 : 59|2@0+ (1,0) [0|0] ""  PT
 SG_ DEM026_CURRENT_OVERCHARGE_BMS02 : 61|2@0+ (1,0) [0|0] ""  PT
 SG_ DEM027_CURRENT_OVERDISCHGE_BMS02 : 63|2@0+ (1,0) [0|0] ""  PT
 SG_ DEM028_CURRENT_INVALID_BMS02 : 49|2@0+ (1,0) [0|0] ""  PT
 SG_ DEM029_CURRENT_SHORTCIRCT_BMS02 : 51|2@0+ (1,0) [0|0] ""  PT
 SG_ DEM030_CRASH_CAN_LATCH_BMS02 : 53|2@0+ (1,0) [0|0] ""  PT
 SG_ DEM031_EEPROM_FAIL_BMS02 : 55|2@0+ (1,0) [0|0] ""  PT

BO_ 1089 BMS02_DebugEventMap2: 8 BMS02
 SG_ DEM032_PCHG_PACKS_CONNECT_BMS02 : 9|2@0+ (1,0) [0|0] ""  PT
 SG_ DEM033_PCHG_ILLEGAL_PRCHG_BMS02 : 11|2@0+ (1,0) [0|0] ""  PT
 SG_ DEM034_PCHG_RELAY_FAIL_BMS02 : 13|2@0+ (1,0) [0|0] ""  PT
 SG_ DEM035_PCHG_NEG_WELD_BMS02 : 15|2@0+ (1,0) [0|0] ""  PT
 SG_ DEM036_PCHG_NEG_PULLIN_BMS02 : 1|2@0+ (1,0) [0|0] ""  PT
 SG_ DEM037_PCHG_SHORTCIRCUIT_BMS02 : 3|2@0+ (1,0) [0|0] ""  PT
 SG_ DEM038_PCHG_OPENCIRCUIT_BMS02 : 5|2@0+ (1,0) [0|0] ""  PT
 SG_ DEM039_PCHG_TIMEOUT_BMS02 : 7|2@0+ (1,0) [0|0] ""  PT
 SG_ DEM040_PCHG_FAILED_BMS02 : 25|2@0+ (1,0) [0|0] ""  PT
 SG_ DEM041_HVIL_SHUTDOWN_BMS02 : 27|2@0+ (1,0) [0|0] ""  PT
 SG_ DEM042_PCHG_POS_WELD_BMS02 : 29|2@0+ (1,0) [0|0] ""  PT
 SG_ DEM043_HV_LOCK_TRANSPORT_BMS02 : 31|2@0+ (1,0) [0|0] ""  PT
 SG_ DEM044_CTRS_END_OF_LIFE_BMS02 : 17|2@0+ (1,0) [0|0] ""  PT
 SG_ DEM045_CTRS_CTRPWRV_HI_BMS02 : 19|2@0+ (1,0) [0|0] ""  PT
 SG_ DEM046_CTRS_COILCURR_LOW_BMS02 : 21|2@0+ (1,0) [0|0] ""  PT
 SG_ DEM047_CTRS_COILCURR_HIGH_BMS02 : 23|2@0+ (1,0) [0|0] ""  PT
 SG_ DEM048_CTRS_CTRPWRV_LOW_BMS02 : 41|2@0+ (1,0) [0|0] ""  PT
 SG_ DEM049_CHGE_ILLEGAL_DISCHG_BMS02 : 43|2@0+ (1,0) [0|0] ""  PT
 SG_ DEM050_STARTUP_CONDITIONS_BMS02 : 45|2@0+ (1,0) [0|0] ""  PT
 SG_ DEM051_VOLTAGE_BMS_SUPPLYH_BMS02 : 47|2@0+ (1,0) [0|0] ""  PT
 SG_ DEM052_SAFETYSPI_FAIL_BMS02 : 33|2@0+ (1,0) [0|0] ""  PT
 SG_ DEM053_WATCHDOG_ERRORPIN_BMS02 : 35|2@0+ (1,0) [0|0] ""  PT
 SG_ DEM054_SAFESTATE_TRIGGERED_BMS02 : 37|2@0+ (1,0) [0|0] ""  PT
 SG_ DEM055_DEBUG_CMND_ACTIVE_BMS02 : 39|2@0+ (1,0) [0|0] ""  PT
 SG_ DEM056_CRASH_CAN_BMS02 : 57|2@0+ (1,0) [0|0] ""  PT
 SG_ DEM057_ISO_EXT_STRAT_4_BMS02 : 59|2@0+ (1,0) [0|0] ""  PT
 SG_ DEM058_ISO_EXT_RES_ERR_BMS02 : 61|2@0+ (1,0) [0|0] ""  PT
 SG_ DEM059_ISO_EXT_RES_WARN_BMS02 : 63|2@0+ (1,0) [0|0] ""  PT
 SG_ DEM060_ISO_INT_RES_ERR_BMS02 : 49|2@0+ (1,0) [0|0] ""  PT
 SG_ DEM061_ISO_INT_RES_WARN_BMS02 : 51|2@0+ (1,0) [0|0] ""  PT
 SG_ DEM062_EMERGENCY_OPERATION_BMS02 : 53|2@0+ (1,0) [0|0] ""  PT
 SG_ DEM063_ENDOFDRIVE_BMS02 : 55|2@0+ (1,0) [0|0] ""  PT

BO_ 1153 BMS02_DebugEventMap3: 8 BMS02
 SG_ DEM064_STRINGV_IMBALANCE_BMS02 : 9|2@0+ (1,0) [0|0] ""  PT
 SG_ DEM065_STRING_FAULT_BMS02 : 11|2@0+ (1,0) [0|0] ""  PT
 SG_ DEM066_ESS_FAULT_BMS02 : 13|2@0+ (1,0) [0|0] ""  PT
 SG_ DEM067_ISO_EXT_STRAT_3_BMS02 : 15|2@0+ (1,0) [0|0] ""  PT
 SG_ DEM068_MODULE_COUNT_INVALI_BMS02 : 1|2@0+ (1,0) [0|0] ""  PT
 SG_ DEM069_PT_MIA_BMS02 : 3|2@0+ (1,0) [0|0] ""  PT
 SG_ DEM070_BMSMIA_STRNGMSTR_01_BMS02 : 5|2@0+ (1,0) [0|0] ""  PT
 SG_ DEM071_BMSMIA_STRNGMSTR_05_BMS02 : 7|2@0+ (1,0) [0|0] ""  PT
 SG_ DEM072_BMSMIA_STRNGMSTR_09_BMS02 : 25|2@0+ (1,0) [0|0] ""  PT
 SG_ DEM073_BMSMIA_STRNGMSTR_13_BMS02 : 27|2@0+ (1,0) [0|0] ""  PT
 SG_ DEM074_BMSMIA_STRNGMSTR_17_BMS02 : 29|2@0+ (1,0) [0|0] ""  PT
 SG_ DEM075_BMSMIA_STRNGMSTR_21_BMS02 : 31|2@0+ (1,0) [0|0] ""  PT
 SG_ DEM076_BMSMIA_STRNGMSTR_25_BMS02 : 17|2@0+ (1,0) [0|0] ""  PT
 SG_ DEM077_BMSMIA_STRNGMSTR_29_BMS02 : 19|2@0+ (1,0) [0|0] ""  PT
 SG_ DEM078_BMSMIA_STRNGMSTR_33_BMS02 : 21|2@0+ (1,0) [0|0] ""  PT
 SG_ DEM079_BMSMIA_STRNGMSTR_37_BMS02 : 23|2@0+ (1,0) [0|0] ""  PT
 SG_ DEM080_BMSMIA_STRNGMSTR_41_BMS02 : 41|2@0+ (1,0) [0|0] ""  PT
 SG_ DEM081_BMSMIA_STRNGMSTR_45_BMS02 : 43|2@0+ (1,0) [0|0] ""  PT
 SG_ DEM082_BMSMIA_STRNGMSTR_49_BMS02 : 45|2@0+ (1,0) [0|0] ""  PT
 SG_ DEM083_BMSMIA_STRNGMSTR_53_BMS02 : 47|2@0+ (1,0) [0|0] ""  PT
 SG_ DEM084_BMSMIA_STRNGMSTR_57_BMS02 : 33|2@0+ (1,0) [0|0] ""  PT
 SG_ DEM085_BMSMIA_STRNGMSTR_61_BMS02 : 35|2@0+ (1,0) [0|0] ""  PT
 SG_ DEM086_ESSCURRENT_SHORT_BMS02 : 37|2@0+ (1,0) [0|0] ""  PT
 SG_ DEM087_PT_MIA_SHUTDOWN_BMS02 : 39|2@0+ (1,0) [0|0] ""  PT
 SG_ DEM088_OUTLET_NTC_HI_BMS02 : 57|2@0+ (1,0) [0|0] ""  PT
 SG_ DEM089_OUTLET_NTC_LO_BMS02 : 59|2@0+ (1,0) [0|0] ""  PT
 SG_ DEM090_BMSMIA_ESSMASTER_BMS02 : 61|2@0+ (1,0) [0|0] ""  PT
 SG_ DEM091_PCHG_RES_OVERHEAT_BMS02 : 63|2@0+ (1,0) [0|0] ""  PT
 SG_ DEM092_BMSMIA_STRNGSLAVE_0_BMS02 : 49|2@0+ (1,0) [0|0] ""  PT
 SG_ DEM093_BMSMIA_STRNGSLAVE_1_BMS02 : 51|2@0+ (1,0) [0|0] ""  PT
 SG_ DEM094_BMSMIA_STRNGSLAVE_2_BMS02 : 53|2@0+ (1,0) [0|0] ""  PT
 SG_ DEM095_BMSMIA_STRNGSLAVE_3_BMS02 : 55|2@0+ (1,0) [0|0] ""  PT

CM_ SG_ 1664 selfTestFaultCntrCtrl_SC01 "When the diagnostic bit DIAGNOSTICBIT_CCTRL_SELFTEST is being set, this signal provides the further information indicating which self test is being failed.";
CM_ SG_ 1664 cmbASICFault_SC01 "Signal indicates the fault inside the ASIC that would impact bothe brick voltages and module temperatures.";
CM_ SG_ 1664 DIGIO_GPIO1_ON_SC01 "Pin Status of GPIO 1 Pin of Safety Controller";
CM_ SG_ 1664 DIGIO_ZDW_LSD_EN_SC01 "Pin Status of Pin ZDW_LSD_EN";
CM_ SG_ 1664 cmbLastUpdateTime_SC01 "Total time in ms it look to go through one CMB communication task";
CM_ SG_ 1664 SPIRxTxTimeAllPckts_SC01 "Time for all packets in ms. Maximum of ECU cycle.";
BA_DEF_ SG_  "GenSigSendType" ENUM  "Cyclic","OnWrite","OnWriteWithRepetition","OnChange","OnChangeWithRepetition","IfActive","IfActiveWithRepetition","NoSigSendType";
BA_DEF_ BO_  "GenMsgCycleTime" INT 0 0;
BA_DEF_ BO_  "GenMsgSendType" ENUM  "Cyclic","not_used","not_used","not_used","not_used","Cyclic","not_used","IfActive","NoMsgSendType";
BA_DEF_DEF_  "GenSigSendType" "Cyclic";
BA_DEF_DEF_  "GenMsgCycleTime" 0;
BA_DEF_DEF_  "GenMsgSendType" "NoMsgSendType";
BA_ "GenMsgCycleTime" BO_ 1664 10;
BA_ "GenMsgCycleTime" BO_ 1920 100;
BA_ "GenMsgCycleTime" BO_ 1984 100;
BA_ "GenMsgCycleTime" BO_ 961 1000;
BA_ "GenMsgCycleTime" BO_ 1793 100;
BA_ "GenMsgCycleTime" BO_ 1857 1000;
BA_ "GenMsgCycleTime" BO_ 1729 100;
BA_ "GenMsgCycleTime" BO_ 1025 1000;
BA_ "GenMsgCycleTime" BO_ 1089 1000;
BA_ "GenMsgCycleTime" BO_ 1153 1000;
VAL_ 1664 selfTestFaultCntrCtrl_SC01 4 "CTRCTRL_SELFTEST_NONE" 3 "CTRCTRL_SELFTEST_4" 2 "CTRCTRL_SELFTEST_3" 1 "CTRCTRL_SELFTEST_2" 0 "CTRCTRL_SELFTEST_1" ;
VAL_ 1664 cmbASICFault_SC01 20 "CMBDRIVER_ASIC_UNEXPECTED_MODULE" 19 "CMBDRIVER_ASIC_PEC_DIAGN_READ" 18 "CMBDRIVER_ASIC_PEC_DIAGN_DATA" 17 "CMBDRIVER_ASIC_PEC_DIAGN_CMD" 16 "CMBDRIVER_ASIC_REDUNDANT_FILTER" 15 "CMBDRIVER_ASIC_REDUNDANT_ADC" 14 "CMB_ASIC_CLOCK_LF" 13 "CMB_ASIC_CHARGE_PUMP_LF" 12 "CMB_ASIC_MUX_CHECK_LF" 11 "CMB_ASIC_INTERNAL_SUP_LF" 10 "CMB_ASIC_MUX_COMP_FAIL" 9 "CMB_ASIC_CHARGE_PUMP_FAIL" 8 "CMB_ASIC_OPEN_WIRE_CURR_FAIL" 255 "CMB_ASIC_FAULT_NONE" 7 "CMB_ASIC_VREF3_FAIL" 6 "CMB_ASIC_VREF2_FAIL" 5 "CMB_ASIC_ITEMP_FAIL" 4 "CMB_ASIC_VD_FAIL" 3 "CMB_ASIC_VA_FAIL" 2 "CMB_ASIC_TESTMODE" 1 "CMB_ASIC_CLOCK_FAIL" 0 "CMB_ASIC_MUX_FAIL" ;
VAL_ 1664 mainUcExtIsoResistance_SC01 65535 "SNA" ;
VAL_ 1664 BMS_C38_AR2MsgFault_SC01 3 "MSG_MISSING" 2 "MSG_SEQ_CNT_FAULT" 1 "MSG_CRC_FAULT" 0 "MSG_VALID" ;
VAL_ 1664 stateCoolant_SC01 1 "SAFESTATE_UNSAFE" 0 "SAFESTATE_SAFE" ;
VAL_ 1664 stateThermalEvent_SC01 1 "SAFESTATE_UNSAFE" 0 "SAFESTATE_SAFE" ;
VAL_ 1664 stateCANTx_SC01 1 "SAFESTATE_UNSAFE" 0 "SAFESTATE_SAFE" ;
VAL_ 1664 mainUcCntrCtrlReq_SC01 3 "SAFETYCAN_CNTR_CTRL_SNA" 1 "SAFETYCAN_CNTR_CTRL_CLS" 0 "SAFETYCAN_CNTR_CTRL_OPEN" ;
VAL_ 1664 mainUcCntrWeldState_SC01 7 "SAFETYCAN_WELD_HV_ALL_ERR" 6 "SAFETYCAN_WELD_HV_PLUS_MINUS_ERR" 15 "SAFETYCAN_WELD_SNA" 5 "SAFETYCAN_WELD_PRE_HV_MINUS_ERR" 4 "SAFETYCAN_WELD_HV_MINUS_ERR" 3 "SAFETYCAN_WELD_PRE_HV_PLUS_ERR" 2 "SAFETYCAN_WELD_HV_PLUS_ERR" 1 "SAFETYCAN_WELD_PRE_ERR" 0 "SAFETYCAN_WELD_NO_ERR" ;
VAL_ 1664 safetyUcCntrState_SC01 2 "SAFETYCAN_CNTR_CLS" 3 "SAFETYCAN_CNTR_SNA" 1 "SAFETYCAN_CNTR_PRECHRG" 0 "SAFETYCAN_CNTR_OPEN" ;
VAL_ 1664 mainUcCntrState_SC01 2 "SAFETYCAN_CNTR_CLS" 3 "SAFETYCAN_CNTR_SNA" 1 "SAFETYCAN_CNTR_PRECHRG" 0 "SAFETYCAN_CNTR_OPEN" ;
VAL_ 1664 safetyCANMsg4Fault_SC01 6 "SAFETYCAN_E2E_CRC" 15 "SAFETYCAN_SNA" 5 "SAFETYCAN_SPI_FAIL" 4 "SAFETYCAN_MSG_MISSING" 3 "SAFETYCAN_MSG_CNT_MISMATCH" 2 "SAFETYCAN_ALIVE_CNT" 1 "SAFETYCAN_SPI_CRC" 0 "SAFETYCAN_GOOD" ;
VAL_ 1664 safetyCANMsg3Fault_SC01 6 "SAFETYCAN_E2E_CRC" 15 "SAFETYCAN_SNA" 5 "SAFETYCAN_SPI_FAIL" 4 "SAFETYCAN_MSG_MISSING" 3 "SAFETYCAN_MSG_CNT_MISMATCH" 2 "SAFETYCAN_ALIVE_CNT" 1 "SAFETYCAN_SPI_CRC" 0 "SAFETYCAN_GOOD" ;
VAL_ 1664 safetyCANMsg2Fault_SC01 6 "SAFETYCAN_E2E_CRC" 15 "SAFETYCAN_SNA" 5 "SAFETYCAN_SPI_FAIL" 4 "SAFETYCAN_MSG_MISSING" 3 "SAFETYCAN_MSG_CNT_MISMATCH" 2 "SAFETYCAN_ALIVE_CNT" 1 "SAFETYCAN_SPI_CRC" 0 "SAFETYCAN_GOOD" ;
VAL_ 1664 safetyCANMsg1Fault_SC01 6 "SAFETYCAN_E2E_CRC" 15 "SAFETYCAN_SNA" 5 "SAFETYCAN_SPI_FAIL" 4 "SAFETYCAN_MSG_MISSING" 3 "SAFETYCAN_MSG_CNT_MISMATCH" 2 "SAFETYCAN_ALIVE_CNT" 1 "SAFETYCAN_SPI_CRC" 0 "SAFETYCAN_GOOD" ;
VAL_ 1664 contactorCntrSelfTest_SC01 9 "CTRCTRL_CHKLOSIDE_OPEN_CIRC" 8 "CTRCTRL_FAILED" 7 "CTRCTRL_PASSED" 6 "CTRCTRL_CHKHISIDE_STUCK_OPEN" 5 "CTRCTRL_CHK_CLOSE_OK_CIRCUIT" 4 "CTRCTRL_CHKLOSIDE_CTRL_OK" 3 "CTRCTRL_CHKLOSIDE_STUCK_CLOSED" 2 "CTRCTRL_CHKHISIDE_STUCK_CLOSED" 1 "CTRCTRL_PENDING" 0 "CTRCTRL_INIT" ;
VAL_ 1664 maxBrickVoltage_SC01 65535 "SNA" ;
VAL_ 1664 minBrickVoltage_SC01 65535 "SNA" ;
VAL_ 1664 cmbLastUpdateTime_SC01 255 "SNA" ;
VAL_ 1664 weldCheckState_SC01 4 "WELDCHECK_IDLE" 3 "WELDCHECK" 2 "WELDCHECK_ISO_2" 1 "WELDCHECK_ISO_1" 0 "WELDCHECK_INIT" ;
VAL_ 1664 debugFastMpex_SC01 0 "F00" 1 "F01" 2 "F02" 3 "F03" 4 "F04" 5 "F05" 6 "F06" 7 "F07" 8 "F08" 9 "F09" 10 "F10" 11 "F11" 12 "F12" 13 "F13" 14 "F14" 15 "F15" ;
VAL_ 1664 SPIRxTxTimeAllPckts_SC01 255 "SNA" ;
VAL_ 1664 stateContactorControl_SC01 1 "SAFESTATE_UNSAFE" 0 "SAFESTATE_SAFE" ;
VAL_ 1664 analogCntrPwrPlus_SC01 255 "SNA" ;
VAL_ 1664 weldedState_SC01 2 "CTR_WELD_SNA" 0 "CTR_NOTWELDED" 1 "CTR_ATLEASTONE_WELDED" ;
VAL_ 1664 stateVoltage_SC01 1 "SAFESTATE_UNSAFE" 0 "SAFESTATE_SAFE" ;
VAL_ 1664 stateTemperature_SC01 1 "SAFESTATE_UNSAFE" 0 "SAFESTATE_SAFE" ;
VAL_ 1664 stateSelfTest_SC01 1 "SAFESTATE_UNSAFE" 0 "SAFESTATE_SAFE" ;
VAL_ 1664 stateHVIL_SC01 1 "SAFESTATE_UNSAFE" 0 "SAFESTATE_SAFE" ;
VAL_ 1664 stateCurrent_SC01 1 "SAFESTATE_UNSAFE" 0 "SAFESTATE_SAFE" ;
VAL_ 1664 stateCrash2_SC01 1 "SAFESTATE_UNSAFE" 0 "SAFESTATE_SAFE" ;
VAL_ 1664 stateCrash1_SC01 1 "SAFESTATE_UNSAFE" 0 "SAFESTATE_SAFE" ;
VAL_ 1664 stateContactors_SC01 1 "SAFESTATE_UNSAFE" 0 "SAFESTATE_SAFE" ;
VAL_ 1664 stateCANRx_SC01 1 "SAFESTATE_UNSAFE" 0 "SAFESTATE_SAFE" ;
VAL_ 1664 itemState_SC01 15 "ITEM_INVALID" 2 "ITEM_EMERGENCY" 1 "ITEM_OFF" 0 "ITEM_ON" ;
VAL_ 1664 posPack_SC01 65535 "SNA" ;
VAL_ 1664 posLink_SC01 65535 "SNA" ;
VAL_ 1664 negPack_SC01 65535 "SNA" ;
VAL_ 1664 negLink_SC01 65535 "SNA" ;
VAL_ 1664 hallCurrent_SC01 4095 "SNA" ;
VAL_ 1664 analogCntrPwrPlusISense_SC01 255 "SNA" ;
VAL_ 1664 analogCntrPwrPlusSwitched_SC01 255 "SNA" ;
VAL_ 1920 cmbCoolantTemp08_BMS01 255 "SNA" ;
VAL_ 1920 cmbCoolantTemp07_BMS01 255 "SNA" ;
VAL_ 1920 cmbCoolantTemp06_BMS01 255 "SNA" ;
VAL_ 1920 cmbCoolantTemp05_BMS01 255 "SNA" ;
VAL_ 1920 cmbCoolantTemp04_BMS01 255 "SNA" ;
VAL_ 1920 cmbCoolantTemp03_BMS01 255 "SNA" ;
VAL_ 1920 cmbCoolantTemp02_BMS01 255 "SNA" ;
VAL_ 1920 cmbCoolantTemp01_BMS01 255 "SNA" ;
VAL_ 1920 cmbOnboardPressure32_BMS01 65535 "SNA" ;
VAL_ 1920 cmbOnboardPressure31_BMS01 65535 "SNA" ;
VAL_ 1920 cmbOnboardPressure30_BMS01 65535 "SNA" ;
VAL_ 1920 cmbOnboardPressure29_BMS01 65535 "SNA" ;
VAL_ 1920 cmbOnboardPressure28_BMS01 65535 "SNA" ;
VAL_ 1920 cmbOnboardPressure27_BMS01 65535 "SNA" ;
VAL_ 1920 cmbOnboardPressure26_BMS01 65535 "SNA" ;
VAL_ 1920 cmbOnboardPressure25_BMS01 65535 "SNA" ;
VAL_ 1920 cmbOnboardPressure24_BMS01 65535 "SNA" ;
VAL_ 1920 cmbOnboardPressure23_BMS01 65535 "SNA" ;
VAL_ 1920 cmbOnboardPressure22_BMS01 65535 "SNA" ;
VAL_ 1920 cmbOnboardPressure21_BMS01 65535 "SNA" ;
VAL_ 1920 cmbOnboardPressure20_BMS01 65535 "SNA" ;
VAL_ 1920 cmbOnboardPressure19_BMS01 65535 "SNA" ;
VAL_ 1920 cmbOnboardPressure18_BMS01 65535 "SNA" ;
VAL_ 1920 cmbOnboardPressure17_BMS01 65535 "SNA" ;
VAL_ 1920 cmbOnboardPressure16_BMS01 65535 "SNA" ;
VAL_ 1920 cmbOnboardPressure15_BMS01 65535 "SNA" ;
VAL_ 1920 cmbOnboardPressure14_BMS01 65535 "SNA" ;
VAL_ 1920 cmbOnboardPressure13_BMS01 65535 "SNA" ;
VAL_ 1920 cmbOnboardPressure12_BMS01 65535 "SNA" ;
VAL_ 1920 cmbOnboardPressure11_BMS01 65535 "SNA" ;
VAL_ 1920 cmbOnboardPressure10_BMS01 65535 "SNA" ;
VAL_ 1920 cmbOnboardPressure09_BMS01 65535 "SNA" ;
VAL_ 1920 cmbOnboardPressure08_BMS01 65535 "SNA" ;
VAL_ 1920 cmbOnboardPressure07_BMS01 65535 "SNA" ;
VAL_ 1920 cmbOnboardPressure06_BMS01 65535 "SNA" ;
VAL_ 1920 cmbOnboardPressure05_BMS01 65535 "SNA" ;
VAL_ 1920 cmbOnboardPressure04_BMS01 65535 "SNA" ;
VAL_ 1920 cmbOnboardPressure03_BMS01 65535 "SNA" ;
VAL_ 1920 cmbOnboardPressure02_BMS01 65535 "SNA" ;
VAL_ 1920 cmbOnboardPressure01_BMS01 65535 "SNA" ;
VAL_ 1920 onboardMultiplexor_BMS01 32 "O32" 31 "O31" 30 "O30" 29 "O29" 28 "O28" 27 "O27" 26 "O26" 25 "O25" 24 "O24" 23 "O23" 22 "O22" 21 "O21" 20 "O20" 19 "O19" 18 "O18" 17 "O17" 16 "O16" 15 "O15" 14 "O14" 13 "O13" 0 "O00" 1 "O01" 2 "O02" 3 "O03" 4 "O04" 5 "O05" 6 "O06" 7 "O07" 8 "O08" 9 "O09" 10 "O10" 11 "O11" 12 "O12" ;
VAL_ 1920 minCmbOnboardTemperature_BMS01 255 "SNA" ;
VAL_ 1920 minCmbOnboardHumidity_BMS01 255 "SNA" ;
VAL_ 1920 maxCmbOnboardTemperature_BMS01 255 "SNA" ;
VAL_ 1920 maxCmbOnboardHumidity_BMS01 255 "SNA" ;
VAL_ 1920 bmsOnboardTemperature_BMS01 255 "SNA" ;
VAL_ 1920 bmsOnboardHumidity_BMS01 255 "SNA" ;
VAL_ 1920 cmbOnboardTemperature01_BMS01 255 "SNA" ;
VAL_ 1920 cmbOnboardHumidity01_BMS01 255 "SNA" ;
VAL_ 1920 moduleHeaterCurrent01_BMS01 255 "SNA" ;
VAL_ 1920 cmbOnboardTemperature02_BMS01 255 "SNA" ;
VAL_ 1920 cmbOnboardHumidity02_BMS01 255 "SNA" ;
VAL_ 1920 moduleHeaterCurrent02_BMS01 255 "SNA" ;
VAL_ 1920 cmbOnboardTemperature03_BMS01 255 "SNA" ;
VAL_ 1920 cmbOnboardHumidity03_BMS01 255 "SNA" ;
VAL_ 1920 moduleHeaterCurrent03_BMS01 255 "SNA" ;
VAL_ 1920 cmbOnboardTemperature04_BMS01 255 "SNA" ;
VAL_ 1920 cmbOnboardHumidity04_BMS01 255 "SNA" ;
VAL_ 1920 moduleHeaterCurrent04_BMS01 255 "SNA" ;
VAL_ 1920 cmbOnboardTemperature05_BMS01 255 "SNA" ;
VAL_ 1920 cmbOnboardHumidity05_BMS01 255 "SNA" ;
VAL_ 1920 moduleHeaterCurrent05_BMS01 255 "SNA" ;
VAL_ 1920 cmbOnboardTemperature06_BMS01 255 "SNA" ;
VAL_ 1920 cmbOnboardHumidity06_BMS01 255 "SNA" ;
VAL_ 1920 moduleHeaterCurrent06_BMS01 255 "SNA" ;
VAL_ 1920 cmbOnboardTemperature07_BMS01 255 "SNA" ;
VAL_ 1920 cmbOnboardHumidity07_BMS01 255 "SNA" ;
VAL_ 1920 moduleHeaterCurrent07_BMS01 255 "SNA" ;
VAL_ 1920 cmbOnboardTemperature08_BMS01 255 "SNA" ;
VAL_ 1920 cmbOnboardHumidity08_BMS01 255 "SNA" ;
VAL_ 1920 moduleHeaterCurrent08_BMS01 255 "SNA" ;
VAL_ 1920 cmbOnboardTemperature09_BMS01 255 "SNA" ;
VAL_ 1920 cmbOnboardHumidity09_BMS01 255 "SNA" ;
VAL_ 1920 moduleHeaterCurrent09_BMS01 255 "SNA" ;
VAL_ 1920 cmbOnboardTemperature10_BMS01 255 "SNA" ;
VAL_ 1920 cmbOnboardHumidity10_BMS01 255 "SNA" ;
VAL_ 1920 moduleHeaterCurrent10_BMS01 255 "SNA" ;
VAL_ 1920 cmbOnboardTemperature11_BMS01 255 "SNA" ;
VAL_ 1920 cmbOnboardHumidity11_BMS01 255 "SNA" ;
VAL_ 1920 moduleHeaterCurrent11_BMS01 255 "SNA" ;
VAL_ 1920 cmbOnboardTemperature12_BMS01 255 "SNA" ;
VAL_ 1920 cmbOnboardHumidity12_BMS01 255 "SNA" ;
VAL_ 1920 moduleHeaterCurrent12_BMS01 255 "SNA" ;
VAL_ 1920 cmbOnboardTemperature13_BMS01 255 "SNA" ;
VAL_ 1920 cmbOnboardHumidity13_BMS01 255 "SNA" ;
VAL_ 1920 moduleHeaterCurrent13_BMS01 255 "SNA" ;
VAL_ 1920 cmbOnboardTemperature14_BMS01 255 "SNA" ;
VAL_ 1920 cmbOnboardHumidity14_BMS01 255 "SNA" ;
VAL_ 1920 moduleHeaterCurrent14_BMS01 255 "SNA" ;
VAL_ 1920 cmbOnboardTemperature15_BMS01 255 "SNA" ;
VAL_ 1920 cmbOnboardHumidity15_BMS01 255 "SNA" ;
VAL_ 1920 moduleHeaterCurrent15_BMS01 255 "SNA" ;
VAL_ 1920 cmbOnboardTemperature16_BMS01 255 "SNA" ;
VAL_ 1920 cmbOnboardHumidity16_BMS01 255 "SNA" ;
VAL_ 1920 moduleHeaterCurrent16_BMS01 255 "SNA" ;
VAL_ 1920 cmbOnboardTemperature17_BMS01 255 "SNA" ;
VAL_ 1920 cmbOnboardHumidity17_BMS01 255 "SNA" ;
VAL_ 1920 moduleHeaterCurrent17_BMS01 255 "SNA" ;
VAL_ 1920 cmbOnboardTemperature18_BMS01 255 "SNA" ;
VAL_ 1920 cmbOnboardHumidity18_BMS01 255 "SNA" ;
VAL_ 1920 moduleHeaterCurrent18_BMS01 255 "SNA" ;
VAL_ 1920 cmbOnboardTemperature19_BMS01 255 "SNA" ;
VAL_ 1920 cmbOnboardHumidity19_BMS01 255 "SNA" ;
VAL_ 1920 moduleHeaterCurrent19_BMS01 255 "SNA" ;
VAL_ 1920 cmbOnboardTemperature20_BMS01 255 "SNA" ;
VAL_ 1920 cmbOnboardHumidity20_BMS01 255 "SNA" ;
VAL_ 1920 moduleHeaterCurrent20_BMS01 255 "SNA" ;
VAL_ 1920 cmbOnboardTemperature21_BMS01 255 "SNA" ;
VAL_ 1920 cmbOnboardHumidity21_BMS01 255 "SNA" ;
VAL_ 1920 moduleHeaterCurrent21_BMS01 255 "SNA" ;
VAL_ 1920 cmbOnboardTemperature22_BMS01 255 "SNA" ;
VAL_ 1920 cmbOnboardHumidity22_BMS01 255 "SNA" ;
VAL_ 1920 moduleHeaterCurrent22_BMS01 255 "SNA" ;
VAL_ 1920 cmbOnboardTemperature23_BMS01 255 "SNA" ;
VAL_ 1920 cmbOnboardHumidity23_BMS01 255 "SNA" ;
VAL_ 1920 moduleHeaterCurrent23_BMS01 255 "SNA" ;
VAL_ 1920 cmbOnboardTemperature24_BMS01 255 "SNA" ;
VAL_ 1920 cmbOnboardHumidity24_BMS01 255 "SNA" ;
VAL_ 1920 moduleHeaterCurrent24_BMS01 255 "SNA" ;
VAL_ 1920 cmbOnboardTemperature25_BMS01 255 "SNA" ;
VAL_ 1920 cmbOnboardHumidity25_BMS01 255 "SNA" ;
VAL_ 1920 moduleHeaterCurrent25_BMS01 255 "SNA" ;
VAL_ 1920 cmbOnboardTemperature26_BMS01 255 "SNA" ;
VAL_ 1920 cmbOnboardHumidity26_BMS01 255 "SNA" ;
VAL_ 1920 moduleHeaterCurrent26_BMS01 255 "SNA" ;
VAL_ 1920 cmbOnboardTemperature27_BMS01 255 "SNA" ;
VAL_ 1920 cmbOnboardHumidity27_BMS01 255 "SNA" ;
VAL_ 1920 moduleHeaterCurrent27_BMS01 255 "SNA" ;
VAL_ 1920 cmbOnboardTemperature28_BMS01 255 "SNA" ;
VAL_ 1920 cmbOnboardHumidity28_BMS01 255 "SNA" ;
VAL_ 1920 moduleHeaterCurrent28_BMS01 255 "SNA" ;
VAL_ 1920 cmbOnboardTemperature29_BMS01 255 "SNA" ;
VAL_ 1920 cmbOnboardHumidity29_BMS01 255 "SNA" ;
VAL_ 1920 moduleHeaterCurrent29_BMS01 255 "SNA" ;
VAL_ 1920 cmbOnboardTemperature30_BMS01 255 "SNA" ;
VAL_ 1920 cmbOnboardHumidity30_BMS01 255 "SNA" ;
VAL_ 1920 moduleHeaterCurrent30_BMS01 255 "SNA" ;
VAL_ 1920 cmbOnboardTemperature31_BMS01 255 "SNA" ;
VAL_ 1920 cmbOnboardHumidity31_BMS01 255 "SNA" ;
VAL_ 1920 moduleHeaterCurrent31_BMS01 255 "SNA" ;
VAL_ 1920 cmbOnboardTemperature32_BMS01 255 "SNA" ;
VAL_ 1920 cmbOnboardHumidity32_BMS01 255 "SNA" ;
VAL_ 1920 moduleHeaterCurrent32_BMS01 255 "SNA" ;
VAL_ 1984 cmbMultiplexor_BMS01 0 "C000" 1 "C001" 2 "C002" 3 "C003" 4 "C004" 5 "C005" 6 "C006" 7 "C007" 8 "C008" 9 "C009" 10 "C010" 11 "C011" 12 "C012" 13 "C013" 14 "C014" 15 "C015" 16 "C016" 17 "C017" 18 "C018" 19 "C019" 20 "C020" 21 "C021" 22 "C022" 23 "C023" 24 "C024" 25 "C025" 26 "C026" 27 "C027" 28 "C028" 29 "C029" 30 "C030" 31 "C031" 32 "C032" 33 "C033" 34 "C034" 35 "C035" 36 "C036" 37 "C037" 38 "C038" 39 "C039" 40 "C040" 41 "C041" 42 "C042" 43 "C043" 44 "C044" 45 "C045" 46 "C046" 47 "C047" 48 "C048" 49 "C049" 50 "C050" 51 "C051" 52 "C052" 53 "C053" 54 "C054" 55 "C055" 56 "C056" 57 "C057" 58 "C058" 59 "C059" 60 "C060" 61 "C061" 62 "C062" 63 "C063" 64 "C064" 65 "C065" 66 "C066" 67 "C067" 68 "C068" 69 "C069" 70 "C070" 71 "C071" 72 "C072" 73 "C073" 74 "C074" 75 "C075" 76 "C076" 77 "C077" 78 "C078" 79 "C079" 80 "C080" 81 "C081" 82 "C082" 83 "C083" 84 "C084" 85 "C085" 86 "C086" 87 "C087" 88 "C088" 89 "C089" 90 "C090" 91 "C091" 92 "C092" 93 "C093" 94 "C094" 95 "C095" 96 "C096" 97 "C097" 98 "C098" 99 "C099" 100 "C100" 101 "C101" 102 "C102" 103 "C103" 104 "C104" 105 "C105" 106 "C106" 107 "C107" 108 "C108" 109 "C109" 110 "C110" 111 "C111" 112 "C112" 113 "C113" 114 "C114" 115 "C115" 116 "C116" 117 "C117" 118 "C118" 119 "C119" 120 "C120" 121 "C121" 122 "C122" 123 "C123" 124 "C124" 125 "C125" 126 "C126" 127 "C127" 128 "C128" 129 "C129" 130 "C130" 131 "C131" 132 "C132" 133 "C133" 134 "C134" 135 "C135" 136 "C136" 137 "C137" 138 "C138" 139 "C139" 140 "C140" 141 "C141" 142 "C142" 143 "C143" 144 "C144" 145 "C145" 146 "C146" 147 "C147" 148 "C148" 149 "C149" 150 "C150" 151 "C151" 152 "C152" 153 "C153" 154 "C154" 155 "C155" 156 "C156" 157 "C157" 158 "C158" 159 "C159" 160 "C160" 161 "C161" 162 "C162" 163 "C163" 164 "C164" 165 "C165" 166 "C166" 167 "C167" 168 "C168" 169 "C169" 170 "C170" 171 "C171" 172 "C172" 173 "C173" 174 "C174" 175 "C175" 176 "C176" 177 "C177" 178 "C178" 179 "C179" 180 "C180" 181 "C181" 182 "C182" 183 "C183" 184 "C184" 185 "C185" 186 "C186" 187 "C187" 188 "C188" 189 "C189" 190 "C190" 191 "C191" 192 "C192" ;
VAL_ 1984 moduleTemperature01_BMS01 255 "SNA" ;
VAL_ 1984 brickVoltage001_BMS01 65535 "SNA" ;
VAL_ 1984 brickVoltage002_BMS01 65535 "SNA" ;
VAL_ 1984 brickVoltage003_BMS01 65535 "SNA" ;
VAL_ 1984 moduleTemperature02_BMS01 255 "SNA" ;
VAL_ 1984 brickVoltage004_BMS01 65535 "SNA" ;
VAL_ 1984 brickVoltage005_BMS01 65535 "SNA" ;
VAL_ 1984 brickVoltage006_BMS01 65535 "SNA" ;
VAL_ 1984 moduleTemperature03_BMS01 255 "SNA" ;
VAL_ 1984 brickVoltage007_BMS01 65535 "SNA" ;
VAL_ 1984 brickVoltage008_BMS01 65535 "SNA" ;
VAL_ 1984 brickVoltage009_BMS01 65535 "SNA" ;
VAL_ 1984 moduleTemperature04_BMS01 255 "SNA" ;
VAL_ 1984 brickVoltage010_BMS01 65535 "SNA" ;
VAL_ 1984 brickVoltage011_BMS01 65535 "SNA" ;
VAL_ 1984 brickVoltage012_BMS01 65535 "SNA" ;
VAL_ 1984 moduleTemperature05_BMS01 255 "SNA" ;
VAL_ 1984 brickVoltage013_BMS01 65535 "SNA" ;
VAL_ 1984 brickVoltage014_BMS01 65535 "SNA" ;
VAL_ 1984 brickVoltage015_BMS01 65535 "SNA" ;
VAL_ 1984 moduleTemperature06_BMS01 255 "SNA" ;
VAL_ 1984 brickVoltage016_BMS01 65535 "SNA" ;
VAL_ 1984 brickVoltage017_BMS01 65535 "SNA" ;
VAL_ 1984 brickVoltage018_BMS01 65535 "SNA" ;
VAL_ 1984 moduleTemperature07_BMS01 255 "SNA" ;
VAL_ 1984 brickVoltage019_BMS01 65535 "SNA" ;
VAL_ 1984 brickVoltage020_BMS01 65535 "SNA" ;
VAL_ 1984 brickVoltage021_BMS01 65535 "SNA" ;
VAL_ 1984 moduleTemperature08_BMS01 255 "SNA" ;
VAL_ 1984 brickVoltage022_BMS01 65535 "SNA" ;
VAL_ 1984 brickVoltage023_BMS01 65535 "SNA" ;
VAL_ 1984 brickVoltage024_BMS01 65535 "SNA" ;
VAL_ 1984 moduleTemperature09_BMS01 255 "SNA" ;
VAL_ 1984 brickVoltage025_BMS01 65535 "SNA" ;
VAL_ 1984 brickVoltage026_BMS01 65535 "SNA" ;
VAL_ 1984 brickVoltage027_BMS01 65535 "SNA" ;
VAL_ 1984 moduleTemperature10_BMS01 255 "SNA" ;
VAL_ 1984 brickVoltage028_BMS01 65535 "SNA" ;
VAL_ 1984 brickVoltage029_BMS01 65535 "SNA" ;
VAL_ 1984 brickVoltage030_BMS01 65535 "SNA" ;
VAL_ 1984 moduleTemperature11_BMS01 255 "SNA" ;
VAL_ 1984 brickVoltage031_BMS01 65535 "SNA" ;
VAL_ 1984 brickVoltage032_BMS01 65535 "SNA" ;
VAL_ 1984 brickVoltage033_BMS01 65535 "SNA" ;
VAL_ 1984 moduleTemperature12_BMS01 255 "SNA" ;
VAL_ 1984 brickVoltage034_BMS01 65535 "SNA" ;
VAL_ 1984 brickVoltage035_BMS01 65535 "SNA" ;
VAL_ 1984 brickVoltage036_BMS01 65535 "SNA" ;
VAL_ 1984 moduleTemperature13_BMS01 255 "SNA" ;
VAL_ 1984 brickVoltage037_BMS01 65535 "SNA" ;
VAL_ 1984 brickVoltage038_BMS01 65535 "SNA" ;
VAL_ 1984 brickVoltage039_BMS01 65535 "SNA" ;
VAL_ 1984 moduleTemperature14_BMS01 255 "SNA" ;
VAL_ 1984 brickVoltage040_BMS01 65535 "SNA" ;
VAL_ 1984 brickVoltage041_BMS01 65535 "SNA" ;
VAL_ 1984 brickVoltage042_BMS01 65535 "SNA" ;
VAL_ 1984 moduleTemperature15_BMS01 255 "SNA" ;
VAL_ 1984 brickVoltage043_BMS01 65535 "SNA" ;
VAL_ 1984 brickVoltage044_BMS01 65535 "SNA" ;
VAL_ 1984 brickVoltage045_BMS01 65535 "SNA" ;
VAL_ 1984 moduleTemperature16_BMS01 255 "SNA" ;
VAL_ 1984 brickVoltage046_BMS01 65535 "SNA" ;
VAL_ 1984 brickVoltage047_BMS01 65535 "SNA" ;
VAL_ 1984 brickVoltage048_BMS01 65535 "SNA" ;
VAL_ 1984 moduleTemperature17_BMS01 255 "SNA" ;
VAL_ 1984 brickVoltage049_BMS01 65535 "SNA" ;
VAL_ 1984 brickVoltage050_BMS01 65535 "SNA" ;
VAL_ 1984 brickVoltage051_BMS01 65535 "SNA" ;
VAL_ 1984 moduleTemperature18_BMS01 255 "SNA" ;
VAL_ 1984 brickVoltage052_BMS01 65535 "SNA" ;
VAL_ 1984 brickVoltage053_BMS01 65535 "SNA" ;
VAL_ 1984 brickVoltage054_BMS01 65535 "SNA" ;
VAL_ 1984 moduleTemperature19_BMS01 255 "SNA" ;
VAL_ 1984 brickVoltage055_BMS01 65535 "SNA" ;
VAL_ 1984 brickVoltage056_BMS01 65535 "SNA" ;
VAL_ 1984 brickVoltage057_BMS01 65535 "SNA" ;
VAL_ 1984 moduleTemperature20_BMS01 255 "SNA" ;
VAL_ 1984 brickVoltage058_BMS01 65535 "SNA" ;
VAL_ 1984 brickVoltage059_BMS01 65535 "SNA" ;
VAL_ 1984 brickVoltage060_BMS01 65535 "SNA" ;
VAL_ 1984 moduleTemperature21_BMS01 255 "SNA" ;
VAL_ 1984 brickVoltage061_BMS01 65535 "SNA" ;
VAL_ 1984 brickVoltage062_BMS01 65535 "SNA" ;
VAL_ 1984 brickVoltage063_BMS01 65535 "SNA" ;
VAL_ 1984 moduleTemperature22_BMS01 255 "SNA" ;
VAL_ 1984 brickVoltage064_BMS01 65535 "SNA" ;
VAL_ 1984 brickVoltage065_BMS01 65535 "SNA" ;
VAL_ 1984 brickVoltage066_BMS01 65535 "SNA" ;
VAL_ 1984 moduleTemperature23_BMS01 255 "SNA" ;
VAL_ 1984 brickVoltage067_BMS01 65535 "SNA" ;
VAL_ 1984 brickVoltage068_BMS01 65535 "SNA" ;
VAL_ 1984 brickVoltage069_BMS01 65535 "SNA" ;
VAL_ 1984 moduleTemperature24_BMS01 255 "SNA" ;
VAL_ 1984 brickVoltage070_BMS01 65535 "SNA" ;
VAL_ 1984 brickVoltage071_BMS01 65535 "SNA" ;
VAL_ 1984 brickVoltage072_BMS01 65535 "SNA" ;
VAL_ 1984 moduleTemperature25_BMS01 255 "SNA" ;
VAL_ 1984 brickVoltage073_BMS01 65535 "SNA" ;
VAL_ 1984 brickVoltage074_BMS01 65535 "SNA" ;
VAL_ 1984 brickVoltage075_BMS01 65535 "SNA" ;
VAL_ 1984 moduleTemperature26_BMS01 255 "SNA" ;
VAL_ 1984 brickVoltage076_BMS01 65535 "SNA" ;
VAL_ 1984 brickVoltage077_BMS01 65535 "SNA" ;
VAL_ 1984 brickVoltage078_BMS01 65535 "SNA" ;
VAL_ 1984 moduleTemperature27_BMS01 255 "SNA" ;
VAL_ 1984 brickVoltage079_BMS01 65535 "SNA" ;
VAL_ 1984 brickVoltage080_BMS01 65535 "SNA" ;
VAL_ 1984 brickVoltage081_BMS01 65535 "SNA" ;
VAL_ 1984 moduleTemperature28_BMS01 255 "SNA" ;
VAL_ 1984 brickVoltage082_BMS01 65535 "SNA" ;
VAL_ 1984 brickVoltage083_BMS01 65535 "SNA" ;
VAL_ 1984 brickVoltage084_BMS01 65535 "SNA" ;
VAL_ 1984 moduleTemperature29_BMS01 255 "SNA" ;
VAL_ 1984 brickVoltage085_BMS01 65535 "SNA" ;
VAL_ 1984 brickVoltage086_BMS01 65535 "SNA" ;
VAL_ 1984 brickVoltage087_BMS01 65535 "SNA" ;
VAL_ 1984 moduleTemperature30_BMS01 255 "SNA" ;
VAL_ 1984 brickVoltage088_BMS01 65535 "SNA" ;
VAL_ 1984 brickVoltage089_BMS01 65535 "SNA" ;
VAL_ 1984 brickVoltage090_BMS01 65535 "SNA" ;
VAL_ 1984 moduleTemperature31_BMS01 255 "SNA" ;
VAL_ 1984 brickVoltage091_BMS01 65535 "SNA" ;
VAL_ 1984 brickVoltage092_BMS01 65535 "SNA" ;
VAL_ 1984 brickVoltage093_BMS01 65535 "SNA" ;
VAL_ 1984 moduleTemperature32_BMS01 255 "SNA" ;
VAL_ 1984 brickVoltage094_BMS01 65535 "SNA" ;
VAL_ 1984 brickVoltage095_BMS01 65535 "SNA" ;
VAL_ 1984 brickVoltage096_BMS01 65535 "SNA" ;
VAL_ 1984 brickVoltage097_BMS01 65535 "SNA" ;
VAL_ 1984 brickVoltage098_BMS01 65535 "SNA" ;
VAL_ 1984 brickVoltage099_BMS01 65535 "SNA" ;
VAL_ 1984 brickVoltage100_BMS01 65535 "SNA" ;
VAL_ 1984 brickVoltage101_BMS01 65535 "SNA" ;
VAL_ 1984 brickVoltage102_BMS01 65535 "SNA" ;
VAL_ 1984 brickVoltage103_BMS01 65535 "SNA" ;
VAL_ 1984 brickVoltage104_BMS01 65535 "SNA" ;
VAL_ 1984 brickVoltage105_BMS01 65535 "SNA" ;
VAL_ 1984 brickVoltage106_BMS01 65535 "SNA" ;
VAL_ 1984 brickVoltage107_BMS01 65535 "SNA" ;
VAL_ 1984 brickVoltage108_BMS01 65535 "SNA" ;
VAL_ 1984 brickVoltage109_BMS01 65535 "SNA" ;
VAL_ 1984 brickVoltage110_BMS01 65535 "SNA" ;
VAL_ 1984 brickVoltage111_BMS01 65535 "SNA" ;
VAL_ 1984 brickVoltage112_BMS01 65535 "SNA" ;
VAL_ 1984 brickVoltage113_BMS01 65535 "SNA" ;
VAL_ 1984 brickVoltage114_BMS01 65535 "SNA" ;
VAL_ 1984 brickVoltage115_BMS01 65535 "SNA" ;
VAL_ 1984 brickVoltage116_BMS01 65535 "SNA" ;
VAL_ 1984 brickVoltage117_BMS01 65535 "SNA" ;
VAL_ 1984 brickVoltage118_BMS01 65535 "SNA" ;
VAL_ 1984 brickVoltage119_BMS01 65535 "SNA" ;
VAL_ 1984 brickVoltage120_BMS01 65535 "SNA" ;
VAL_ 1984 brickVoltage121_BMS01 65535 "SNA" ;
VAL_ 1984 brickVoltage122_BMS01 65535 "SNA" ;
VAL_ 1984 brickVoltage123_BMS01 65535 "SNA" ;
VAL_ 1984 brickVoltage124_BMS01 65535 "SNA" ;
VAL_ 1984 brickVoltage125_BMS01 65535 "SNA" ;
VAL_ 1984 brickVoltage126_BMS01 65535 "SNA" ;
VAL_ 1984 brickVoltage127_BMS01 65535 "SNA" ;
VAL_ 1984 brickVoltage128_BMS01 65535 "SNA" ;
VAL_ 1984 brickVoltage129_BMS01 65535 "SNA" ;
VAL_ 1984 brickVoltage130_BMS01 65535 "SNA" ;
VAL_ 1984 brickVoltage131_BMS01 65535 "SNA" ;
VAL_ 1984 brickVoltage132_BMS01 65535 "SNA" ;
VAL_ 1984 brickVoltage133_BMS01 65535 "SNA" ;
VAL_ 1984 brickVoltage134_BMS01 65535 "SNA" ;
VAL_ 1984 brickVoltage135_BMS01 65535 "SNA" ;
VAL_ 1984 brickVoltage136_BMS01 65535 "SNA" ;
VAL_ 1984 brickVoltage137_BMS01 65535 "SNA" ;
VAL_ 1984 brickVoltage138_BMS01 65535 "SNA" ;
VAL_ 1984 brickVoltage139_BMS01 65535 "SNA" ;
VAL_ 1984 brickVoltage140_BMS01 65535 "SNA" ;
VAL_ 1984 brickVoltage141_BMS01 65535 "SNA" ;
VAL_ 1984 brickVoltage142_BMS01 65535 "SNA" ;
VAL_ 1984 brickVoltage143_BMS01 65535 "SNA" ;
VAL_ 1984 brickVoltage144_BMS01 65535 "SNA" ;
VAL_ 1984 brickVoltage145_BMS01 65535 "SNA" ;
VAL_ 1984 brickVoltage146_BMS01 65535 "SNA" ;
VAL_ 1984 brickVoltage147_BMS01 65535 "SNA" ;
VAL_ 1984 brickVoltage148_BMS01 65535 "SNA" ;
VAL_ 1984 brickVoltage149_BMS01 65535 "SNA" ;
VAL_ 1984 brickVoltage150_BMS01 65535 "SNA" ;
VAL_ 1984 brickVoltage151_BMS01 65535 "SNA" ;
VAL_ 1984 brickVoltage152_BMS01 65535 "SNA" ;
VAL_ 1984 brickVoltage153_BMS01 65535 "SNA" ;
VAL_ 1984 brickVoltage154_BMS01 65535 "SNA" ;
VAL_ 1984 brickVoltage155_BMS01 65535 "SNA" ;
VAL_ 1984 brickVoltage156_BMS01 65535 "SNA" ;
VAL_ 1984 brickVoltage157_BMS01 65535 "SNA" ;
VAL_ 1984 brickVoltage158_BMS01 65535 "SNA" ;
VAL_ 1984 brickVoltage159_BMS01 65535 "SNA" ;
VAL_ 1984 brickVoltage160_BMS01 65535 "SNA" ;
VAL_ 1984 brickVoltage161_BMS01 65535 "SNA" ;
VAL_ 1984 brickVoltage162_BMS01 65535 "SNA" ;
VAL_ 1984 brickVoltage163_BMS01 65535 "SNA" ;
VAL_ 1984 brickVoltage164_BMS01 65535 "SNA" ;
VAL_ 1984 brickVoltage165_BMS01 65535 "SNA" ;
VAL_ 1984 brickVoltage166_BMS01 65535 "SNA" ;
VAL_ 1984 brickVoltage167_BMS01 65535 "SNA" ;
VAL_ 1984 brickVoltage168_BMS01 65535 "SNA" ;
VAL_ 1984 brickVoltage169_BMS01 65535 "SNA" ;
VAL_ 1984 brickVoltage170_BMS01 65535 "SNA" ;
VAL_ 1984 brickVoltage171_BMS01 65535 "SNA" ;
VAL_ 1984 brickVoltage172_BMS01 65535 "SNA" ;
VAL_ 1984 brickVoltage173_BMS01 65535 "SNA" ;
VAL_ 1984 brickVoltage174_BMS01 65535 "SNA" ;
VAL_ 1984 brickVoltage175_BMS01 65535 "SNA" ;
VAL_ 1984 brickVoltage176_BMS01 65535 "SNA" ;
VAL_ 1984 brickVoltage177_BMS01 65535 "SNA" ;
VAL_ 1984 brickVoltage178_BMS01 65535 "SNA" ;
VAL_ 1984 brickVoltage179_BMS01 65535 "SNA" ;
VAL_ 1984 brickVoltage180_BMS01 65535 "SNA" ;
VAL_ 1984 brickVoltage181_BMS01 65535 "SNA" ;
VAL_ 1984 brickVoltage182_BMS01 65535 "SNA" ;
VAL_ 1984 brickVoltage183_BMS01 65535 "SNA" ;
VAL_ 1984 brickVoltage184_BMS01 65535 "SNA" ;
VAL_ 1984 brickVoltage185_BMS01 65535 "SNA" ;
VAL_ 1984 brickVoltage186_BMS01 65535 "SNA" ;
VAL_ 1984 brickVoltage187_BMS01 65535 "SNA" ;
VAL_ 1984 brickVoltage188_BMS01 65535 "SNA" ;
VAL_ 1984 brickVoltage189_BMS01 65535 "SNA" ;
VAL_ 1984 brickVoltage190_BMS01 65535 "SNA" ;
VAL_ 1984 brickVoltage191_BMS01 65535 "SNA" ;
VAL_ 1984 brickVoltage192_BMS01 65535 "SNA" ;
VAL_ 1984 brickVoltage193_BMS01 65535 "SNA" ;
VAL_ 1984 brickVoltage194_BMS01 65535 "SNA" ;
VAL_ 1984 brickVoltage195_BMS01 65535 "SNA" ;
VAL_ 1984 brickVoltage196_BMS01 65535 "SNA" ;
VAL_ 1984 brickVoltage197_BMS01 65535 "SNA" ;
VAL_ 1984 brickVoltage198_BMS01 65535 "SNA" ;
VAL_ 1984 brickVoltage199_BMS01 65535 "SNA" ;
VAL_ 1984 brickVoltage200_BMS01 65535 "SNA" ;
VAL_ 1984 brickVoltage201_BMS01 65535 "SNA" ;
VAL_ 1984 brickVoltage202_BMS01 65535 "SNA" ;
VAL_ 1984 brickVoltage203_BMS01 65535 "SNA" ;
VAL_ 1984 brickVoltage204_BMS01 65535 "SNA" ;
VAL_ 1984 brickVoltage205_BMS01 65535 "SNA" ;
VAL_ 1984 brickVoltage206_BMS01 65535 "SNA" ;
VAL_ 1984 brickVoltage207_BMS01 65535 "SNA" ;
VAL_ 1984 brickVoltage208_BMS01 65535 "SNA" ;
VAL_ 1984 brickVoltage209_BMS01 65535 "SNA" ;
VAL_ 1984 brickVoltage210_BMS01 65535 "SNA" ;
VAL_ 1984 brickVoltage211_BMS01 65535 "SNA" ;
VAL_ 1984 brickVoltage212_BMS01 65535 "SNA" ;
VAL_ 1984 brickVoltage213_BMS01 65535 "SNA" ;
VAL_ 1984 brickVoltage214_BMS01 65535 "SNA" ;
VAL_ 1984 brickVoltage215_BMS01 65535 "SNA" ;
VAL_ 1984 brickVoltage216_BMS01 65535 "SNA" ;
VAL_ 1984 brickVoltage217_BMS01 65535 "SNA" ;
VAL_ 1984 brickVoltage218_BMS01 65535 "SNA" ;
VAL_ 1984 brickVoltage219_BMS01 65535 "SNA" ;
VAL_ 1984 brickVoltage220_BMS01 65535 "SNA" ;
VAL_ 1984 brickVoltage221_BMS01 65535 "SNA" ;
VAL_ 1984 brickVoltage222_BMS01 65535 "SNA" ;
VAL_ 1984 brickVoltage223_BMS01 65535 "SNA" ;
VAL_ 1984 brickVoltage224_BMS01 65535 "SNA" ;
VAL_ 1984 brickVoltage225_BMS01 65535 "SNA" ;
VAL_ 1984 brickVoltage226_BMS01 65535 "SNA" ;
VAL_ 1984 brickVoltage227_BMS01 65535 "SNA" ;
VAL_ 1984 brickVoltage228_BMS01 65535 "SNA" ;
VAL_ 1984 brickVoltage229_BMS01 65535 "SNA" ;
VAL_ 1984 brickVoltage230_BMS01 65535 "SNA" ;
VAL_ 1984 brickVoltage231_BMS01 65535 "SNA" ;
VAL_ 1984 brickVoltage232_BMS01 65535 "SNA" ;
VAL_ 1984 brickVoltage233_BMS01 65535 "SNA" ;
VAL_ 1984 brickVoltage234_BMS01 65535 "SNA" ;
VAL_ 1984 brickVoltage235_BMS01 65535 "SNA" ;
VAL_ 1984 brickVoltage236_BMS01 65535 "SNA" ;
VAL_ 1984 brickVoltage237_BMS01 65535 "SNA" ;
VAL_ 1984 brickVoltage238_BMS01 65535 "SNA" ;
VAL_ 1984 brickVoltage239_BMS01 65535 "SNA" ;
VAL_ 1984 brickVoltage240_BMS01 65535 "SNA" ;
VAL_ 1984 brickVoltage241_BMS01 65535 "SNA" ;
VAL_ 1984 brickVoltage242_BMS01 65535 "SNA" ;
VAL_ 1984 brickVoltage243_BMS01 65535 "SNA" ;
VAL_ 1984 brickVoltage244_BMS01 65535 "SNA" ;
VAL_ 1984 brickVoltage245_BMS01 65535 "SNA" ;
VAL_ 1984 brickVoltage246_BMS01 65535 "SNA" ;
VAL_ 1984 brickVoltage247_BMS01 65535 "SNA" ;
VAL_ 1984 brickVoltage248_BMS01 65535 "SNA" ;
VAL_ 1984 brickVoltage249_BMS01 65535 "SNA" ;
VAL_ 1984 brickVoltage250_BMS01 65535 "SNA" ;
VAL_ 1984 brickVoltage251_BMS01 65535 "SNA" ;
VAL_ 1984 brickVoltage252_BMS01 65535 "SNA" ;
VAL_ 1984 brickVoltage253_BMS01 65535 "SNA" ;
VAL_ 1984 brickVoltage254_BMS01 65535 "SNA" ;
VAL_ 1984 brickVoltage255_BMS01 65535 "SNA" ;
VAL_ 1984 brickVoltage256_BMS01 65535 "SNA" ;
VAL_ 1984 brickVoltage257_BMS01 65535 "SNA" ;
VAL_ 1984 brickVoltage258_BMS01 65535 "SNA" ;
VAL_ 1984 brickVoltage259_BMS01 65535 "SNA" ;
VAL_ 1984 brickVoltage260_BMS01 65535 "SNA" ;
VAL_ 1984 brickVoltage261_BMS01 65535 "SNA" ;
VAL_ 1984 brickVoltage262_BMS01 65535 "SNA" ;
VAL_ 1984 brickVoltage263_BMS01 65535 "SNA" ;
VAL_ 1984 brickVoltage264_BMS01 65535 "SNA" ;
VAL_ 1984 brickVoltage265_BMS01 65535 "SNA" ;
VAL_ 1984 brickVoltage266_BMS01 65535 "SNA" ;
VAL_ 1984 brickVoltage267_BMS01 65535 "SNA" ;
VAL_ 1984 brickVoltage268_BMS01 65535 "SNA" ;
VAL_ 1984 brickVoltage269_BMS01 65535 "SNA" ;
VAL_ 1984 brickVoltage270_BMS01 65535 "SNA" ;
VAL_ 1984 brickVoltage271_BMS01 65535 "SNA" ;
VAL_ 1984 brickVoltage272_BMS01 65535 "SNA" ;
VAL_ 1984 brickVoltage273_BMS01 65535 "SNA" ;
VAL_ 1984 brickVoltage274_BMS01 65535 "SNA" ;
VAL_ 1984 brickVoltage275_BMS01 65535 "SNA" ;
VAL_ 1984 brickVoltage276_BMS01 65535 "SNA" ;
VAL_ 1984 brickVoltage277_BMS01 65535 "SNA" ;
VAL_ 1984 brickVoltage278_BMS01 65535 "SNA" ;
VAL_ 1984 brickVoltage279_BMS01 65535 "SNA" ;
VAL_ 1984 brickVoltage280_BMS01 65535 "SNA" ;
VAL_ 1984 brickVoltage281_BMS01 65535 "SNA" ;
VAL_ 1984 brickVoltage282_BMS01 65535 "SNA" ;
VAL_ 1984 brickVoltage283_BMS01 65535 "SNA" ;
VAL_ 1984 brickVoltage284_BMS01 65535 "SNA" ;
VAL_ 1984 brickVoltage285_BMS01 65535 "SNA" ;
VAL_ 1984 brickVoltage286_BMS01 65535 "SNA" ;
VAL_ 1984 brickVoltage287_BMS01 65535 "SNA" ;
VAL_ 1984 brickVoltage288_BMS01 65535 "SNA" ;
VAL_ 1984 brickVoltage289_BMS01 65535 "SNA" ;
VAL_ 1984 brickVoltage290_BMS01 65535 "SNA" ;
VAL_ 1984 brickVoltage291_BMS01 65535 "SNA" ;
VAL_ 1984 brickVoltage292_BMS01 65535 "SNA" ;
VAL_ 1984 brickVoltage293_BMS01 65535 "SNA" ;
VAL_ 1984 brickVoltage294_BMS01 65535 "SNA" ;
VAL_ 1984 brickVoltage295_BMS01 65535 "SNA" ;
VAL_ 1984 brickVoltage296_BMS01 65535 "SNA" ;
VAL_ 1984 brickVoltage297_BMS01 65535 "SNA" ;
VAL_ 1984 brickVoltage298_BMS01 65535 "SNA" ;
VAL_ 1984 brickVoltage299_BMS01 65535 "SNA" ;
VAL_ 1984 brickVoltage300_BMS01 65535 "SNA" ;
VAL_ 1984 moduleTemperature33_BMS01 255 "SNA" ;
VAL_ 1984 moduleTemperature34_BMS01 255 "SNA" ;
VAL_ 1984 moduleTemperature35_BMS01 255 "SNA" ;
VAL_ 1984 moduleTemperature36_BMS01 255 "SNA" ;
VAL_ 1984 moduleTemperature37_BMS01 255 "SNA" ;
VAL_ 1984 moduleTemperature38_BMS01 255 "SNA" ;
VAL_ 1984 moduleTemperature39_BMS01 255 "SNA" ;
VAL_ 1984 moduleTemperature40_BMS01 255 "SNA" ;
VAL_ 1984 moduleTemperature41_BMS01 255 "SNA" ;
VAL_ 1984 moduleTemperature42_BMS01 255 "SNA" ;
VAL_ 1984 moduleTemperature43_BMS01 255 "SNA" ;
VAL_ 1984 moduleTemperature44_BMS01 255 "SNA" ;
VAL_ 1984 moduleTemperature45_BMS01 255 "SNA" ;
VAL_ 1984 moduleTemperature46_BMS01 255 "SNA" ;
VAL_ 1984 moduleTemperature47_BMS01 255 "SNA" ;
VAL_ 1984 moduleTemperature48_BMS01 255 "SNA" ;
VAL_ 1984 moduleTemperature49_BMS01 255 "SNA" ;
VAL_ 1984 moduleTemperature50_BMS01 255 "SNA" ;
VAL_ 1984 moduleTemperature51_BMS01 255 "SNA" ;
VAL_ 1984 moduleTemperature52_BMS01 255 "SNA" ;
VAL_ 1984 moduleTemperature53_BMS01 255 "SNA" ;
VAL_ 1984 moduleTemperature54_BMS01 255 "SNA" ;
VAL_ 1984 moduleTemperature55_BMS01 255 "SNA" ;
VAL_ 1984 moduleTemperature56_BMS01 255 "SNA" ;
VAL_ 1984 moduleTemperature57_BMS01 255 "SNA" ;
VAL_ 1984 moduleTemperature58_BMS01 255 "SNA" ;
VAL_ 1984 moduleTemperature59_BMS01 255 "SNA" ;
VAL_ 1984 moduleTemperature60_BMS01 255 "SNA" ;
VAL_ 1984 moduleTemperature61_BMS01 255 "SNA" ;
VAL_ 1984 moduleTemperature62_BMS01 255 "SNA" ;
VAL_ 1984 moduleTemperature63_BMS01 255 "SNA" ;
VAL_ 1984 moduleTemperature64_BMS01 255 "SNA" ;
VAL_ 1984 moduleTemperature65_BMS01 255 "SNA" ;
VAL_ 1984 moduleTemperature66_BMS01 255 "SNA" ;
VAL_ 1984 moduleTemperature67_BMS01 255 "SNA" ;
VAL_ 1984 moduleTemperature68_BMS01 255 "SNA" ;
VAL_ 1984 moduleTemperature69_BMS01 255 "SNA" ;
VAL_ 1984 moduleTemperature70_BMS01 255 "SNA" ;
VAL_ 1984 moduleTemperature71_BMS01 255 "SNA" ;
VAL_ 1984 moduleTemperature72_BMS01 255 "SNA" ;
VAL_ 1984 moduleTemperature73_BMS01 255 "SNA" ;
VAL_ 1984 moduleTemperature74_BMS01 255 "SNA" ;
VAL_ 1984 moduleTemperature75_BMS01 255 "SNA" ;
VAL_ 1984 moduleTemperature76_BMS01 255 "SNA" ;
VAL_ 1984 moduleTemperature77_BMS01 255 "SNA" ;
VAL_ 1984 moduleTemperature78_BMS01 255 "SNA" ;
VAL_ 1984 moduleTemperature79_BMS01 255 "SNA" ;
VAL_ 1984 moduleTemperature80_BMS01 255 "SNA" ;
VAL_ 1984 moduleTemperature81_BMS01 255 "SNA" ;
VAL_ 1984 moduleTemperature82_BMS01 255 "SNA" ;
VAL_ 1984 moduleTemperature83_BMS01 255 "SNA" ;
VAL_ 1984 moduleTemperature84_BMS01 255 "SNA" ;
VAL_ 1984 moduleTemperature85_BMS01 255 "SNA" ;
VAL_ 1984 moduleTemperature86_BMS01 255 "SNA" ;
VAL_ 1984 moduleTemperature87_BMS01 255 "SNA" ;
VAL_ 1984 moduleTemperature88_BMS01 255 "SNA" ;
VAL_ 1984 moduleTemperature89_BMS01 255 "SNA" ;
VAL_ 1984 moduleTemperature90_BMS01 255 "SNA" ;
VAL_ 1984 moduleTemperature91_BMS01 255 "SNA" ;
VAL_ 1984 moduleTemperature92_BMS01 255 "SNA" ;
VAL_ 1984 moduleTemperature93_BMS01 255 "SNA" ;
VAL_ 1984 moduleTemperature94_BMS01 255 "SNA" ;
VAL_ 1984 moduleTemperature95_BMS01 255 "SNA" ;
VAL_ 1984 moduleTemperature96_BMS01 255 "SNA" ;
VAL_ 1984 moduleTemperature97_BMS01 255 "SNA" ;
VAL_ 1984 moduleTemperature98_BMS01 255 "SNA" ;
VAL_ 1984 moduleTemperature99_BMS01 255 "SNA" ;
VAL_ 1984 moduleTemperature100_BMS01 255 "SNA" ;
VAL_ 897 DEM319_HV_DISABLE_DURING_S_BMS02 3 "DEM_INVALID" 2 "DEM_FAILED" 1 "DEM_PASSED" 0 "DEM_NOTTESTED" ;
VAL_ 897 DEM318_HV_ENABLE_IMPLAUSIB_BMS02 3 "DEM_INVALID" 2 "DEM_FAILED" 1 "DEM_PASSED" 0 "DEM_NOTTESTED" ;
VAL_ 897 DEM317_STRING_SUSPECT_OPEN_BMS02 3 "DEM_INVALID" 2 "DEM_FAILED" 1 "DEM_PASSED" 0 "DEM_NOTTESTED" ;
VAL_ 897 DEM316_UNEXPCTD_BMS_ON_CAN_BMS02 3 "DEM_INVALID" 2 "DEM_FAILED" 1 "DEM_PASSED" 0 "DEM_NOTTESTED" ;
VAL_ 897 DEM315_HV_WITHSTAND_TESTS__BMS02 3 "DEM_INVALID" 2 "DEM_FAILED" 1 "DEM_PASSED" 0 "DEM_NOTTESTED" ;
VAL_ 897 DEM314_OBC_PILOT_ERROR_BMS02 3 "DEM_INVALID" 2 "DEM_FAILED" 1 "DEM_PASSED" 0 "DEM_NOTTESTED" ;
VAL_ 897 DEM313_OBC_PILOT_HIGH_BMS02 3 "DEM_INVALID" 2 "DEM_FAILED" 1 "DEM_PASSED" 0 "DEM_NOTTESTED" ;
VAL_ 897 DEM312_OBC_PROXIMITY_ERROR_BMS02 3 "DEM_INVALID" 2 "DEM_FAILED" 1 "DEM_PASSED" 0 "DEM_NOTTESTED" ;
VAL_ 897 DEM311_CTRS_END_OF_LIFE_WA_BMS02 3 "DEM_INVALID" 2 "DEM_FAILED" 1 "DEM_PASSED" 0 "DEM_NOTTESTED" ;
VAL_ 897 DEM310_BMSMIA_STRNGMSTR_AL_BMS02 3 "DEM_INVALID" 2 "DEM_FAILED" 1 "DEM_PASSED" 0 "DEM_NOTTESTED" ;
VAL_ 897 DEM309_VOLTAGE_BRICKOV_WAR_BMS02 3 "DEM_INVALID" 2 "DEM_FAILED" 1 "DEM_PASSED" 0 "DEM_NOTTESTED" ;
VAL_ 897 DEM308_PRESSURE_FLT_BMS02 3 "DEM_INVALID" 2 "DEM_FAILED" 1 "DEM_PASSED" 0 "DEM_NOTTESTED" ;
VAL_ 897 DEM307_PRESSURE_MIA_BMS02 3 "DEM_INVALID" 2 "DEM_FAILED" 1 "DEM_PASSED" 0 "DEM_NOTTESTED" ;
VAL_ 897 DEM306_SW_VERSION_MISMATCH_BMS02 3 "DEM_INVALID" 2 "DEM_FAILED" 1 "DEM_PASSED" 0 "DEM_NOTTESTED" ;
VAL_ 897 DEM305_MODULET_OVERTEMP_WA_BMS02 3 "DEM_INVALID" 2 "DEM_FAILED" 1 "DEM_PASSED" 0 "DEM_NOTTESTED" ;
VAL_ 897 DEM304_PCHG_OPENCIRCUIT_IN_BMS02 3 "DEM_INVALID" 2 "DEM_FAILED" 1 "DEM_PASSED" 0 "DEM_NOTTESTED" ;
VAL_ 897 DEM303_MODULET_UNDERTEMP_W_BMS02 3 "DEM_INVALID" 2 "DEM_FAILED" 1 "DEM_PASSED" 0 "DEM_NOTTESTED" ;
VAL_ 897 DEM302_MODULET_UT_BMS02 3 "DEM_INVALID" 2 "DEM_FAILED" 1 "DEM_PASSED" 0 "DEM_NOTTESTED" ;
VAL_ 897 DEM301_FUSI_LOCK_BMS02 3 "DEM_INVALID" 2 "DEM_FAILED" 1 "DEM_PASSED" 0 "DEM_NOTTESTED" ;
VAL_ 897 DEM300_DEBUG_SM_DISABLED_BMS02 3 "DEM_INVALID" 2 "DEM_FAILED" 1 "DEM_PASSED" 0 "DEM_NOTTESTED" ;
VAL_ 897 DEM299_5V_SENSOR_SUPPLY_OU_BMS02 3 "DEM_INVALID" 2 "DEM_FAILED" 1 "DEM_PASSED" 0 "DEM_NOTTESTED" ;
VAL_ 897 DEM298_IMPL_DRIVE_REQUEST_BMS02 3 "DEM_INVALID" 2 "DEM_FAILED" 1 "DEM_PASSED" 0 "DEM_NOTTESTED" ;
VAL_ 897 DEM297_PCHG2_OPENCIRCUIT_BMS02 3 "DEM_INVALID" 2 "DEM_FAILED" 1 "DEM_PASSED" 0 "DEM_NOTTESTED" ;
VAL_ 897 DEM296_CTRSAUX_IMPLAUSIBLE_BMS02 3 "DEM_INVALID" 2 "DEM_FAILED" 1 "DEM_PASSED" 0 "DEM_NOTTESTED" ;
VAL_ 897 DEM295_CTRSAUX_LINKV_UNSAF_BMS02 3 "DEM_INVALID" 2 "DEM_FAILED" 1 "DEM_PASSED" 0 "DEM_NOTTESTED" ;
VAL_ 897 DEM294_CANRX_PT_EMERGENCY_BMS02 3 "DEM_INVALID" 2 "DEM_FAILED" 1 "DEM_PASSED" 0 "DEM_NOTTESTED" ;
VAL_ 897 DEM293_SBC_LDT_IMPLAUSIBLE_BMS02 3 "DEM_INVALID" 2 "DEM_FAILED" 1 "DEM_PASSED" 0 "DEM_NOTTESTED" ;
VAL_ 897 DEM292_NUM_EXPECTED_STRING_BMS02 3 "DEM_INVALID" 2 "DEM_FAILED" 1 "DEM_PASSED" 0 "DEM_NOTTESTED" ;
VAL_ 897 DEM291_NUM_EXPECTED_STRING_BMS02 3 "DEM_INVALID" 2 "DEM_FAILED" 1 "DEM_PASSED" 0 "DEM_NOTTESTED" ;
VAL_ 897 DEM290_CMB_ONBOARD_DEFECT_BMS02 3 "DEM_INVALID" 2 "DEM_FAILED" 1 "DEM_PASSED" 0 "DEM_NOTTESTED" ;
VAL_ 897 DEM289_TEMP_STATE_LATCHED_BMS02 3 "DEM_INVALID" 2 "DEM_FAILED" 1 "DEM_PASSED" 0 "DEM_NOTTESTED" ;
VAL_ 897 DEM288_CURR_STATE_LATCHED_BMS02 3 "DEM_INVALID" 2 "DEM_FAILED" 1 "DEM_PASSED" 0 "DEM_NOTTESTED" ;
VAL_ 961 balancingInDriveTimer_BMS02 65535 "SNA" ;
VAL_ 961 SOCRestPolarization_BMS02 255 "SNA" ;
VAL_ 961 CoolantSensorState_BMS02 3 "OIL_OK" 2 "SENSOR_FAILURE" 1 "WATER_DETECTED" 0 "SENSOR_CAN_MIA" ;
VAL_ 961 temperatureModelOffset_BMS02 255 "SNA" ;
VAL_ 961 SOHCMinBrickHighEst_BMS02 255 "SNA" ;
VAL_ 961 SOHCMaxBrickHighEst_BMS02 255 "SNA" ;
VAL_ 961 regenCurrOpLkyBktThrs1_BMS02 255 "SNA" ;
VAL_ 961 dischargeCurrOpLkyBktThrs1_BMS02 255 "SNA" ;
VAL_ 961 regenCurrentOpLoadValue_BMS02 255 "SNA" ;
VAL_ 961 dischargeCurrOpLoadValue_BMS02 255 "SNA" ;
VAL_ 961 minBrickVoltageLimit_BMS02 65535 "SNA" ;
VAL_ 961 currentModule3Integral_BMS02 65535 "SNA" ;
VAL_ 961 currentModule2Integral_BMS02 65535 "SNA" ;
VAL_ 961 currentModule1Integral_BMS02 65535 "SNA" ;
VAL_ 961 currentModuleMin_BMS02 65535 "SNA" ;
VAL_ 961 currentModuleMax_BMS02 65535 "SNA" ;
VAL_ 961 maxBrickVoltageSync_BMS02 65535 "SNA" ;
VAL_ 961 minBrickVoltageSync_BMS02 65535 "SNA" ;
VAL_ 961 SOHCMinBrickLowEst_BMS02 255 "SNA" ;
VAL_ 961 SOHCMaxBrickLowEst_BMS02 255 "SNA" ;
VAL_ 961 gradLimSOC_BMS02 65535 "SNA" ;
VAL_ 961 SOCRecalSlowOp_BMS02 255 "SNA" ;
VAL_ 961 SOHCMinIndex_BMS02 65535 "SNA" ;
VAL_ 961 SOHCMaxIndex_BMS02 65535 "SNA" ;
VAL_ 961 SOHRMinRegen_BMS02 255 "SNA" ;
VAL_ 961 SOHRMinDchg_BMS02 255 "SNA" ;
VAL_ 961 SOHRMeanRegen_BMS02 255 "SNA" ;
VAL_ 961 SOHRMeanDchg_BMS02 255 "SNA" ;
VAL_ 961 SOHRMaxRegen_BMS02 255 "SNA" ;
VAL_ 961 SOHRMaxDchg_BMS02 255 "SNA" ;
VAL_ 961 SOHCMin_BMS02 255 "SNA" ;
VAL_ 961 SOHCMean_BMS02 255 "SNA" ;
VAL_ 961 SOHCMax_BMS02 255 "SNA" ;
VAL_ 961 ppRegenCurrLimitPredShort_BMS02 255 "SNA" ;
VAL_ 961 ppRegenCurrLimitPredLong_BMS02 255 "SNA" ;
VAL_ 961 ppDchgCurrLimitPredShort_BMS02 255 "SNA" ;
VAL_ 961 ppDchgCurrLimitPredLong_BMS02 255 "SNA" ;
VAL_ 961 ppPolarizationV_BMS02 65535 "SNA" ;
VAL_ 961 SOCRecalMinOCVEst_BMS02 65535 "SNA" ;
VAL_ 961 SOCRecalMaxOCVEst_BMS02 65535 "SNA" ;
VAL_ 961 SOCRecalMinSOCUpp_BMS02 255 "SNA" ;
VAL_ 961 SOCRecalMinSOCLow_BMS02 255 "SNA" ;
VAL_ 961 SOCRecalMinSOC_BMS02 255 "SNA" ;
VAL_ 961 SOCRecalMaxSOCUpp_BMS02 255 "SNA" ;
VAL_ 961 SOCRecalMaxSOCLow_BMS02 255 "SNA" ;
VAL_ 961 SOCRecalMaxSOC_BMS02 255 "SNA" ;
VAL_ 961 ppNewtonStepsRegen_BMS02 7 "SNA" ;
VAL_ 961 ppNewtonStepsDchg_BMS02 7 "SNA" ;
VAL_ 961 ppNewtonRegenVRes_BMS02 255 "SNA" ;
VAL_ 961 ppNewtonDchgVRes_BMS02 255 "SNA" ;
VAL_ 961 ppMinModelAlphaTarget_BMS02 255 "SNA" ;
VAL_ 961 ppMaxModelAlphaTarget_BMS02 255 "SNA" ;
VAL_ 961 ppLearningTauRegen_BMS02 65535 "SNA" ;
VAL_ 961 ppLearningCriterionDyn_BMS02 255 "SNA" ;
VAL_ 961 ppLearningCriterionAbs_BMS02 255 "SNA" ;
VAL_ 961 ppLearningCriterionJoin_BMS02 255 "SNA" ;
VAL_ 961 currentRedundant_BMS02 65535 "SNA" ;
VAL_ 961 currentModule3_BMS02 65535 "SNA" ;
VAL_ 961 currentModule2_BMS02 65535 "SNA" ;
VAL_ 961 currentModule1_BMS02 65535 "SNA" ;
VAL_ 961 ppMeanDchgIntRes_BMS02 65535 "SNA" ;
VAL_ 961 ppMinModelLowpassV_BMS02 65535 "SNA" ;
VAL_ 961 ppMaxModelVoltageIndex_BMS02 65535 "SNA" ;
VAL_ 961 ppMaxModelLowpassV_BMS02 65535 "SNA" ;
VAL_ 961 ppLearningTauDischarge_BMS02 65535 "SNA" ;
VAL_ 961 ppMaxRegenAlpha_BMS02 255 "SNA" ;
VAL_ 961 ppMaxModelledV_BMS02 65535 "SNA" ;
VAL_ 961 ppMinDchgAlpha_BMS02 255 "SNA" ;
VAL_ 961 ppMinModelledV_BMS02 65535 "SNA" ;
VAL_ 961 debugSlowMpex2_BMS02 0 "S00" 1 "S01" 2 "S02" 3 "S03" 4 "S04" 5 "S05" 6 "S06" 7 "S07" 8 "S08" 9 "S09" 10 "S10" 11 "S11" 12 "S12" 13 "S13" 14 "S14" 15 "S15" 16 "S16" 17 "S17" 18 "S18" 19 "S19" 20 "S20" 21 "S21" 22 "S22" 23 "S23" 24 "S24" 25 "S25" ;
VAL_ 961 ppRegenCurrPredShort_BMS02 65535 "SNA" ;
VAL_ 961 ppDischgCurrPredLong_BMS02 65535 "SNA" ;
VAL_ 961 ppDischgCurrPredShort_BMS02 65535 "SNA" ;
VAL_ 961 ppRegenCurrPredLong_BMS02 65535 "SNA" ;
VAL_ 961 ppRegenVPredShort_BMS02 65535 "SNA" ;
VAL_ 961 ppDischgVPredShort_BMS02 65535 "SNA" ;
VAL_ 961 ppRegenVPredLong_BMS02 65535 "SNA" ;
VAL_ 961 ppDischgVPredLong_BMS02 65535 "SNA" ;
VAL_ 961 SOHDeltaSOCCoulomb_BMS02 65535 "SNA" ;
VAL_ 961 SOHAbsDeltaSOCCoulomb_BMS02 65535 "SNA" ;
VAL_ 961 SOHLastOCVRecalMinSOC_BMS02 255 "SNA" ;
VAL_ 961 SOHbalancingTimeMinSOH_BMS02 255 "SNA" ;
VAL_ 1793 chargerDCOutV_BMS02 65535 "SNA" ;
VAL_ 1793 chargerProximity_BMS02 255 "SNA" ;
VAL_ 1793 chargerPilot_BMS02 255 "SNA" ;
VAL_ 1793 chargerCurrAvail_BMS02 255 "SNA" ;
VAL_ 1793 chargerCtrOn_BMS02 1 "TRUE" 0 "FALSE" ;
VAL_ 1793 chargerOn_BMS02 1 "TRUE" 0 "FALSE" ;
VAL_ 1793 debugFastMpex2_BMS02 0 "F00" 1 "F01" 2 "F02" 3 "F03" 4 "F04" 5 "F05" 6 "F06" 7 "F07" 8 "F08" 9 "F09" 10 "F10" 11 "F11" 12 "F12" 13 "F13" 14 "F14" 15 "F15" ;
VAL_ 1793 posPackDbg_BMS02 65535 "SNA" ;
VAL_ 1793 negPackDbg_BMS02 65535 "SNA" ;
VAL_ 1793 packVoltageHVMeas_BMS02 65535 "SNA" ;
VAL_ 1857 SOHRecentChange_BMS02 255 "SNA" ;
VAL_ 1857 SOHConvergenceIndicator_BMS02 255 "SNA" ;
VAL_ 1857 SOHConvergenceCounter_BMS02 255 "SNA" ;
VAL_ 1857 SOHMinFiltered_BMS02 255 "SNA" ;
VAL_ 1857 medianModuleTempGrp2_BMS02 255 "SNA" ;
VAL_ 1857 medianModuleTempGrp1_BMS02 255 "SNA" ;
VAL_ 1857 coolantWarningtAlert_BMS02 3 "SNA" 2 "COOLANT_FLOOD_WARNING" 0 "COOLANT_NOWARNING" 1 "COOLANT_MOISTURE_WARNING" ;
VAL_ 1857 coolantFaultAlert_BMS02 3 "SNA" 2 "COOLANT_FLOOD_FAULT" 0 "COOLANT_NOFAULT" 1 "COOLANT_MOISTURE_FAULT" ;
VAL_ 1857 hvilShutdownStrategy_BMS02 4 "Strategy_4" 3 "Strategy_3" 2 "Strategy_2" 1 "Strategy_1" 0 "Strategy_0" ;
VAL_ 1857 J1939_nmState 3 "J1939_NM_INACTIVE" 2 "J1939_NM_ACTIVE" 1 "J1939_NM_STARTUP" 0 "J1939_NM_INIT" ;
VAL_ 1857 PrechargeXCapMin_BMS02 65535 "SNA" ;
VAL_ 1857 LimpHomeTimeOut_BMS02 65535 "SNA" ;
VAL_ 1857 hvWithstandTests_BMS02 255 "SNA" ;
VAL_ 1857 aux3prechargeState_BMS02 15 "CTR_PRCHG_NEG_OPEN" 13 "CTR_PRCHG_POS_WELD_CHECK" 12 "CTR_PRCHG_PRE_COND_CHECK" 11 "CTR_PRCHG_NEG2_WELD_CHECK" 10 "CTR_PRCHG_CLOSEMID" 9 "CTR_PRCHG_CLOSEAUX" 8 "CTR_PRCHG_FAILED" 7 "CTR_PRCHG_COMPLETE" 6 "CTR_PRCHG_CLOSE_POS" 5 "CTR_PRCHG_MONITOR_VOLTAGE" 4 "CTR_PRCHG_CLOSE_NEG" 3 "CTR_PRCHG_NEG_WELD_CHECK" 2 "CTR_PRCHG_CLOSE_RELAY" 1 "CTR_PRCHG_WELD_CHECK" 0 "CTR_PRCHG_OFF" ;
VAL_ 1857 aux2prechargeState_BMS02 15 "CTR_PRCHG_NEG_OPEN" 13 "CTR_PRCHG_POS_WELD_CHECK" 12 "CTR_PRCHG_PRE_COND_CHECK" 11 "CTR_PRCHG_NEG2_WELD_CHECK" 10 "CTR_PRCHG_CLOSEMID" 9 "CTR_PRCHG_CLOSEAUX" 8 "CTR_PRCHG_FAILED" 7 "CTR_PRCHG_COMPLETE" 6 "CTR_PRCHG_CLOSE_POS" 5 "CTR_PRCHG_MONITOR_VOLTAGE" 4 "CTR_PRCHG_CLOSE_NEG" 3 "CTR_PRCHG_NEG_WELD_CHECK" 2 "CTR_PRCHG_CLOSE_RELAY" 1 "CTR_PRCHG_WELD_CHECK" 0 "CTR_PRCHG_OFF" ;
VAL_ 1857 aux1prechargeState_BMS02 15 "CTR_PRCHG_NEG_OPEN" 13 "CTR_PRCHG_POS_WELD_CHECK" 12 "CTR_PRCHG_PRE_COND_CHECK" 11 "CTR_PRCHG_NEG2_WELD_CHECK" 10 "CTR_PRCHG_CLOSEMID" 9 "CTR_PRCHG_CLOSEAUX" 8 "CTR_PRCHG_FAILED" 7 "CTR_PRCHG_COMPLETE" 6 "CTR_PRCHG_CLOSE_POS" 5 "CTR_PRCHG_MONITOR_VOLTAGE" 4 "CTR_PRCHG_CLOSE_NEG" 3 "CTR_PRCHG_NEG_WELD_CHECK" 2 "CTR_PRCHG_CLOSE_RELAY" 1 "CTR_PRCHG_WELD_CHECK" 0 "CTR_PRCHG_OFF" ;
VAL_ 1857 auxLinkVoltage_BMS02 65535 "SNA" ;
VAL_ 1857 rangeRequestIgnoreVehicle 255 "NO_COMMAND" 1 "IGNORE" 0 "DO_NOT_IGNORE" ;
VAL_ 1857 rangeRequestEepromValue 255 "NO_COMMAND" 15 "RANGE_INVALID" 14 "RANGE_MAXIMUM" 13 "RANGE_MODESOH8" 12 "RANGE_MODESOH7" 11 "RANGE_MODESOH6" 10 "RANGE_MODESOH5" 9 "RANGE_MODESOH4" 8 "RANGE_MODESOH3" 7 "RANGE_MODESOH2" 6 "RANGE_MODESOH1" 5 "RANGE_MODE407" 4 "RANGE_MODE405" 3 "RANGE_MODE4175" 2 "RANGE_MODE415" 1 "RANGE_LIMITED" 0 "RANGE_SHIPPING" ;
VAL_ 1857 pressure2_BMS02 255 "SNA" ;
VAL_ 1857 calibration_version_BMS02 255 "SNA" ;
VAL_ 1857 currentLowTimer_BMS02 65535 "SNA" ;
VAL_ 1857 auxCntrrOpenUnderLoadCntr_BMS02 65535 "SNA" ;
VAL_ 1857 rabbitContactorState_BMS02 5 "FAILURE" 4 "CLOSE" 3 "EXT_ISO_TEST" 2 "AUX_CLOSE" 1 "INT_ISO_TEST" 0 "OPEN" ;
VAL_ 1857 analogIsenseSupplyCurr_BMS02 255 "SNA" ;
VAL_ 1857 pumpSpeedReqCoolPrfmc_BMS02 255 "SNA" ;
VAL_ 1857 microsarOs_IdleTask_OsCr0_BMS02 255 "SNA" ;
VAL_ 1857 microsarOs_BswTask_BMS02 255 "SNA" ;
VAL_ 1857 microsarOs_InitTask_BMS02 255 "SNA" ;
VAL_ 1857 microsarOs_ApplTask_1Hz_BMS02 255 "SNA" ;
VAL_ 1857 microsarOs_ApplTask_10Hz_BMS02 255 "SNA" ;
VAL_ 1857 microsarOs_ApplTask_100Hz_BMS02 255 "SNA" ;
VAL_ 1857 microsarOs_ApplLowTask_BMS02 255 "SNA" ;
VAL_ 1857 microsarOs_ApplLateInit_BMS02 255 "SNA" ;
VAL_ 1857 microsarOs_ApplHighTask_BMS02 255 "SNA" ;
VAL_ 1857 microsarOs_ApplEarlyInit_BMS02 255 "SNA" ;
VAL_ 1857 appTaskBSWMaxDuration_BMS02 255 "SNA" ;
VAL_ 1857 appTaskApplHighMaxDuration_BMS02 255 "SNA" ;
VAL_ 1857 appTask1HzMaxDuration_BMS02 255 "SNA" ;
VAL_ 1857 appTask100HzMaxDuration_BMS02 255 "SNA" ;
VAL_ 1857 appTask10HzMaxDuration_BMS02 255 "SNA" ;
VAL_ 1857 appTask100HzDuration_BMS02 255 "SNA" ;
VAL_ 1857 appTask10HzDuration_BMS02 255 "SNA" ;
VAL_ 1857 appTask1HzDuration_BMS02 255 "SNA" ;
VAL_ 1857 appTaskBSWDuration_BMS02 255 "SNA" ;
VAL_ 1857 appTaskApplHighDuration_BMS02 255 "SNA" ;
VAL_ 1857 iumprMaxRatioDTCId_BMS02 0 "SNA" ;
VAL_ 1857 iumprMaxRatio_BMS02 0 "SNA" ;
VAL_ 1857 iumprMinRatioDTCId_BMS02 0 "SNA" ;
VAL_ 1857 iumprMinRatio_BMS02 0 "SNA" ;
VAL_ 1857 fluidLvlCount_BMS02 255 "SNA" ;
VAL_ 1857 fluidLvlSensr2_BMS02 3 "FLUIDLEVEL_ERROR" 2 "FLUIDLEVEL_OIL" 1 "FLUIDLEVEL_AIR" 0 "FLUIDLEVEL_SNA" ;
VAL_ 1857 fluidLvlSensr1_BMS02 3 "FLUIDLEVEL_ERROR" 2 "FLUIDLEVEL_OIL" 1 "FLUIDLEVEL_AIR" 0 "FLUIDLEVEL_SNA" ;
VAL_ 1857 pumpSpeedReqVhcleSpeed_BMS02 255 "SNA" ;
VAL_ 1857 appTaskBSWCpuUsage_BMS02 255 "SNA" ;
VAL_ 1857 appTask200HzCpuUsage_BMS02 255 "SNA" ;
VAL_ 1857 pyroState_BMS02 7 "PYRO_FIRE" 6 "PYRO_DIAG_PASS" 5 "PYRO_DIAG_FAIL" 4 "PYRO_DIAG_LS_ON" 3 "PYRO_DIAG_OPEN" 2 "PYRO_DIAG_HS_ON" 1 "PYRO_DIAG_INIT" 0 "PYRO_INACTIVE" ;
VAL_ 1857 ecuSerialNrChar15_BMS02 90 "'Z'" 89 "'Y'" 88 "'X'" 87 "'W'" 86 "'V'" 85 "'U'" 84 "'T'" 83 "'S'" 82 "'R'" 81 "'Q'" 80 "'P'" 79 "'O'" 78 "'N'" 77 "'M'" 76 "'L'" 75 "'K'" 74 "'J'" 73 "'I'" 72 "'H'" 71 "'G'" 70 "'F'" 69 "'E'" 68 "'D'" 67 "'C'" 66 "'B'" 65 "'A'" 57 "'9'" 56 "'8'" 55 "'7'" 54 "'6'" 53 "'5'" 52 "'4'" 51 "'3'" 50 "'2'" 49 "'1'" 48 "'0'" ;
VAL_ 1857 ecuSerialNrChar14_BMS02 90 "'Z'" 89 "'Y'" 88 "'X'" 87 "'W'" 86 "'V'" 85 "'U'" 84 "'T'" 83 "'S'" 82 "'R'" 81 "'Q'" 80 "'P'" 79 "'O'" 78 "'N'" 77 "'M'" 76 "'L'" 75 "'K'" 74 "'J'" 73 "'I'" 72 "'H'" 71 "'G'" 70 "'F'" 69 "'E'" 68 "'D'" 67 "'C'" 66 "'B'" 65 "'A'" 57 "'9'" 56 "'8'" 55 "'7'" 54 "'6'" 53 "'5'" 52 "'4'" 51 "'3'" 50 "'2'" 49 "'1'" 48 "'0'" ;
VAL_ 1857 ecuSerialNrChar13_BMS02 90 "'Z'" 89 "'Y'" 88 "'X'" 87 "'W'" 86 "'V'" 85 "'U'" 84 "'T'" 83 "'S'" 82 "'R'" 81 "'Q'" 80 "'P'" 79 "'O'" 78 "'N'" 77 "'M'" 76 "'L'" 75 "'K'" 74 "'J'" 73 "'I'" 72 "'H'" 71 "'G'" 70 "'F'" 69 "'E'" 68 "'D'" 67 "'C'" 66 "'B'" 65 "'A'" 57 "'9'" 56 "'8'" 55 "'7'" 54 "'6'" 53 "'5'" 52 "'4'" 51 "'3'" 50 "'2'" 49 "'1'" 48 "'0'" ;
VAL_ 1857 ecuSerialNrChar12_BMS02 90 "'Z'" 89 "'Y'" 88 "'X'" 87 "'W'" 86 "'V'" 85 "'U'" 84 "'T'" 83 "'S'" 82 "'R'" 81 "'Q'" 80 "'P'" 79 "'O'" 78 "'N'" 77 "'M'" 76 "'L'" 75 "'K'" 74 "'J'" 73 "'I'" 72 "'H'" 71 "'G'" 70 "'F'" 69 "'E'" 68 "'D'" 67 "'C'" 66 "'B'" 65 "'A'" 57 "'9'" 56 "'8'" 55 "'7'" 54 "'6'" 53 "'5'" 52 "'4'" 51 "'3'" 50 "'2'" 49 "'1'" 48 "'0'" ;
VAL_ 1857 ecuSerialNrChar11_BMS02 90 "'Z'" 89 "'Y'" 88 "'X'" 87 "'W'" 86 "'V'" 85 "'U'" 84 "'T'" 83 "'S'" 82 "'R'" 81 "'Q'" 80 "'P'" 79 "'O'" 78 "'N'" 77 "'M'" 76 "'L'" 75 "'K'" 74 "'J'" 73 "'I'" 72 "'H'" 71 "'G'" 70 "'F'" 69 "'E'" 68 "'D'" 67 "'C'" 66 "'B'" 65 "'A'" 57 "'9'" 56 "'8'" 55 "'7'" 54 "'6'" 53 "'5'" 52 "'4'" 51 "'3'" 50 "'2'" 49 "'1'" 48 "'0'" ;
VAL_ 1857 ecuSerialNrChar10_BMS02 90 "'Z'" 89 "'Y'" 88 "'X'" 87 "'W'" 86 "'V'" 85 "'U'" 84 "'T'" 83 "'S'" 82 "'R'" 81 "'Q'" 80 "'P'" 79 "'O'" 78 "'N'" 77 "'M'" 76 "'L'" 75 "'K'" 74 "'J'" 73 "'I'" 72 "'H'" 71 "'G'" 70 "'F'" 69 "'E'" 68 "'D'" 67 "'C'" 66 "'B'" 65 "'A'" 57 "'9'" 56 "'8'" 55 "'7'" 54 "'6'" 53 "'5'" 52 "'4'" 51 "'3'" 50 "'2'" 49 "'1'" 48 "'0'" ;
VAL_ 1857 ecuSerialNrChar09_BMS02 90 "'Z'" 89 "'Y'" 88 "'X'" 87 "'W'" 86 "'V'" 85 "'U'" 84 "'T'" 83 "'S'" 82 "'R'" 81 "'Q'" 80 "'P'" 79 "'O'" 78 "'N'" 77 "'M'" 76 "'L'" 75 "'K'" 74 "'J'" 73 "'I'" 72 "'H'" 71 "'G'" 70 "'F'" 69 "'E'" 68 "'D'" 67 "'C'" 66 "'B'" 65 "'A'" 57 "'9'" 56 "'8'" 55 "'7'" 54 "'6'" 53 "'5'" 52 "'4'" 51 "'3'" 50 "'2'" 49 "'1'" 48 "'0'" ;
VAL_ 1857 ecuSerialNrChar08_BMS02 90 "'Z'" 89 "'Y'" 88 "'X'" 87 "'W'" 86 "'V'" 85 "'U'" 84 "'T'" 83 "'S'" 82 "'R'" 81 "'Q'" 80 "'P'" 79 "'O'" 78 "'N'" 77 "'M'" 76 "'L'" 75 "'K'" 74 "'J'" 73 "'I'" 72 "'H'" 71 "'G'" 70 "'F'" 69 "'E'" 68 "'D'" 67 "'C'" 66 "'B'" 65 "'A'" 57 "'9'" 56 "'8'" 55 "'7'" 54 "'6'" 53 "'5'" 52 "'4'" 51 "'3'" 50 "'2'" 49 "'1'" 48 "'0'" ;
VAL_ 1857 ecuSerialNrChar07_BMS02 90 "'Z'" 89 "'Y'" 88 "'X'" 87 "'W'" 86 "'V'" 85 "'U'" 84 "'T'" 83 "'S'" 82 "'R'" 81 "'Q'" 80 "'P'" 79 "'O'" 78 "'N'" 77 "'M'" 76 "'L'" 75 "'K'" 74 "'J'" 73 "'I'" 72 "'H'" 71 "'G'" 70 "'F'" 69 "'E'" 68 "'D'" 67 "'C'" 66 "'B'" 65 "'A'" 57 "'9'" 56 "'8'" 55 "'7'" 54 "'6'" 53 "'5'" 52 "'4'" 51 "'3'" 50 "'2'" 49 "'1'" 48 "'0'" ;
VAL_ 1857 ecuSerialNrChar06_BMS02 90 "'Z'" 89 "'Y'" 88 "'X'" 87 "'W'" 86 "'V'" 85 "'U'" 84 "'T'" 83 "'S'" 82 "'R'" 81 "'Q'" 80 "'P'" 79 "'O'" 78 "'N'" 77 "'M'" 76 "'L'" 75 "'K'" 74 "'J'" 73 "'I'" 72 "'H'" 71 "'G'" 70 "'F'" 69 "'E'" 68 "'D'" 67 "'C'" 66 "'B'" 65 "'A'" 57 "'9'" 56 "'8'" 55 "'7'" 54 "'6'" 53 "'5'" 52 "'4'" 51 "'3'" 50 "'2'" 49 "'1'" 48 "'0'" ;
VAL_ 1857 ecuSerialNrChar05_BMS02 90 "'Z'" 89 "'Y'" 88 "'X'" 87 "'W'" 86 "'V'" 85 "'U'" 84 "'T'" 83 "'S'" 82 "'R'" 81 "'Q'" 80 "'P'" 79 "'O'" 78 "'N'" 77 "'M'" 76 "'L'" 75 "'K'" 74 "'J'" 73 "'I'" 72 "'H'" 71 "'G'" 70 "'F'" 69 "'E'" 68 "'D'" 67 "'C'" 66 "'B'" 65 "'A'" 57 "'9'" 56 "'8'" 55 "'7'" 54 "'6'" 53 "'5'" 52 "'4'" 51 "'3'" 50 "'2'" 49 "'1'" 48 "'0'" ;
VAL_ 1857 analogGPIO1Current_BMS02 255 "SNA" ;
VAL_ 1857 analogGPIO1Volt_BMS02 255 "SNA" ;
VAL_ 1857 analogGPIO2Current_BMS02 255 "SNA" ;
VAL_ 1857 analogGPIO2Volt_BMS02 255 "SNA" ;
VAL_ 1857 pumpSpeedReqLoadValue_BMS02 255 "SNA" ;
VAL_ 1857 ssaRTMonth_BMS02 255 "SNA" ;
VAL_ 1857 ssaRTDay_BMS02 255 "SNA" ;
VAL_ 1857 appTask50HzStackUsage_BMS02 255 "SNA" ;
VAL_ 1857 OBDMILRequested_BMS02 3 "MIL_SNA" 1 "MIL_ON" 0 "MIL_OFF" ;
VAL_ 1857 OBDConfirmedDTCsCount_BMS02 255 "SNA" ;
VAL_ 1857 OBDFirstConfirmedDTC_BMS02 255 "SNA" ;
VAL_ 1857 OBDPermanentDTCCount_BMS02 255 "SNA" ;
VAL_ 1857 OBDFirstPermanentDTC_BMS02 255 "SNA" ;
VAL_ 1857 nmStartupReason_BMS02 15 "NM_STARTUP_INVALID" 7 "NM_STARTUP_TESTERPRESENT" 6 "NM_STARTUP_RQ" 5 "NM_STARTUP_CAN" 4 "NM_STARTUP_THERMALEVENT" 3 "NM_STARTUP_AUXCONTACTORS" 2 "NM_STARTUP_CONTACTORS" 1 "NM_STARTUP_KEY" 0 "NM_STARTUP_NOSTARTUP" ;
VAL_ 1857 contactorType_BMS02 15 "SNA" 1 "GV240_12V" 0 "CTR_TYPE_CALIBRATION (GV240_24V)" ;
VAL_ 1857 activeIsoTestDuration_BMS02 255 "SNA" ;
VAL_ 1857 balancingState_BMS02 6 "BALANCING_OFF_TEMP_SHUTDOWN" 5 "BALANCING_OFF_VOLTAGE_SHUTDOWN" 4 "BALANCING_ON_DCM_EEPROM" 3 "BALANCING_ON_DCM_BRICK" 2 "BALANCING_ON_DCM_PATTERN" 1 "BALANCING_ON_ME_APP" 0 "BALANCING_OFF" ;
VAL_ 1857 chronoStackWrCnt_BMS02 -1 "SNA" ;
VAL_ 1857 wakeReason_BMS02 6 "ECU_WAKEREASON_MCUWDG" 14 "ECU_WAKEREASON_INIT" 15 "ECU_WAKEREASON_UNKNOWN" 5 "ECU_WAKEREASON_AUTO" 4 "ECU_WAKEREASON_POR" 3 "ECU_WAKEREASON_CLOCK" 2 "ECU_WAKEREASON_PRESSURE" 1 "ECU_WAKEREASON_CAN" 0 "ECU_WAKEREASON_KEY" ;
VAL_ 1857 coolantOutletTemperature_BMS02 255 "SNA" ;
VAL_ 1857 coolantInletTemperature_BMS02 255 "SNA" ;
VAL_ 1857 variantCodingCount_BMS02 65535 "SNA" ;
VAL_ 1857 SWVersionCusApp_BMS02 -1 "SNA" ;
VAL_ 1857 contactorOpenRequest_BMS02 15 "CTR_OPEN_INVALID" 1 "CTR_OPEN_IMMEDIATE" 0 "CTR_OPEN_FAST " ;
VAL_ 1857 maxBrickVoltageChargeLimit_BMS02 65535 "SNA" ;
VAL_ 1857 desiccantTimer_BMS02 -1 "SNA" ;
VAL_ 1857 batSwitchOpenReason_BMS02 65535 "SNA" ;
VAL_ 1857 balancingTime_BMS02 65535 "SNA" ;
VAL_ 1857 ecuSerialNrChar01_BMS02 90 "'Z'" 89 "'Y'" 88 "'X'" 87 "'W'" 86 "'V'" 85 "'U'" 84 "'T'" 83 "'S'" 82 "'R'" 81 "'Q'" 80 "'P'" 79 "'O'" 78 "'N'" 77 "'M'" 76 "'L'" 75 "'K'" 74 "'J'" 73 "'I'" 72 "'H'" 71 "'G'" 70 "'F'" 69 "'E'" 68 "'D'" 67 "'C'" 66 "'B'" 65 "'A'" 57 "'9'" 56 "'8'" 55 "'7'" 54 "'6'" 53 "'5'" 52 "'4'" 51 "'3'" 50 "'2'" 49 "'1'" 48 "'0'" ;
VAL_ 1857 ecuSerialNrChar02_BMS02 90 "'Z'" 89 "'Y'" 88 "'X'" 87 "'W'" 86 "'V'" 85 "'U'" 84 "'T'" 83 "'S'" 82 "'R'" 81 "'Q'" 80 "'P'" 79 "'O'" 78 "'N'" 77 "'M'" 76 "'L'" 75 "'K'" 74 "'J'" 73 "'I'" 72 "'H'" 71 "'G'" 70 "'F'" 69 "'E'" 68 "'D'" 67 "'C'" 66 "'B'" 65 "'A'" 57 "'9'" 56 "'8'" 55 "'7'" 54 "'6'" 53 "'5'" 52 "'4'" 51 "'3'" 50 "'2'" 49 "'1'" 48 "'0'" ;
VAL_ 1857 ecuSerialNrChar03_BMS02 90 "'Z'" 89 "'Y'" 88 "'X'" 87 "'W'" 86 "'V'" 85 "'U'" 84 "'T'" 83 "'S'" 82 "'R'" 81 "'Q'" 80 "'P'" 79 "'O'" 78 "'N'" 77 "'M'" 76 "'L'" 75 "'K'" 74 "'J'" 73 "'I'" 72 "'H'" 71 "'G'" 70 "'F'" 69 "'E'" 68 "'D'" 67 "'C'" 66 "'B'" 65 "'A'" 57 "'9'" 56 "'8'" 55 "'7'" 54 "'6'" 53 "'5'" 52 "'4'" 51 "'3'" 50 "'2'" 49 "'1'" 48 "'0'" ;
VAL_ 1857 ecuSerialNrChar04_BMS02 90 "'Z'" 89 "'Y'" 88 "'X'" 87 "'W'" 86 "'V'" 85 "'U'" 84 "'T'" 83 "'S'" 82 "'R'" 81 "'Q'" 80 "'P'" 79 "'O'" 78 "'N'" 77 "'M'" 76 "'L'" 75 "'K'" 74 "'J'" 73 "'I'" 72 "'H'" 71 "'G'" 70 "'F'" 69 "'E'" 68 "'D'" 67 "'C'" 66 "'B'" 65 "'A'" 57 "'9'" 56 "'8'" 55 "'7'" 54 "'6'" 53 "'5'" 52 "'4'" 51 "'3'" 50 "'2'" 49 "'1'" 48 "'0'" ;
VAL_ 1857 ecuSerialNrChar16_BMS02 90 "'Z'" 89 "'Y'" 88 "'X'" 87 "'W'" 86 "'V'" 85 "'U'" 84 "'T'" 83 "'S'" 82 "'R'" 81 "'Q'" 80 "'P'" 79 "'O'" 78 "'N'" 77 "'M'" 76 "'L'" 75 "'K'" 74 "'J'" 73 "'I'" 72 "'H'" 71 "'G'" 70 "'F'" 69 "'E'" 68 "'D'" 67 "'C'" 66 "'B'" 65 "'A'" 57 "'9'" 56 "'8'" 55 "'7'" 54 "'6'" 53 "'5'" 52 "'4'" 51 "'3'" 50 "'2'" 49 "'1'" 48 "'0'" ;
VAL_ 1857 ecuSerialNrChar17_BMS02 90 "'Z'" 89 "'Y'" 88 "'X'" 87 "'W'" 86 "'V'" 85 "'U'" 84 "'T'" 83 "'S'" 82 "'R'" 81 "'Q'" 80 "'P'" 79 "'O'" 78 "'N'" 77 "'M'" 76 "'L'" 75 "'K'" 74 "'J'" 73 "'I'" 72 "'H'" 71 "'G'" 70 "'F'" 69 "'E'" 68 "'D'" 67 "'C'" 66 "'B'" 65 "'A'" 57 "'9'" 56 "'8'" 55 "'7'" 54 "'6'" 53 "'5'" 52 "'4'" 51 "'3'" 50 "'2'" 49 "'1'" 48 "'0'" ;
VAL_ 1857 ecuSerialNrChar18_BMS02 90 "'Z'" 89 "'Y'" 88 "'X'" 87 "'W'" 86 "'V'" 85 "'U'" 84 "'T'" 83 "'S'" 82 "'R'" 81 "'Q'" 80 "'P'" 79 "'O'" 78 "'N'" 77 "'M'" 76 "'L'" 75 "'K'" 74 "'J'" 73 "'I'" 72 "'H'" 71 "'G'" 70 "'F'" 69 "'E'" 68 "'D'" 67 "'C'" 66 "'B'" 65 "'A'" 57 "'9'" 56 "'8'" 55 "'7'" 54 "'6'" 53 "'5'" 52 "'4'" 51 "'3'" 50 "'2'" 49 "'1'" 48 "'0'" ;
VAL_ 1857 ecuSerialNrChar19_BMS02 90 "'Z'" 89 "'Y'" 88 "'X'" 87 "'W'" 86 "'V'" 85 "'U'" 84 "'T'" 83 "'S'" 82 "'R'" 81 "'Q'" 80 "'P'" 79 "'O'" 78 "'N'" 77 "'M'" 76 "'L'" 75 "'K'" 74 "'J'" 73 "'I'" 72 "'H'" 71 "'G'" 70 "'F'" 69 "'E'" 68 "'D'" 67 "'C'" 66 "'B'" 65 "'A'" 57 "'9'" 56 "'8'" 55 "'7'" 54 "'6'" 53 "'5'" 52 "'4'" 51 "'3'" 50 "'2'" 49 "'1'" 48 "'0'" ;
VAL_ 1857 maxModuleTemperature_BMS02 255 "SNA" ;
VAL_ 1857 meanModuleTemperature_BMS02 255 "SNA" ;
VAL_ 1857 minModuleTemperature_BMS02 255 "SNA" ;
VAL_ 1857 nmOperationalMode_BMS02 2 "NM_BUSSLEEP_MODE" 1 "NM_PREPAREBUSSLEEP_MODE" 0 "NM_NETWORK_MODE" ;
VAL_ 1857 nmNetworkMode_BMS02 2 "NM_MODE_READY_SLEEP" 1 "NM_MODE_NORMAL_OPERATION" 0 "NM_MODE_REPEAT_MESSAGE" ;
VAL_ 1857 nmNetworkState_BMS02 1 "NM_STATE_REQUESTED" 0 "NM_STATE_RELEASED" ;
VAL_ 1857 ecuState_BMS02 4 "ECU_SLEEPING" 3 "ECU_GOING_TO_SLEEP" 2 "ECU_AWAKE_CAN_ACTIVE" 1 "ECU_AWAKE_CAN_INACTIVE" 0 "ECU_INIT" ;
VAL_ 1857 SPIRxTxDiag_BMS02 3 "SPIRXTX_SLAVEREQUESTPACKAGE" 2 "SPIRXTX_CRC" 1 "SPIRXTX_WRONG_PACKETINDEX" 0 "SPIRXTX_ALL_OK" ;
VAL_ 1857 minSOC_BMS02 65535 "SNA" ;
VAL_ 1857 maxSOC_BMS02 65535 "SNA" ;
VAL_ 1857 appTaskMaxCpuUsage_BMS02 255 "SNA" ;
VAL_ 1857 appTaskCpuUsage_BMS02 255 "SNA" ;
VAL_ 1857 appTask50HzCpuUsage_BMS02 255 "SNA" ;
VAL_ 1857 appTask10HzStackUsage_BMS02 255 "SNA" ;
VAL_ 1857 appTask100HzCpuUsage_BMS02 255 "SNA" ;
VAL_ 1857 appTask10HzCpuUsage_BMS02 255 "SNA" ;
VAL_ 1857 appTask1HzCpuUsage_BMS02 255 "SNA" ;
VAL_ 1857 pumpSpeedReq_BMS02 255 "SNA" ;
VAL_ 1857 regenCurrPredBrickVOffset_BMS02 255 "SNA" ;
VAL_ 1857 dischgCurrPredBrickVOffset_BMS02 255 "SNA" ;
VAL_ 1857 PCANBusOffState_BMS02 3 "SNA" 2 "CAN_BUSOFF_PHASE2" 1 "CAN_BUSOFF_PHASE1" 0 "CAN_BUSOFF_NORMAL" ;
VAL_ 1857 SCANBusOffState_BMS02 3 "SNA" 2 "CAN_BUSOFF_PHASE2" 1 "CAN_BUSOFF_PHASE1" 0 "CAN_BUSOFF_NORMAL" ;
VAL_ 1857 PTCANBusOffState_BMS02 3 "SNA" 2 "CAN_BUSOFF_PHASE2" 1 "CAN_BUSOFF_PHASE1" 0 "CAN_BUSOFF_NORMAL" ;
VAL_ 1857 customerModelVsCellType_BMS02 0 "L" 1 "P" ;
VAL_ 1857 balancingVoltageTarget_BMS02 255 "VOLTAGEBASED_BALANCING_INACTIVE" ;
VAL_ 1857 analogAddr5_BMS02 255 "SNA" ;
VAL_ 1857 analogAddr0_BMS02 255 "SNA" ;
VAL_ 1857 analogAddr4_BMS02 255 "SNA" ;
VAL_ 1857 analogAddr3_BMS02 255 "SNA" ;
VAL_ 1857 analogAddr2_BMS02 255 "SNA" ;
VAL_ 1857 analogAddr1_BMS02 255 "SNA" ;
VAL_ 1857 debugSlowMpex1_BMS02 43 "S43" 42 "S42" 41 "S41" 40 "S40" 39 "S39" 38 "S38" 37 "S37" 36 "S36" 0 "S00" 1 "S01" 2 "S02" 3 "S03" 4 "S04" 5 "S05" 6 "S06" 7 "S07" 8 "S08" 9 "S09" 10 "S10" 11 "S11" 12 "S12" 13 "S13" 14 "S14" 15 "S15" 16 "S16" 17 "S17" 18 "S18" 19 "S19" 20 "S20" 21 "S21" 22 "S22" 23 "S23" 24 "S24" 25 "S25" 26 "S26" 27 "S27" 28 "S28" 29 "S29" 30 "S30" 31 "S31" 32 "S32" 33 "S33" 34 "S34" 35 "S35" ;
VAL_ 1857 analog3V3DSupply_BMS02 255 "SNA" ;
VAL_ 1857 pressure_BMS02 255 "SNA" ;
VAL_ 1857 analog3P3VA_BMS02 255 "SNA" ;
VAL_ 1857 analog5VA_BMS02 255 "SNA" ;
VAL_ 1857 analog5VD_BMS02 255 "SNA" ;
VAL_ 1857 analog5VSensorSupply_BMS02 255 "SNA" ;
VAL_ 1857 analog6V5_BMS02 255 "SNA" ;
VAL_ 1857 isolationResistanceIntern_BMS02 65535 "SNA" ;
VAL_ 1857 isolationResistanceExtern_BMS02 65535 "SNA" ;
VAL_ 1857 linkVoltage_BMS02 65535 "SNA" ;
VAL_ 1857 eepromWriteCyclesBasics_BMS02 65535 "SNA" ;
VAL_ 1857 eepromBlockIndex_BMS02 255 "SNA" ;
VAL_ 1857 regenCurrentOpLimit_BMS02 65535 "SNA" ;
VAL_ 1857 regenCurrentErrorLimit_BMS02 65535 "SNA" ;
VAL_ 1857 lifetime_BMS02 -1 "SNA" ;
VAL_ 1857 eepromReadTime_BMS02 255 "SNA" ;
VAL_ 1857 pumpSpeedReqMaxT_BMS02 65535 "SNA" ;
VAL_ 1857 pumpSpeedReqDeltaT_BMS02 65535 "SNA" ;
VAL_ 1857 packVoltageCMB_BMS02 65535 "SNA" ;
VAL_ 1857 ctrOffTime_BMS02 65535 "SNA" ;
VAL_ 1857 sleepTime_BMS02 65535 "SNA" ;
VAL_ 1857 SPIRxTxTimeAllPckts_BMS02 255 "SNA" ;
VAL_ 1857 isolationTestState_BMS02 3 "ISOLATION_DISABLED" 2 "ISOLATION_TEST_NEG" 1 "ISOLATION_TEST_POS" 0 "ISOLATION_OFF" ;
VAL_ 1729 SPIRxTxHeaderMux3Status_BMS02 1 "SPIRXTX_MUX_MISSING" 0 "SPIRXTX_MUX_GOOD" ;
VAL_ 1729 SPIRxTxHeaderMux2Status_BMS02 1 "SPIRXTX_MUX_MISSING" 0 "SPIRXTX_MUX_GOOD" ;
VAL_ 1729 SPIRxTxHeaderMux1Status_BMS02 1 "SPIRXTX_MUX_MISSING" 0 "SPIRXTX_MUX_GOOD" ;
VAL_ 1729 SPIRxTxHeaderMux0Status_BMS02 1 "SPIRXTX_MUX_MISSING" 0 "SPIRXTX_MUX_GOOD" ;
VAL_ 1729 activeIsoState_BMS02 4 "ISOACTV_COMPLETE" 3 "ISOACTV_TIMEOUT" 2 "ISOACTV_PENDING" 1 "ISOACTV_INIT" 0 "ISOACTV_OFF" ;
VAL_ 1729 activeIsoNegLink_BMS02 65535 "SNA" ;
VAL_ 1729 activeIsoPosLink_BMS02 65535 "SNA" ;
VAL_ 1729 activeIsoPosBuffer_BMS02 65535 "SNA" ;
VAL_ 1729 activeIsoNegBuffer_BMS02 65535 "SNA" ;
VAL_ 1729 activeIsoResRaw_BMS02 65535 "SNA" ;
VAL_ 1729 activeIsoResFilter_BMS02 65535 "SNA" ;
VAL_ 1729 contactorStateAux_BMS02 4 "CTR_INVALID" 3 "CTR_STRING_OPENING" 2 "CTR_STRING_ON" 1 "CTR_STRING_PRECHARGE" 0 "CTR_STRING_OFF" ;
VAL_ 1729 batSwitchOpenReqEssMstr_BMS02 3 "INVALID" 2 "IMMEDIATE_OPEN" 1 "FAST_OPEN" 0 "DO_NOT_OPEN" ;
VAL_ 1729 packShutdownTarget_BMS02 3 "BMS_INVALID" 1 "BMS_STRING_FAULT" 0 "BMS_STANDBY" ;
VAL_ 1729 weldedState_BMS02 3 "CTR_NEG1_WELDED" 2 "CTR_POS1_WELDED" 0 "CTR_NOTWELDED" 1 "CTR_BOTH_WELDED" ;
VAL_ 1729 contactorStateRq_BMS02 4 "CTR_INVALID" 3 "CTR_STRING_OPENING" 2 "CTR_STRING_ON" 1 "CTR_STRING_PRECHARGE" 0 "CTR_STRING_OFF" ;
VAL_ 1729 strMstrStrPrechgState_BMS02 7 "NOT_A_STRING_MASTER" 6 "STRING_PRCHG_NDEF2" 5 "STRING_PRCHG_NDEF1" 4 "STRING_PRCHG_FAULT" 3 "STRING_PRCHG_ON" 2 "STRING_PRCHG_ACTV" 1 "STRING_PRCHG_INIT" 0 "STRING_PRCHG_OFF" ;
VAL_ 1729 packShutdwnTmrQual_BMS02 0 "SHUTDOWN_ACTIVE" 1 "SHUTDOWN_INACTIVE" ;
VAL_ 1729 packStateRequest_BMS02 7 "STATE_INVALID" 6 "STATE_SYSTEM_FAULT" 5 "STATE_STRING_FAULT" 4 "STATE_LIMPHOME" 3 "STATE_ACCESSORY" 2 "STATE_CHARGE" 1 "STATE_DRIVE" 0 "STATE_STANDBY" ;
VAL_ 1729 packState_BMS02 15 "STATE_INVALID" 6 "STATE_ESS_FAULT" 5 "STATE_STRING_FAULT" 4 "STATE_LIMPHOME" 3 "STATE_ACCESSORY" 2 "STATE_CHARGE" 1 "STATE_DRIVE" 0 "STATE_STANDBY" ;
VAL_ 1729 SPIRxTxTimer_BMS02 255 "SNA" ;
VAL_ 1729 moduleTMinMaxMeanQual_BMS02 1 "QUAL_ERROR" 0 "QUAL_VALID" ;
VAL_ 1729 currentQual_BMS02 1 "QUAL_ERROR" 0 "QUAL_VALID" ;
VAL_ 1729 brickVMinMaxMeanQual_BMS02 1 "QUAL_ERROR" 0 "QUAL_VALID" ;
VAL_ 1729 debugFastMpex1_BMS02 0 "F00" 1 "F01" 2 "F02" 3 "F03" 4 "F04" 5 "F05" 6 "F06" 7 "F07" 8 "F08" 9 "F09" 10 "F10" 11 "F11" 12 "F12" 13 "F13" 14 "F14" 15 "F15" ;
VAL_ 1729 itemState_BMS02 3 "ITEM_INVALID" 2 "ITEM_EMERGENCY" 1 "ITEM_OFF" 0 "ITEM_ON" ;
VAL_ 1729 posLink_BMS02 255 "SNA" ;
VAL_ 1729 posPack_BMS02 255 "SNA" ;
VAL_ 1729 prechargeState_BMS02 14 "CTR_PRCHG_WAIT_CY_MATCH" 15 "CTR_PRCHG_NEG_OPEN" 13 "CTR_PRCHG_POS_WELD_CHECK" 12 "CTR_PRCHG_PRE_COND_CHECK" 11 "CTR_PRCHG_NEG2_WELD_CHECK" 10 "CTR_PRCHG_CLOSEMID" 9 "CTR_PRCHG_CLOSEAUX" 8 "CTR_PRCHG_FAILED" 7 "CTR_PRCHG_COMPLETE" 6 "CTR_PRCHG_CLOSE_POS" 5 "CTR_PRCHG_MONITOR_VOLTAGE" 4 "CTR_PRCHG_CLOSE_NEG" 3 "CTR_PRCHG_NEG_WELD_CHECK" 2 "CTR_PRCHG_CLOSE_RELAY" 1 "CTR_PRCHG_WELD_CHECK" 0 "CTR_PRCHG_OFF" ;
VAL_ 1729 contactorState_BMS02 4 "CTR_INVALID" 3 "CTR_STRING_OPENING" 2 "CTR_STRING_ON" 1 "CTR_STRING_PRECHARGE" 0 "CTR_STRING_OFF" ;
VAL_ 1537 DEMEventMultiplexor_BMS02 319 "DEM319_HV_DISABLE_DURING_S" 318 "DEM318_HV_ENABLE_IMPLAUSIB" 317 "DEM317_STRING_SUSPECT_OPEN" 316 "DEM316_UNEXPCTD_BMS_ON_CAN" 315 "DEM315_HV_WITHSTAND_TESTS_" 314 "DEM314_OBC_PILOT_ERROR" 313 "DEM313_OBC_PILOT_HIGH" 312 "DEM312_OBC_PROXIMITY_ERROR" 311 "DEM311_CTRS_END_OF_LIFE_WA" 310 "DEM310_BMSMIA_STRNGMSTR_AL" 309 "DEM309_VOLTAGE_BRICKOV_WAR" 308 "DEM308_PRESSURE_FLT" 307 "DEM307_PRESSURE_MIA" 306 "DEM306_SW_VERSION_MISMATCH" 305 "DEM305_MODULET_OVERTEMP_WA" 304 "DEM304_PCHG_OPENCIRCUIT_IN" 303 "DEM303_MODULET_UNDERTEMP_W" 302 "DEM302_MODULET_UT" 301 "DEM301_FUSI_LOCK" 300 "DEM300_DEBUG_SM_DISABLED" 299 "DEM299_5V_SENSOR_SUPPLY_OU" 298 "DEM298_IMPL_DRIVE_REQUEST" 297 "DEM297_PCHG2_OPENCIRCUIT" 296 "DEM296_CTRSAUX_IMPLAUSIBLE" 295 "DEM295_CTRSAUX_LINKV_UNSAF" 294 "DEM294_CANRX_PT_EMERGENCY" 293 "DEM293_SBC_LDT_IMPLAUSIBLE" 292 "DEM292_NUM_EXPECTED_STRING" 291 "DEM291_NUM_EXPECTED_STRING" 290 "DEM290_CMB_ONBOARD_DEFECT" 289 "DEM289_TEMP_STATE_LATCHED" 288 "DEM288_CURR_STATE_LATCHED" 1 "DEM001_POWERUP" 2 "DEM002_VOLTAGE_BRICK_OV" 3 "DEM003_VOLTAGE_BRICK_UV" 4 "DEM004_VOLTAGE_BRICK_SNA" 5 "DEM005_VOLTAGE_BRICK_IMBAL" 6 "DEM006_VOLTAGE_CAPCY_IMBAL" 7 "DEM007_MODULET_HIGH_DELTA" 8 "DEM008_VOLTAGE_PACK_UV" 9 "DEM009_VOLTAGE_PACK_OV" 10 "DEM010_VOLTAGE_PACK_PLAUSI" 11 "DEM011_VOLTAGE_PCKLINK_MIS" 12 "DEM012_VOLTAGE_BMS_SUPPLY" 13 "DEM013_ADC_ERROR" 14 "DEM014_MODULET_OT" 15 "DEM015_MODULET_SNA" 16 "DEM016_MODULET_LIMPHOME" 17 "DEM017_COOLING_SYS_LHOME" 18 "DEM018_HVIL_LIMPHOME" 19 "DEM019_HVIL_ESS_INHIBIT" 20 "DEM020_MODULET_CHANGE" 21 "DEM021_LG_MAVD_FAULT" 22 "DEM022_LG_RDV_FAULT" 23 "DEM023_BMS_ONBOARDT_SNA" 24 "DEM024_BMS_ONBOARDRH_OH" 25 "DEM025_BMS_ONBOARDRH_SNA" 26 "DEM026_CURRENT_OVERCHARGE" 27 "DEM027_CURRENT_OVERDISCHGE" 28 "DEM028_CURRENT_INVALID" 29 "DEM029_CURRENT_SHORTCIRCT" 30 "DEM030_CRASH_CAN_LATCH" 31 "DEM031_EEPROM_FAIL" 32 "DEM032_PCHG_PACKS_CONNECT" 33 "DEM033_PCHG_ILLEGAL_PRCHG" 34 "DEM034_PCHG_RELAY_FAIL" 35 "DEM035_PCHG_NEG_WELD" 36 "DEM036_PCHG_NEG_PULLIN" 37 "DEM037_PCHG_SHORTCIRCUIT" 38 "DEM038_PCHG_OPENCIRCUIT" 39 "DEM039_PCHG_TIMEOUT" 40 "DEM040_PCHG_FAILED" 41 "DEM041_HVIL_SHUTDOWN" 42 "DEM042_PCHG_POS_WELD" 43 "DEM043_HV_LOCK_TRANSPORT" 44 "DEM044_CTRS_END_OF_LIFE" 45 "DEM045_CTRS_CTRPWRV_HI" 46 "DEM046_CTRS_COILCURR_LOW" 47 "DEM047_CTRS_COILCURR_HIGH" 48 "DEM048_CTRS_CTRPWRV_LOW" 49 "DEM049_CHGE_ILLEGAL_DISCHG" 50 "DEM050_STARTUP_CONDITIONS" 51 "DEM051_VOLTAGE_BMS_SUPPLYH" 52 "DEM052_SAFETYSPI_FAIL" 53 "DEM053_WATCHDOG_ERRORPIN" 54 "DEM054_SAFESTATE_TRIGGERED" 55 "DEM055_DEBUG_CMND_ACTIVE" 56 "DEM056_CRASH_CAN" 57 "DEM057_ISO_EXT_STRAT_4" 58 "DEM058_ISO_EXT_RES_ERR" 59 "DEM059_ISO_EXT_RES_WARN" 60 "DEM060_ISO_INT_RES_ERR" 61 "DEM061_ISO_INT_RES_WARN" 62 "DEM062_EMERGENCY_OPERATION" 63 "DEM063_ENDOFDRIVE" 64 "DEM064_STRINGV_IMBALANCE" 65 "DEM065_STRING_FAULT" 66 "DEM066_ESS_FAULT" 67 "DEM067_ISO_EXT_STRAT_3" 68 "DEM068_MODULE_COUNT_INVALI" 69 "DEM069_PT_MIA" 70 "DEM070_BMSMIA_STRNGMSTR_01" 71 "DEM071_BMSMIA_STRNGMSTR_05" 72 "DEM072_BMSMIA_STRNGMSTR_09" 73 "DEM073_BMSMIA_STRNGMSTR_13" 74 "DEM074_BMSMIA_STRNGMSTR_17" 75 "DEM075_BMSMIA_STRNGMSTR_21" 76 "DEM076_BMSMIA_STRNGMSTR_25" 77 "DEM077_BMSMIA_STRNGMSTR_29" 78 "DEM078_BMSMIA_STRNGMSTR_33" 79 "DEM079_BMSMIA_STRNGMSTR_37" 80 "DEM080_BMSMIA_STRNGMSTR_41" 81 "DEM081_BMSMIA_STRNGMSTR_45" 82 "DEM082_BMSMIA_STRNGMSTR_49" 83 "DEM083_BMSMIA_STRNGMSTR_53" 84 "DEM084_BMSMIA_STRNGMSTR_57" 85 "DEM085_BMSMIA_STRNGMSTR_61" 86 "DEM086_ESSCURRENT_SHORT" 87 "DEM087_PT_MIA_SHUTDOWN" 88 "DEM088_OUTLET_NTC_HI" 89 "DEM089_OUTLET_NTC_LO" 90 "DEM090_BMSMIA_ESSMASTER" 91 "DEM091_PCHG_RES_OVERHEAT" 92 "DEM092_BMSMIA_STRNGSLAVE_0" 93 "DEM093_BMSMIA_STRNGSLAVE_1" 94 "DEM094_BMSMIA_STRNGSLAVE_2" 95 "DEM095_BMSMIA_STRNGSLAVE_3" 96 "DEM096_SC_STATE_SELFTEST" 97 "DEM097_SC_STATE_TEMP" 98 "DEM098_SC_STATE_VOLTAGE" 99 "DEM099_SC_STATE_HVIL" 100 "DEM100_SC_STATE_CONTACTORS" 101 "DEM101_SC_STATE_CURRENT" 102 "DEM102_SC_STATE_CANRX" 103 "DEM103_SC_STATE_CRASH" 104 "DEM104_SC_STATE_CCTRL" 105 "DEM105_SC_STATE_CANTX" 106 "DEM106_SC_STATE_THERMALEVT" 107 "DEM107_SC_STATE_COOLANT" 108 "DEM108_SC_SELFTEST_SFTY_UC" 109 "DEM109_SC_TEMP_HIGH" 110 "DEM110_SC_TEMP_NTC_OPEN" 111 "DEM111_SC_TEMP_NTC_SHORT" 112 "DEM112_CMB_DISCONNECTED" 113 "DEM113_CMB_DEFECT" 114 "DEM114_CMB_COMMERROR" 115 "DEM115_SC_CURR_HALL_PWR_LO" 116 "DEM116_SC_CURR_HALL_VHIGH" 117 "DEM117_SC_CURR_HALL_ADC" 118 "DEM118_SC_CURR_HALL_VLOW" 119 "DEM119_SC_CURR_ISENSE_PWR" 120 "DEM120_SC_CURR_ISENSE1_MIA" 121 "DEM121_SC_CURR_ISENSE2_MIA" 122 "DEM122_SC_CURR_ISENSE3_MIA" 123 "DEM123_SC_CURR_ISENSE4_MIA" 124 "DEM124_SC_CURR_ISENSE5_MIA" 125 "DEM125_SC_CURR_ISENSE1_FLT" 126 "DEM126_SC_CURR_ISENSE2_FLT" 127 "DEM127_SC_CURR_ISENSE3_FLT" 128 "DEM128_SC_CURR_ISENSE4_FLT" 129 "DEM129_SC_CURR_ISENSE5_FLT" 130 "DEM130_SC_CURR_OFFSET" 131 "DEM131_SC_CURR_PLAUSI" 132 "DEM132_SC_CURR_CHARGE_HIGH" 133 "DEM133_SC_CURR_DSCHAR_HIGH" 134 "DEM134_SC_V_CMB_SUMOFCELL" 135 "DEM135_SC_V_SENSE_OPENWIRE" 136 "DEM136_SC_V_CMB_DRV_FROZEN" 137 "DEM137_SC_V_PACK_PLAUSI" 138 "DEM138_SC_HVIL_HW_FLT" 139 "DEM139_SC_HVIL_OPEN" 140 "DEM140_SC_HVIL_TO_SUP" 141 "DEM141_SC_HVIL_TO_CHAS" 142 "DEM142_SC_HVIL_R_HIGH" 143 "DEM143_SC_HVIL_SHORT" 144 "DEM144_SC_CN_ISO_FAIL" 145 "DEM145_HVIL_SYS" 146 "DEM146_SC_CN_POS1_WELDED" 147 "DEM147_SC_CN_NEG1_WELDED" 148 "DEM148_SC_CN_POS2_WELDED" 149 "DEM149_SC_CN_NEG2_WELDED" 150 "DEM150_SC_CN_POS3_WELDED" 151 "DEM151_SC_CN_NEG3_WELDED" 152 "DEM152_SC_CN_HIGH_CY" 153 "DEM153_SC_CN_ISOANDPOTWELD" 154 "DEM154_SC_TEMP_PLAUSI" 155 "DEM155_SC_CURR_HALL_PWR_HI" 156 "DEM156_SC_PYRO_TRIGGERED" 157 "DEM157_SC_PYRO_OPEN" 158 "DEM158_AUX_CTRS_END_OF_LIF" 159 "DEM159_SC_CANRX_PT_MIA" 160 "DEM160_SC_CANRX_PT_CRCALIV" 161 "DEM161_SC_CANRX_LIN_SHUTDN" 162 "DEM162_SC_CANRX_LIN_MIA" 163 "DEM163_SC_CRASH1" 164 "DEM164_SC_CRASH2" 165 "DEM165_SC_CRASHCAN" 166 "DEM166_SC_CCTRL_SELFTEST" 167 "DEM167_SC_CCTRL_DRIVER_FAU" 168 "DEM168_SC_CCTRL_HISIDESTCL" 169 "DEM169_SC_CCTRL_HISIDESTOP" 170 "DEM170_SC_CCTRL_LOSIDESTCL" 171 "DEM171_SC_CCTRL_HVCNDITION" 172 "DEM172_SC_CCTRL_POS1_OPN" 173 "DEM173_SC_CCTRL_POS2_OPN" 174 "DEM174_SC_CCTRL_POS3_OPN" 175 "DEM175_SC_CCTRL_NEG1_OPN" 176 "DEM176_SC_CCTRL_NEG2_OPN" 177 "DEM177_SC_CCTRL_PRE2_OPN" 178 "DEM178_SC_CCTRL_PRE1_OPN" 179 "DEM179_SC_CCTRL_LOSIDESTOP" 180 "DEM180_SC_CCTRL_UNEXPECTED" 181 "DEM181_SC_V_OUT_OF_RANGE" 182 "DEM182_SC_V_LATCHED_UVOV" 183 "DEM183_ISO_EXT_STRAT_2" 184 "DEM184_SC_CANTX_CTRS" 185 "DEM185_SC_CANTX_HVIL" 186 "DEM186_SC_CANTX_ISOL" 187 "DEM187_SC_SBC_WATCHDOG" 188 "DEM188_SC_SBC_FAULT" 189 "DEM189_SC_WATCHDOG" 190 "DEM190_SC_SELFTEST_RAM" 191 "DEM191_SC_SELFTEST_FLASH" 192 "DEM192_CMB_ONBOARDRH_OH" 193 "DEM193_CMB_ONBOARDRH_SNA" 194 "DEM194_CMB_ONBOARDT_OT" 195 "DEM195_CMB_ONBOARDT_CHANGE" 196 "DEM196_PRESSURE_CHANGE" 197 "DEM197_PRESSURE_OVER" 198 "DEM198_PRESSURE_UNDER" 199 "DEM199_PRESSURE_INVALID" 200 "DEM200_THERMAL_EVENT" 201 "DEM201_CMB_ONBOARDT_SNA" 202 "DEM202_REPLACE_DESICCANT" 203 "DEM203_COOLANT_FLOOD_FAULT" 204 "DEM204_LOW_BRICKCAPACITY" 205 "DEM205_BMS_ONBOARDT_OT" 206 "DEM206_HUMIDITY_CHANGE" 207 "DEM207_ISENSE_SUPPLY_CURR" 208 "DEM208_SOC_LOW" 209 "DEM209_SOC_TOOLOW" 210 "DEM210_SOC_TOOHIGH" 211 "DEM211_BALANCING_REQUIRED" 212 "DEM212_DEEP_DISCHARGE" 213 "DEM213_CAN1_BUS_OFF" 214 "DEM214_CAN2_BUS_OFF" 215 "DEM215_CAN3_BUS_OFF" 216 "DEM216_OUTLET_NTC_RATNAL" 217 "DEM217_FUSE_PACK" 218 "DEM218_FUSE_B_OPEN" 219 "DEM219_FUSE_C_OPEN" 220 "DEM220_FUSE_D_OPEN" 221 "DEM221_FUSE_E_OPEN" 222 "DEM222_PUMP_DRY_RUN" 223 "DEM223_PUMP_PERFORMANCE" 224 "DEM224_PUMP_LIN_FAILURE" 225 "DEM225_PUMP_SUPPLY_VOLTAGE" 226 "DEM226_PUMP_RECOVERY_FAIL" 227 "DEM227_CTR_POS_OPENED" 228 "DEM228_CTR_NEG_OPENED" 229 "DEM229_STRSET_SLAVE1_FAULT" 230 "DEM230_STRSET_SLAVE2_FAULT" 231 "DEM231_CTRSAUX_CLFAIL_HVON" 232 "DEM232_CTRSAUX_CLFAIL_VDIF" 233 "DEM233_CTRSAUX_POS1_OPENED" 234 "DEM234_CTRSAUX_NEG1_OPENED" 235 "DEM235_CTRSAUX_POS1_WELDED" 236 "DEM236_CTRSAUX_NEG1_WELDED" 237 "DEM237_CTRSAUX_POS1_PULLIN" 238 "DEM238_CTRSAUX_NEG1_PULLIN" 239 "DEM239_INLET_NTC_RATNAL" 240 "DEM240_INLET_NTC_HI" 241 "DEM241_INLET_NTC_LO" 242 "DEM242_VOLTAGE_LINK2_RATNA" 243 "DEM243_VOLTAGE_LINK2_HI" 244 "DEM244_VOLTAGE_LINK2_LO" 245 "DEM245_CMB_ONBOARD_IMPOSSI" 246 "DEM246_VOLTAGE_LINK1_HI" 247 "DEM247_VOLTAGE_LINK1_LO" 248 "DEM248_NTC_SUPPLY_LO" 249 "DEM249_NTC_SUPPLY_HI" 250 "DEM250_VOLTAGE_LINK3_RATNA" 251 "DEM251_VOLTAGE_LINK3_HI" 252 "DEM252_VOLTAGE_LINK3_LO" 253 "DEM253_BALANCING_STUCK" 254 "DEM254_ARM_EXCEPTION" 255 "DEM255_ERROR_HOOKS" 256 "DEM256_XCP_CAL_CHANGE" 257 "DEM257_XCP_CAL_PERM_CHANGE" 258 "DEM258_TASK_TIME_OVERFLOW" 259 "DEM259_ISO_CIRCUIT" 260 "DEM260_COOLANT_MOIST_FAULT" 261 "DEM261_COOLANT_FLOOD_WARN" 262 "DEM262_COOLANT_MOIST_WARN" 263 "DEM263_MODULET_IMPLAUSIBLE" 264 "DEM264_REQUEST_ON_WITH_HV_" 265 "DEM265_CSERS_PCODE" 266 "DEM266_PRELIM_CNTR_CL_FAIL" 267 "DEM267_FLUIDLVL_LOW" 268 "DEM268_FLUIDLVL_FAILURE" 269 "DEM269_SC_COOLANT_CONTAM" 270 "DEM270_SC_COOLANT_MIA" 271 "DEM271_PRESSURE_VHI" 272 "DEM272_PRESSURE_VLO" 273 "DEM273_SC_COOLANT_FAIL" 274 "DEM274_CTRSAUX_POS2_OPENED" 275 "DEM275_CTRSAUX_POS3_OPENED" 276 "DEM276_CTRSAUX_POS2_WELDED" 277 "DEM277_CTRSAUX_POS3_WELDED" 278 "DEM278_CTRSAUX_POS2_PULLIN" 279 "DEM279_CTRSAUX_POS3_PULLIN" 280 "DEM280_CMB_HUMIDITY_TEMP_C" 281 "DEM281_THERMAL_EVENT_CMB_R" 282 "DEM282_CUS_BRICKOV" 283 "DEM283_CUS_BRICKUV" 284 "DEM284_CUS_OVERCHRG" 285 "DEM285_CUS_OVERDCHRG" 286 "DEM286_CUS_CURRENT_CHG" 287 "DEM287_CUS_CURRENT_DCHG" ;
VAL_ 1025 DEM001_POWERUP_BMS02 3 "DEM_INVALID" 2 "DEM_FAILED" 1 "DEM_PASSED" 0 "DEM_NOTTESTED" ;
VAL_ 1025 DEM002_VOLTAGE_BRICK_OV_BMS02 3 "DEM_INVALID" 2 "DEM_FAILED" 1 "DEM_PASSED" 0 "DEM_NOTTESTED" ;
VAL_ 1025 DEM003_VOLTAGE_BRICK_UV_BMS02 3 "DEM_INVALID" 2 "DEM_FAILED" 1 "DEM_PASSED" 0 "DEM_NOTTESTED" ;
VAL_ 1025 DEM004_VOLTAGE_BRICK_SNA_BMS02 3 "DEM_INVALID" 2 "DEM_FAILED" 1 "DEM_PASSED" 0 "DEM_NOTTESTED" ;
VAL_ 1025 DEM005_VOLTAGE_BRICK_IMBAL_BMS02 3 "DEM_INVALID" 2 "DEM_FAILED" 1 "DEM_PASSED" 0 "DEM_NOTTESTED" ;
VAL_ 1025 DEM006_VOLTAGE_CAPCY_IMBAL_BMS02 3 "DEM_INVALID" 2 "DEM_FAILED" 1 "DEM_PASSED" 0 "DEM_NOTTESTED" ;
VAL_ 1025 DEM007_MODULET_HIGH_DELTA_BMS02 3 "DEM_INVALID" 2 "DEM_FAILED" 1 "DEM_PASSED" 0 "DEM_NOTTESTED" ;
VAL_ 1025 DEM008_VOLTAGE_PACK_UV_BMS02 3 "DEM_INVALID" 2 "DEM_FAILED" 1 "DEM_PASSED" 0 "DEM_NOTTESTED" ;
VAL_ 1025 DEM009_VOLTAGE_PACK_OV_BMS02 3 "DEM_INVALID" 2 "DEM_FAILED" 1 "DEM_PASSED" 0 "DEM_NOTTESTED" ;
VAL_ 1025 DEM010_VOLTAGE_PACK_PLAUSI_BMS02 3 "DEM_INVALID" 2 "DEM_FAILED" 1 "DEM_PASSED" 0 "DEM_NOTTESTED" ;
VAL_ 1025 DEM011_VOLTAGE_PCKLINK_MIS_BMS02 3 "DEM_INVALID" 2 "DEM_FAILED" 1 "DEM_PASSED" 0 "DEM_NOTTESTED" ;
VAL_ 1025 DEM012_VOLTAGE_BMS_SUPPLY_BMS02 3 "DEM_INVALID" 2 "DEM_FAILED" 1 "DEM_PASSED" 0 "DEM_NOTTESTED" ;
VAL_ 1025 DEM013_ADC_ERROR_BMS02 3 "DEM_INVALID" 2 "DEM_FAILED" 1 "DEM_PASSED" 0 "DEM_NOTTESTED" ;
VAL_ 1025 DEM014_MODULET_OT_BMS02 3 "DEM_INVALID" 2 "DEM_FAILED" 1 "DEM_PASSED" 0 "DEM_NOTTESTED" ;
VAL_ 1025 DEM015_MODULET_SNA_BMS02 3 "DEM_INVALID" 2 "DEM_FAILED" 1 "DEM_PASSED" 0 "DEM_NOTTESTED" ;
VAL_ 1025 DEM016_MODULET_LIMPHOME_BMS02 3 "DEM_INVALID" 2 "DEM_FAILED" 1 "DEM_PASSED" 0 "DEM_NOTTESTED" ;
VAL_ 1025 DEM017_COOLING_SYS_LHOME_BMS02 3 "DEM_INVALID" 2 "DEM_FAILED" 1 "DEM_PASSED" 0 "DEM_NOTTESTED" ;
VAL_ 1025 DEM018_HVIL_LIMPHOME_BMS02 3 "DEM_INVALID" 2 "DEM_FAILED" 1 "DEM_PASSED" 0 "DEM_NOTTESTED" ;
VAL_ 1025 DEM019_HVIL_ESS_INHIBIT_BMS02 3 "DEM_INVALID" 2 "DEM_FAILED" 1 "DEM_PASSED" 0 "DEM_NOTTESTED" ;
VAL_ 1025 DEM020_MODULET_CHANGE_BMS02 3 "DEM_INVALID" 2 "DEM_FAILED" 1 "DEM_PASSED" 0 "DEM_NOTTESTED" ;
VAL_ 1025 DEM021_LG_MAVD_FAULT_BMS02 3 "DEM_INVALID" 2 "DEM_FAILED" 1 "DEM_PASSED" 0 "DEM_NOTTESTED" ;
VAL_ 1025 DEM022_LG_RDV_FAULT_BMS02 3 "DEM_INVALID" 2 "DEM_FAILED" 1 "DEM_PASSED" 0 "DEM_NOTTESTED" ;
VAL_ 1025 DEM023_BMS_ONBOARDT_SNA_BMS02 3 "DEM_INVALID" 2 "DEM_FAILED" 1 "DEM_PASSED" 0 "DEM_NOTTESTED" ;
VAL_ 1025 DEM024_BMS_ONBOARDRH_OH_BMS02 3 "DEM_INVALID" 2 "DEM_FAILED" 1 "DEM_PASSED" 0 "DEM_NOTTESTED" ;
VAL_ 1025 DEM025_BMS_ONBOARDRH_SNA_BMS02 3 "DEM_INVALID" 2 "DEM_FAILED" 1 "DEM_PASSED" 0 "DEM_NOTTESTED" ;
VAL_ 1025 DEM026_CURRENT_OVERCHARGE_BMS02 3 "DEM_INVALID" 2 "DEM_FAILED" 1 "DEM_PASSED" 0 "DEM_NOTTESTED" ;
VAL_ 1025 DEM027_CURRENT_OVERDISCHGE_BMS02 3 "DEM_INVALID" 2 "DEM_FAILED" 1 "DEM_PASSED" 0 "DEM_NOTTESTED" ;
VAL_ 1025 DEM028_CURRENT_INVALID_BMS02 3 "DEM_INVALID" 2 "DEM_FAILED" 1 "DEM_PASSED" 0 "DEM_NOTTESTED" ;
VAL_ 1025 DEM029_CURRENT_SHORTCIRCT_BMS02 3 "DEM_INVALID" 2 "DEM_FAILED" 1 "DEM_PASSED" 0 "DEM_NOTTESTED" ;
VAL_ 1025 DEM030_CRASH_CAN_LATCH_BMS02 3 "DEM_INVALID" 2 "DEM_FAILED" 1 "DEM_PASSED" 0 "DEM_NOTTESTED" ;
VAL_ 1025 DEM031_EEPROM_FAIL_BMS02 3 "DEM_INVALID" 2 "DEM_FAILED" 1 "DEM_PASSED" 0 "DEM_NOTTESTED" ;
VAL_ 1089 DEM032_PCHG_PACKS_CONNECT_BMS02 3 "DEM_INVALID" 2 "DEM_FAILED" 1 "DEM_PASSED" 0 "DEM_NOTTESTED" ;
VAL_ 1089 DEM033_PCHG_ILLEGAL_PRCHG_BMS02 3 "DEM_INVALID" 2 "DEM_FAILED" 1 "DEM_PASSED" 0 "DEM_NOTTESTED" ;
VAL_ 1089 DEM034_PCHG_RELAY_FAIL_BMS02 3 "DEM_INVALID" 2 "DEM_FAILED" 1 "DEM_PASSED" 0 "DEM_NOTTESTED" ;
VAL_ 1089 DEM035_PCHG_NEG_WELD_BMS02 3 "DEM_INVALID" 2 "DEM_FAILED" 1 "DEM_PASSED" 0 "DEM_NOTTESTED" ;
VAL_ 1089 DEM036_PCHG_NEG_PULLIN_BMS02 3 "DEM_INVALID" 2 "DEM_FAILED" 1 "DEM_PASSED" 0 "DEM_NOTTESTED" ;
VAL_ 1089 DEM037_PCHG_SHORTCIRCUIT_BMS02 3 "DEM_INVALID" 2 "DEM_FAILED" 1 "DEM_PASSED" 0 "DEM_NOTTESTED" ;
VAL_ 1089 DEM038_PCHG_OPENCIRCUIT_BMS02 3 "DEM_INVALID" 2 "DEM_FAILED" 1 "DEM_PASSED" 0 "DEM_NOTTESTED" ;
VAL_ 1089 DEM039_PCHG_TIMEOUT_BMS02 3 "DEM_INVALID" 2 "DEM_FAILED" 1 "DEM_PASSED" 0 "DEM_NOTTESTED" ;
VAL_ 1089 DEM040_PCHG_FAILED_BMS02 3 "DEM_INVALID" 2 "DEM_FAILED" 1 "DEM_PASSED" 0 "DEM_NOTTESTED" ;
VAL_ 1089 DEM041_HVIL_SHUTDOWN_BMS02 3 "DEM_INVALID" 2 "DEM_FAILED" 1 "DEM_PASSED" 0 "DEM_NOTTESTED" ;
VAL_ 1089 DEM042_PCHG_POS_WELD_BMS02 3 "DEM_INVALID" 2 "DEM_FAILED" 1 "DEM_PASSED" 0 "DEM_NOTTESTED" ;
VAL_ 1089 DEM043_HV_LOCK_TRANSPORT_BMS02 3 "DEM_INVALID" 2 "DEM_FAILED" 1 "DEM_PASSED" 0 "DEM_NOTTESTED" ;
VAL_ 1089 DEM044_CTRS_END_OF_LIFE_BMS02 3 "DEM_INVALID" 2 "DEM_FAILED" 1 "DEM_PASSED" 0 "DEM_NOTTESTED" ;
VAL_ 1089 DEM045_CTRS_CTRPWRV_HI_BMS02 3 "DEM_INVALID" 2 "DEM_FAILED" 1 "DEM_PASSED" 0 "DEM_NOTTESTED" ;
VAL_ 1089 DEM046_CTRS_COILCURR_LOW_BMS02 3 "DEM_INVALID" 2 "DEM_FAILED" 1 "DEM_PASSED" 0 "DEM_NOTTESTED" ;
VAL_ 1089 DEM047_CTRS_COILCURR_HIGH_BMS02 3 "DEM_INVALID" 2 "DEM_FAILED" 1 "DEM_PASSED" 0 "DEM_NOTTESTED" ;
VAL_ 1089 DEM048_CTRS_CTRPWRV_LOW_BMS02 3 "DEM_INVALID" 2 "DEM_FAILED" 1 "DEM_PASSED" 0 "DEM_NOTTESTED" ;
VAL_ 1089 DEM049_CHGE_ILLEGAL_DISCHG_BMS02 3 "DEM_INVALID" 2 "DEM_FAILED" 1 "DEM_PASSED" 0 "DEM_NOTTESTED" ;
VAL_ 1089 DEM050_STARTUP_CONDITIONS_BMS02 3 "DEM_INVALID" 2 "DEM_FAILED" 1 "DEM_PASSED" 0 "DEM_NOTTESTED" ;
VAL_ 1089 DEM051_VOLTAGE_BMS_SUPPLYH_BMS02 3 "DEM_INVALID" 2 "DEM_FAILED" 1 "DEM_PASSED" 0 "DEM_NOTTESTED" ;
VAL_ 1089 DEM052_SAFETYSPI_FAIL_BMS02 3 "DEM_INVALID" 2 "DEM_FAILED" 1 "DEM_PASSED" 0 "DEM_NOTTESTED" ;
VAL_ 1089 DEM053_WATCHDOG_ERRORPIN_BMS02 3 "DEM_INVALID" 2 "DEM_FAILED" 1 "DEM_PASSED" 0 "DEM_NOTTESTED" ;
VAL_ 1089 DEM054_SAFESTATE_TRIGGERED_BMS02 3 "DEM_INVALID" 2 "DEM_FAILED" 1 "DEM_PASSED" 0 "DEM_NOTTESTED" ;
VAL_ 1089 DEM055_DEBUG_CMND_ACTIVE_BMS02 3 "DEM_INVALID" 2 "DEM_FAILED" 1 "DEM_PASSED" 0 "DEM_NOTTESTED" ;
VAL_ 1089 DEM056_CRASH_CAN_BMS02 3 "DEM_INVALID" 2 "DEM_FAILED" 1 "DEM_PASSED" 0 "DEM_NOTTESTED" ;
VAL_ 1089 DEM057_ISO_EXT_STRAT_4_BMS02 3 "DEM_INVALID" 2 "DEM_FAILED" 1 "DEM_PASSED" 0 "DEM_NOTTESTED" ;
VAL_ 1089 DEM058_ISO_EXT_RES_ERR_BMS02 3 "DEM_INVALID" 2 "DEM_FAILED" 1 "DEM_PASSED" 0 "DEM_NOTTESTED" ;
VAL_ 1089 DEM059_ISO_EXT_RES_WARN_BMS02 3 "DEM_INVALID" 2 "DEM_FAILED" 1 "DEM_PASSED" 0 "DEM_NOTTESTED" ;
VAL_ 1089 DEM060_ISO_INT_RES_ERR_BMS02 3 "DEM_INVALID" 2 "DEM_FAILED" 1 "DEM_PASSED" 0 "DEM_NOTTESTED" ;
VAL_ 1089 DEM061_ISO_INT_RES_WARN_BMS02 3 "DEM_INVALID" 2 "DEM_FAILED" 1 "DEM_PASSED" 0 "DEM_NOTTESTED" ;
VAL_ 1089 DEM062_EMERGENCY_OPERATION_BMS02 3 "DEM_INVALID" 2 "DEM_FAILED" 1 "DEM_PASSED" 0 "DEM_NOTTESTED" ;
VAL_ 1089 DEM063_ENDOFDRIVE_BMS02 3 "DEM_INVALID" 2 "DEM_FAILED" 1 "DEM_PASSED" 0 "DEM_NOTTESTED" ;
VAL_ 1153 DEM064_STRINGV_IMBALANCE_BMS02 3 "DEM_INVALID" 2 "DEM_FAILED" 1 "DEM_PASSED" 0 "DEM_NOTTESTED" ;
VAL_ 1153 DEM065_STRING_FAULT_BMS02 3 "DEM_INVALID" 2 "DEM_FAILED" 1 "DEM_PASSED" 0 "DEM_NOTTESTED" ;
VAL_ 1153 DEM066_ESS_FAULT_BMS02 3 "DEM_INVALID" 2 "DEM_FAILED" 1 "DEM_PASSED" 0 "DEM_NOTTESTED" ;
VAL_ 1153 DEM067_ISO_EXT_STRAT_3_BMS02 3 "DEM_INVALID" 2 "DEM_FAILED" 1 "DEM_PASSED" 0 "DEM_NOTTESTED" ;
VAL_ 1153 DEM068_MODULE_COUNT_INVALI_BMS02 3 "DEM_INVALID" 2 "DEM_FAILED" 1 "DEM_PASSED" 0 "DEM_NOTTESTED" ;
VAL_ 1153 DEM069_PT_MIA_BMS02 3 "DEM_INVALID" 2 "DEM_FAILED" 1 "DEM_PASSED" 0 "DEM_NOTTESTED" ;
VAL_ 1153 DEM070_BMSMIA_STRNGMSTR_01_BMS02 3 "DEM_INVALID" 2 "DEM_FAILED" 1 "DEM_PASSED" 0 "DEM_NOTTESTED" ;
VAL_ 1153 DEM071_BMSMIA_STRNGMSTR_05_BMS02 3 "DEM_INVALID" 2 "DEM_FAILED" 1 "DEM_PASSED" 0 "DEM_NOTTESTED" ;
VAL_ 1153 DEM072_BMSMIA_STRNGMSTR_09_BMS02 3 "DEM_INVALID" 2 "DEM_FAILED" 1 "DEM_PASSED" 0 "DEM_NOTTESTED" ;
VAL_ 1153 DEM073_BMSMIA_STRNGMSTR_13_BMS02 3 "DEM_INVALID" 2 "DEM_FAILED" 1 "DEM_PASSED" 0 "DEM_NOTTESTED" ;
VAL_ 1153 DEM074_BMSMIA_STRNGMSTR_17_BMS02 3 "DEM_INVALID" 2 "DEM_FAILED" 1 "DEM_PASSED" 0 "DEM_NOTTESTED" ;
VAL_ 1153 DEM075_BMSMIA_STRNGMSTR_21_BMS02 3 "DEM_INVALID" 2 "DEM_FAILED" 1 "DEM_PASSED" 0 "DEM_NOTTESTED" ;
VAL_ 1153 DEM076_BMSMIA_STRNGMSTR_25_BMS02 3 "DEM_INVALID" 2 "DEM_FAILED" 1 "DEM_PASSED" 0 "DEM_NOTTESTED" ;
VAL_ 1153 DEM077_BMSMIA_STRNGMSTR_29_BMS02 3 "DEM_INVALID" 2 "DEM_FAILED" 1 "DEM_PASSED" 0 "DEM_NOTTESTED" ;
VAL_ 1153 DEM078_BMSMIA_STRNGMSTR_33_BMS02 3 "DEM_INVALID" 2 "DEM_FAILED" 1 "DEM_PASSED" 0 "DEM_NOTTESTED" ;
VAL_ 1153 DEM079_BMSMIA_STRNGMSTR_37_BMS02 3 "DEM_INVALID" 2 "DEM_FAILED" 1 "DEM_PASSED" 0 "DEM_NOTTESTED" ;
VAL_ 1153 DEM080_BMSMIA_STRNGMSTR_41_BMS02 3 "DEM_INVALID" 2 "DEM_FAILED" 1 "DEM_PASSED" 0 "DEM_NOTTESTED" ;
VAL_ 1153 DEM081_BMSMIA_STRNGMSTR_45_BMS02 3 "DEM_INVALID" 2 "DEM_FAILED" 1 "DEM_PASSED" 0 "DEM_NOTTESTED" ;
VAL_ 1153 DEM082_BMSMIA_STRNGMSTR_49_BMS02 3 "DEM_INVALID" 2 "DEM_FAILED" 1 "DEM_PASSED" 0 "DEM_NOTTESTED" ;
VAL_ 1153 DEM083_BMSMIA_STRNGMSTR_53_BMS02 3 "DEM_INVALID" 2 "DEM_FAILED" 1 "DEM_PASSED" 0 "DEM_NOTTESTED" ;
VAL_ 1153 DEM084_BMSMIA_STRNGMSTR_57_BMS02 3 "DEM_INVALID" 2 "DEM_FAILED" 1 "DEM_PASSED" 0 "DEM_NOTTESTED" ;
VAL_ 1153 DEM085_BMSMIA_STRNGMSTR_61_BMS02 3 "DEM_INVALID" 2 "DEM_FAILED" 1 "DEM_PASSED" 0 "DEM_NOTTESTED" ;
VAL_ 1153 DEM086_ESSCURRENT_SHORT_BMS02 3 "DEM_INVALID" 2 "DEM_FAILED" 1 "DEM_PASSED" 0 "DEM_NOTTESTED" ;
VAL_ 1153 DEM087_PT_MIA_SHUTDOWN_BMS02 3 "DEM_INVALID" 2 "DEM_FAILED" 1 "DEM_PASSED" 0 "DEM_NOTTESTED" ;
VAL_ 1153 DEM088_OUTLET_NTC_HI_BMS02 3 "DEM_INVALID" 2 "DEM_FAILED" 1 "DEM_PASSED" 0 "DEM_NOTTESTED" ;
VAL_ 1153 DEM089_OUTLET_NTC_LO_BMS02 3 "DEM_INVALID" 2 "DEM_FAILED" 1 "DEM_PASSED" 0 "DEM_NOTTESTED" ;
VAL_ 1153 DEM090_BMSMIA_ESSMASTER_BMS02 3 "DEM_INVALID" 2 "DEM_FAILED" 1 "DEM_PASSED" 0 "DEM_NOTTESTED" ;
VAL_ 1153 DEM091_PCHG_RES_OVERHEAT_BMS02 3 "DEM_INVALID" 2 "DEM_FAILED" 1 "DEM_PASSED" 0 "DEM_NOTTESTED" ;
VAL_ 1153 DEM092_BMSMIA_STRNGSLAVE_0_BMS02 3 "DEM_INVALID" 2 "DEM_FAILED" 1 "DEM_PASSED" 0 "DEM_NOTTESTED" ;
VAL_ 1153 DEM093_BMSMIA_STRNGSLAVE_1_BMS02 3 "DEM_INVALID" 2 "DEM_FAILED" 1 "DEM_PASSED" 0 "DEM_NOTTESTED" ;
VAL_ 1153 DEM094_BMSMIA_STRNGSLAVE_2_BMS02 3 "DEM_INVALID" 2 "DEM_FAILED" 1 "DEM_PASSED" 0 "DEM_NOTTESTED" ;
VAL_ 1153 DEM095_BMSMIA_STRNGSLAVE_3_BMS02 3 "DEM_INVALID" 2 "DEM_FAILED" 1 "DEM_PASSED" 0 "DEM_NOTTESTED" ;
